VERSION ""

NS_ :

BS_:

BU_: WCM4 WCM3 WCM2 WCM VPM VLM VKM VICM VECM VDM VCU_RTOS_ETH VCU_ENTRY_ETH VCU_AGVM_ETH VCU UVM UPM TIM TEST_TOOL_1 TCP_ETH TCP TCM TCCM SRR_SRR_ETH SRR_SRR SRR_SLR_ETH SRR_SLR SRR_RR SRR_RF_ETH SRR_RF SRR_LR_CR SRR_LF_ETH SRR_LF SIB SDM SCL SBZA_R SBZA_L SBM SAM_RR SAM_RF SAM_LR SAM_LF SAM_BH SADS RadioLow_ETH RadioLow RSI_RTOS_ETH RSI RDCM PTM PLCM PFCM PDR_ETH PDR PCM PA ODS2 ODS NVM MTCM_R MTCM_L MSM_RR MSM_P MSM_LR MSM_D MSB2 MSB1 MRCM_R MRCM_L MFC LRR_RR_ETH LRR_LR_ETH LRR_CF_ETH LRR LRL_CF_ETH LIB_48V LIB1 IPC_INT IPC_GP IPC ICS_Info ICCM HVAC_FP_R HVAC_FP_F HUD_CAN HDLM FPI_RTOS_ETH FPI FOPM FCM_LC FCM EPSb EPS_1 EPSRAb EPSRAa EPS EOCM_HC_Superset EOCM_HCP2 EOCM ELM ECP_X1 ECP_S2 ECP_S ECP_MC ECP_H3 ECP_H2 ECP_H1 ECP_E ECM EBCM DMS DEFC DCM CSM_ETH CSM_AV CSM CGM_OTA_ETH CGM BSM_MH BSM_HEV BSM BCM ARS ARB APA AOS AMP ALC AHS AHL_AFL ADIMb ADIMa ACP2_MCU

BO_ 1515 PDU_5062: 8 RadioLow
 SG_ TAC_AudConctOutcm : 3|4@0+ (1,0) [0|15] "" CGM,TCP
 SG_ TAC_AudChConctStat : 7|4@0+ (1,0) [0|15] "" CGM,TCP
 SG_ TDOSWCCSR_ChgSetReq : 10|3@0+ (1,0) [0|7] "" CGM
 SG_ InfoSysStat : 15|5@0+ (1,0) [0|19] "" AMP,CGM,FPI,HVAC_FP_F,HVAC_FP_R,ICS_Info,PDR,MFC,PLCM,RSI,TCP,IPC,IPC_INT,WCM,WCM2,WCM3,WCM4
 SG_ AutoMemRclCstChgSetReq : 18|3@0+ (1,0) [0|7] "" CGM
 SG_ AdpLghtRspTypCstChgSetReq : 21|3@0+ (1,0) [0|7] "" CGM
 SG_ TDOSWCCSR_IncSwAct : 22|1@0+ (1,0) [0|1] "" CGM
 SG_ TDOSWCCSR_DecSwAct : 23|1@0+ (1,0) [0|1] "" CGM
 SG_ EsyExtCstChgSetReq : 25|3@0+ (1,0) [0|7] "" CGM
 SG_ DrvrAlrtTypCstChgStReq : 28|3@0+ (1,0) [0|7] "" CGM
 SG_ CrgBedVwAutoLgtCstChgSetReq : 31|3@0+ (1,0) [0|2] "" CGM
 SG_ FrwdImpMtgnOpSlctCstChgSetReq : 32|3@0+ (1,0) [0|7] "" CGM
 SG_ FrtRdHgtGPSCstChngSetReq : 35|3@0+ (1,0) [0|7] "" CGM
 SG_ FrntPCMRspTypCstChgSetReq : 38|3@0+ (1,0) [0|7] "" CGM
 SG_ GoNotfrCstChgSetReq : 42|3@0+ (1,0) [0|7] "" CGM
 SG_ GlrFrHgBmRspTypCstChgSetReq : 45|3@0+ (1,0) [0|7] "" CGM
 SG_ PhnLtInVehCstChgSetReq : 49|3@0+ (1,0) [0|7] "" WCM
 SG_ LtRtHnTrCstChgSetReq : 52|3@0+ (1,0) [0|7] "" CGM
 SG_ JckKnfDtnCstChgSetReq : 55|3@0+ (1,0) [0|2] "" CGM
 SG_ APACrssBckInSftBtnStat : 56|1@0+ (1,0) [0|1] "" CGM
 SG_ PrkAsstTrHtchPsntCstChgSetReq : 59|3@0+ (1,0) [0|7] "" CGM
 SG_ PrkAsstOnOffCstChgSetReq : 62|3@0+ (1,0) [0|3] "" CGM

BO_ 1516 PDU_5063: 8 RadioLow
 SG_ RrCrsTrfcAlrtCstChngSetReq : 1|3@0+ (1,0) [0|7] "" CGM
 SG_ RnngBrdManDplyCstChgSetReq : 4|3@0+ (1,0) [0|6] "" CGM
 SG_ RnngBrdAutoDplyCstChgSetReq : 7|3@0+ (1,0) [0|6] "" CGM
 SG_ SBZAlrtCstChngSetReq : 8|3@0+ (1,0) [0|7] "" CGM
 SG_ RrVwPrkAstSymCstChgSetReq : 11|3@0+ (1,0) [0|7] "" CGM
 SG_ RrPCMRspTypCstChgSetReq : 14|3@0+ (1,0) [0|7] "" CGM
 SG_ SrrndVwLghtCstChgSetReq : 18|3@0+ (1,0) [0|7] "" CGM
 SG_ SelUlkCstChgSetReq : 21|3@0+ (1,0) [0|7] "" CGM
 SG_ TnDrvSpdLmtCstChgStReq : 25|3@0+ (1,0) [0|7] "" CGM
 SG_ StBltTghtngCstChgSetReq : 28|3@0+ (1,0) [0|7] "" CGM
 SG_ StBltShfIntlkCstChgSetReq : 31|3@0+ (1,0) [0|7] "" CGM
 SG_ TrlrMirVidEnblCstChgSetReq : 32|3@0+ (1,0) [0|2] "" CGM
 SG_ TrffcLgtAsstCstChgSetReq : 35|3@0+ (1,0) [0|7] "" CGM
 SG_ TnDrvStBltShfIntlkCstChgSetReq : 38|3@0+ (1,0) [0|7] "" CGM
 SG_ VehLctrLtsCstChgSetReq : 42|3@0+ (1,0) [0|7] "" CGM
 SG_ TrlrMirVidGdlnsCstChgSetReq : 45|3@0+ (1,0) [0|2] "" CGM
 SG_ APALftSftBtnStat : 48|1@0+ (1,0) [0|1] "" CGM
 SG_ APAFcStatCSM : 49|1@0+ (1,0) [0|1] "" CGM
 SG_ APAExtPrkSftBtnStat : 50|1@0+ (1,0) [0|1] "" CGM
 SG_ ElvtdIdlCstChgSetReq : 52|2@0+ (1,0) [0|2] "" CGM
 SG_ WlkAwyLckCstChgSetReq : 55|3@0+ (1,0) [0|7] "" CGM
 SG_ TimeDispFormat : 57|1@0+ (1,0) [0|1] "" CGM,ICS_Info,PDR,IPC,IPC_INT
 SG_ RstrCstDfltReq : 58|1@0+ (1,0) [0|1] "" CGM,WCM,WCM2,WCM3,WCM4
 SG_ RFStStsDispActv : 59|1@0+ (1,0) [0|1] "" CGM
 SG_ LFStStsDispActv : 60|1@0+ (1,0) [0|1] "" CGM
 SG_ APASrchSftBtnStat : 61|1@0+ (1,0) [0|1] "" CGM
 SG_ APARghtSftBtnStat : 62|1@0+ (1,0) [0|1] "" CGM
 SG_ APAPrllPrkSftBtnStat : 63|1@0+ (1,0) [0|1] "" CGM

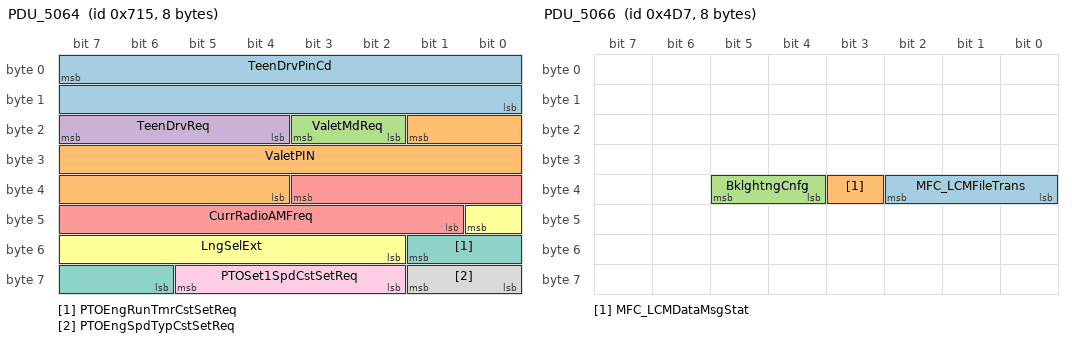
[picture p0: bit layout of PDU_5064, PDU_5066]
BO_ 1813 PDU_5064: 8 RadioLow
 SG_ TeenDrvPinCd : 7|16@0+ (1,0) [0|65535] "" CGM,TCP
 SG_ ValetPIN : 17|14@0+ (1,0) [0|16383] "" CGM
 SG_ ValetMdReq : 19|2@0+ (1,0) [0|2] "" CGM
 SG_ TeenDrvReq : 23|4@0+ (1,0) [0|8] "" CGM,TCP
 SG_ CurrRadioAMFreq : 35|11@0+ (1,0) [0|2047] "KHz" CGM
 SG_ LngSelExt : 40|7@0+ (1,0) [0|43] "" CGM,FPI,PDR,RSI,TCP,IPC,IPC_INT,VCU
 SG_ PTOEngRunTmrCstSetReq : 49|4@0+ (1,0) [0|15] "" CGM
 SG_ PTOEngSpdTypCstSetReq : 57|2@0+ (1,0) [0|2] "" CGM
 SG_ PTOSet1SpdCstSetReq : 61|4@0+ (1,0) [0|15] "" CGM

BO_ 1252 PDU_5065: 6 RadioLow
 SG_ PTOStndbySpdCstSetReq : 0|3@0+ (1,0) [0|7] "" CGM
 SG_ LnChgAlrtCstChngSetReq : 3|3@0+ (1,0) [0|7] "" CGM
 SG_ PTOSet2SpdCstSetReq : 7|4@0+ (1,0) [0|15] "" CGM
 SG_ TCP_LCMFileTrans : 10|3@0+ (1,0) [0|4] "" TCP
 SG_ PTOTpStpSpdCstSetReq : 13|3@0+ (1,0) [0|7] "" CGM
 SG_ TCP_LCMDataMsgStat : 18|1@0+ (1,0) [0|1] "" TCP
 SG_ CamVidICS_DispAct : 19|1@0+ (1,0) [0|1] "" CGM
 SG_ TrlrLtngSeqReq : 21|2@0+ (1,0) [0|2] "" CGM
 SG_ PTOModeCstSetReq : 23|2@0+ (1,0) [0|2] "" CGM
 SG_ VwgVwprtTopDnVwSeltn : 25|3@0+ (1,0) [0|2] "" CGM
 SG_ VwgVwprtZoomBtnSeltd : 26|1@0+ (1,0) [0|1] "" CGM
 SG_ VwgVwprtNtfnFcsReqd : 27|1@0+ (1,0) [0|1] "" CGM
 SG_ VwgVwprtNtfnDsmsReqd : 28|1@0+ (1,0) [0|1] "" CGM
 SG_ TrfcJamAsstVirtCtlReq : 33|2@0+ (1,0) [0|2] "" CGM
 SG_ DrvrSeltdSpdLmtrVirtCtlReqd : 36|1@0+ (1,0) [0|1] "" CGM
 SG_ DrvrSeltdSpdLmtrVirtCtlReq : 38|2@0+ (1,0) [0|3] "" CGM
 SG_ DMBlkhdDrAutoClsTmCstChgSetReq : 45|3@0+ (1,0) [0|3] "" CGM

BO_ 1239 PDU_5066: 8 RadioLow
 SG_ MFC_LCMFileTrans : 34|3@0+ (1,0) [0|4] "" MFC
 SG_ MFC_LCMDataMsgStat : 35|1@0+ (1,0) [0|1] "" MFC
 SG_ BklghtngCnfg : 37|2@0+ (1,0) [0|2] "" MFC

BO_ 706 PDU_5067: 2 RadioLow
 SG_ WCM_LCMDataMsgStat : 4|1@0+ (1,0) [0|1] "" WCM
 SG_ WCM_LCMFileTrans : 7|3@0+ (1,0) [0|4] "" WCM

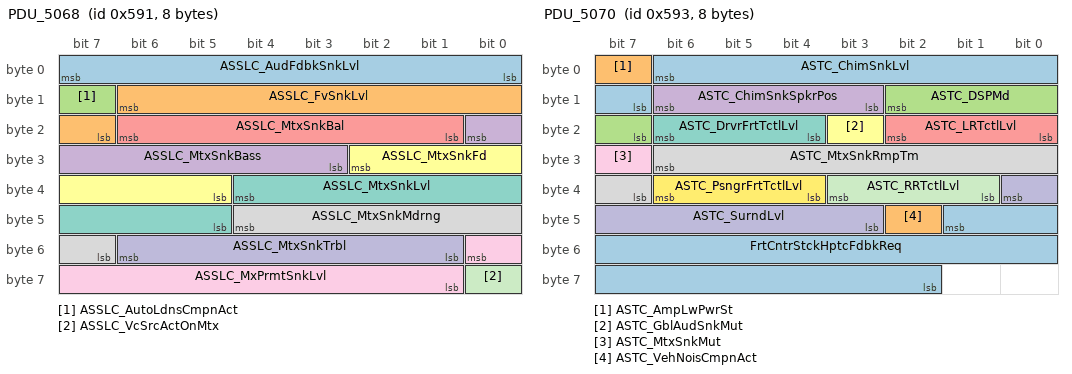
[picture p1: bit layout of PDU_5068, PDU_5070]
BO_ 1425 PDU_5068: 8 CSM
 SG_ ASSLC_AudFdbkSnkLvl : 7|8@0+ (0.5,-127.5) [-127.5|0] "dB" AMP
 SG_ ASSLC_FvSnkLvl : 14|8@0+ (0.5,-127.5) [-127.5|0] "dB" AMP
 SG_ ASSLC_AutoLdnsCmpnAct : 15|1@0+ (1,0) [0|1] "" AMP
 SG_ ASSLC_MtxSnkBass : 16|6@0- (1,0) [-32|31] "" AMP
 SG_ ASSLC_MtxSnkBal : 22|6@0- (1,0) [-32|31] "" AMP
 SG_ ASSLC_MtxSnkFd : 26|6@0- (1,0) [-32|31] "" AMP
 SG_ ASSLC_MtxSnkLvl : 36|8@0+ (0.5,-127.5) [-127.5|0] "dB" AMP
 SG_ ASSLC_MtxSnkMdrng : 44|6@0- (1,0) [-32|31] "" AMP
 SG_ ASSLC_MxPrmtSnkLvl : 48|8@0+ (0.5,-127.5) [-127.5|0] "dB" AMP
 SG_ ASSLC_MtxSnkTrbl : 54|6@0- (1,0) [-32|31] "" AMP
 SG_ ASSLC_VcSrcActOnMtx : 56|1@0+ (1,0) [0|1] "" AMP

BO_ 1426 PDU_5069: 8 CSM
 SG_ ZALC_LRMtxSnkLvl : 7|8@0+ (0.5,-127.5) [-127.5|0] "dB" AMP
 SG_ ZALC_LRMtxSnkRmpTm : 14|8@0+ (5,0) [0|1275] "msec" AMP
 SG_ ZALC_LRMtxSnkMut : 15|1@0+ (1,0) [0|1] "" AMP
 SG_ ZALC_MltZnMixPrmtAudRR : 16|1@0+ (1,0) [0|1] "" AMP
 SG_ ZALC_MltZnMixPrmtAudPsngrFrt : 17|1@0+ (1,0) [0|1] "" AMP
 SG_ ZALC_MltZnMixPrmtAudLR : 18|1@0+ (1,0) [0|1] "" AMP
 SG_ ZALC_MltZnMixPrmtAudDrvrFrt : 19|1@0+ (1,0) [0|1] "" AMP
 SG_ ZALC_MltZnAudFtrStat : 22|3@0+ (1,0) [0|3] "" AMP
 SG_ ZALC_PsngrFrtMtxSnkLvl : 31|8@0+ (0.5,-127.5) [-127.5|0] "dB" AMP
 SG_ ZALC_PsngrFrtMtxSnkRmpTm : 38|8@0+ (5,0) [0|1275] "msec" AMP
 SG_ ZALC_PsngrFrtMtxSnkMut : 39|1@0+ (1,0) [0|1] "" AMP
 SG_ ZALC_RRMtxSnkLvl : 46|8@0+ (0.5,-127.5) [-127.5|0] "dB" AMP
 SG_ ZALC_RRMtxSnkRmpTm : 53|8@0+ (5,0) [0|1275] "msec" AMP
 SG_ ZALC_RRMtxSnkMut : 54|1@0+ (1,0) [0|1] "" AMP
 SG_ FrtCntrStckOptDskDrvDckStat : 58|3@0+ (1,0) [0|7] "" ICS_Info,TCP
 SG_ ZALC_VcSrcActvOnRRMtx : 59|1@0+ (1,0) [0|1] "" AMP
 SG_ ZALC_VcSrcActvOnPsngrFrtMtx : 60|1@0+ (1,0) [0|1] "" AMP
 SG_ ZALC_VcSrcActvOnLRMtx : 61|1@0+ (1,0) [0|1] "" AMP

BO_ 1427 PDU_5070: 8 CSM
 SG_ ASTC_ChimSnkLvl : 6|8@0+ (0.5,-127.5) [-127.5|0] "dB" AMP
 SG_ ASTC_AmpLwPwrSt : 7|1@0+ (1,0) [0|1] "" AMP
 SG_ ASTC_DSPMd : 10|4@0+ (1,0) [0|15] "" AMP
 SG_ ASTC_ChimSnkSpkrPos : 14|4@0+ (1,0) [0|15] "" AMP
 SG_ ASTC_LRTctlLvl : 18|3@0+ (1,0) [0|7] "Counts" AMP
 SG_ ASTC_GblAudSnkMut : 19|1@0+ (1,0) [0|1] "" AMP
 SG_ ASTC_DrvrFrtTctlLvl : 22|3@0+ (1,0) [0|7] "Counts" AMP
 SG_ ASTC_MtxSnkRmpTm : 30|8@0+ (5,0) [0|1275] "ms" AMP
 SG_ ASTC_MtxSnkMut : 31|1@0+ (1,0) [0|1] "" AMP
 SG_ ASTC_SurndLvl : 32|6@0- (1,0) [-32|31] "" AMP
 SG_ ASTC_RRTctlLvl : 35|3@0+ (1,0) [0|7] "Counts" AMP
 SG_ ASTC_PsngrFrtTctlLvl : 38|3@0+ (1,0) [0|7] "Counts" AMP
 SG_ FrtCntrStckHptcFdbkReq : 41|16@0+ (1,0) [0|15] "" ICS_Info
 SG_ ASTC_VehNoisCmpnAct : 42|1@0+ (1,0) [0|1] "" AMP

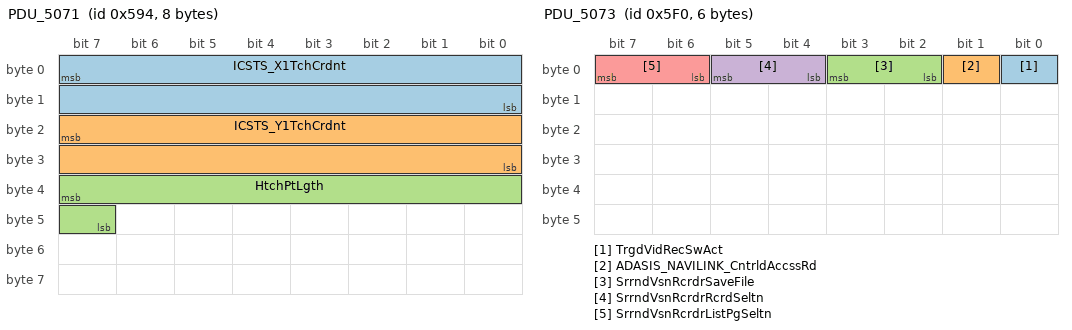
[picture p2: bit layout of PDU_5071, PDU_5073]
BO_ 1428 PDU_5071: 8 CSM
 SG_ ICSTS_X1TchCrdnt : 7|16@0+ (0.001526,0) [0|100.006] "%" CGM,RadioLow
 SG_ ICSTS_Y1TchCrdnt : 23|16@0+ (0.001526,0) [0|100.006] "%" CGM,RadioLow
 SG_ HtchPtLgth : 39|9@0+ (1,0) [0|511] "cm" CGM

BO_ 1519 PDU_5072: 8 CSM
 SG_ VwgBowlVwAngSeltn : 7|9@0+ (1,0) [0|511] "Degree" CGM
 SG_ ADASIS_NAVILINK_DgtlMpEfSpdLm : 8|6@0+ (1,0) [0|31] "" CGM
 SG_ ADASIS_NAVILINK_CntryCd : 14|6@0+ (1,0) [0|51] "" CGM
 SG_ VwgVwprtSeltn : 18|5@0+ (1,0) [0|24] "" CGM
 SG_ SrrndVsnRcrdrListFcs : 25|4@0+ (1,0) [0|11] "" CGM
 SG_ ADASIS_NAVILINK_DgtlMpPsngRst : 29|4@0+ (1,0) [0|7] "" CGM
 SG_ ADASIS_NAVILINK_DgMpCnSpdLmTyp : 33|3@0+ (1,0) [0|7] "" CGM
 SG_ SrrndVsnRcrdrVwprtSeltn : 37|4@0+ (1,0) [0|8] "" CGM
 SG_ SrrndVsnRcrdrFileSeltn : 40|3@0+ (1,0) [0|6] "" CGM
 SG_ SrrndVsnRcrdrFileDeltn : 43|3@0+ (1,0) [0|6] "" CGM
 SG_ PFASndSeltnCstChgSetReq : 46|3@0+ (1,0) [0|7] "" CGM
 SG_ SrrndVsnRcrdrPlybkSeltn : 50|3@0+ (1,0) [0|5] "" CGM
 SG_ SrrndVsnRcrdrPlybkFcs : 53|3@0+ (1,0) [0|6] "" CGM
 SG_ ADASIS_NAVILINK_BldUpFlg : 56|1@0+ (1,0) [0|1] "" CGM
 SG_ PASftBtnSeltdStatRw : 58|2@0+ (1,0) [0|3] "" CGM
 SG_ APASftBtnSeltdStatRw : 60|2@0+ (1,0) [0|3] "" CGM
 SG_ VGS_TrlrActv : 61|1@0+ (1,0) [0|1] "" CGM
 SG_ VGS_DynActv : 62|1@0+ (1,0) [0|1] "" CGM
 SG_ VGS_CurbVwActv : 63|1@0+ (1,0) [0|1] "" CGM

BO_ 1520 PDU_5073: 6 CSM
 SG_ TrgdVidRecSwAct : 0|1@0+ (1,0) [0|1] "" CGM
 SG_ ADASIS_NAVILINK_CntrldAccssRd : 1|1@0+ (1,0) [0|1] "" CGM
 SG_ SrrndVsnRcrdrSaveFile : 3|2@0+ (1,0) [0|2] "" CGM
 SG_ SrrndVsnRcrdrRcrdSeltn : 5|2@0+ (1,0) [0|2] "" CGM
 SG_ SrrndVsnRcrdrListPgSeltn : 7|2@0+ (1,0) [0|3] "" CGM

BO_ 1814 PDU_5074: 8 CSM
 SG_ ONPC_DprtrHrOfDyReq : 4|5@0+ (1,0) [0|31] "h" CGM
 SG_ ONPC_DprtrDyOfWkReq : 7|3@0+ (1,0) [0|7] "" CGM
 SG_ ONPC_Req : 9|2@0+ (1,0) [0|2] "" CGM
 SG_ ONPC_DprtrMinOfHrReq : 15|6@0+ (1,0) [0|63] "min" CGM
 SG_ DAPR_CtlDir : 16|3@0+ (1,0) [0|7] "" AMP
 SG_ ONPC_TgtChrgLvlReq : 23|7@0+ (1,0) [0|127] "%" CGM
 SG_ DAPR_CtlDist : 29|9@0+ (1,0) [0|511] "" AMP
 SG_ DAPR_CurrPrmt : 32|1@0+ (1,0) [0|1] "" AMP
 SG_ DAPR_CtlZn : 36|4@0+ (1,0) [0|15] "" AMP
 SG_ LVMAVC_RmtEnbl : 42|3@0+ (1,0) [0|2] "" PDR
 SG_ LVMAVC_PrmtAudResp : 44|2@0+ (1,0) [0|1] "" PDR
 SG_ LVMAVC_ApplID : 47|3@0+ (1,0) [0|4] "" PDR
 SG_ LVMAVC_StreoAudResp : 48|2@0+ (1,0) [0|1] "" PDR
 SG_ LVMAVC_SpchRcgnAval : 50|2@0+ (1,0) [0|1] "" PDR
 SG_ LVMAVC_RmtSpchRcgnID : 53|3@0+ (1,0) [0|3] "" PDR
 SG_ LVMAVC_RmtSpchRcgnActn : 55|2@0+ (1,0) [0|3] "" PDR
 SG_ OvrrdNextPlndCbnPrcndtngReq : 57|2@0+ (1,0) [0|2] "" CGM
 SG_ RtSdFrtZnAudVolCtlOfst : 62|5@0- (1,0) [-16|15] "" AMP

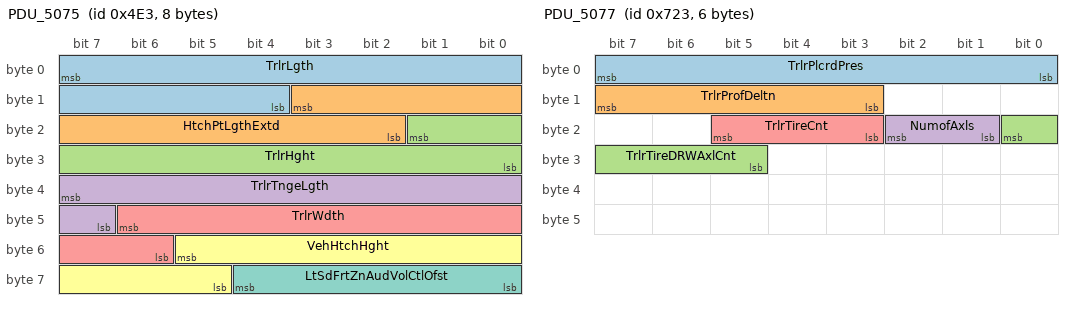
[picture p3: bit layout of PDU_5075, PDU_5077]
BO_ 1251 PDU_5075: 8 CSM
 SG_ TrlrLgth : 7|12@0+ (1,0) [0|4095] "cm" CGM
 SG_ HtchPtLgthExtd : 11|10@0+ (1,1) [1|1024] "cm" CGM
 SG_ TrlrHght : 17|10@0+ (1,0) [0|1023] "cm" CGM
 SG_ TrlrTngeLgth : 39|9@0+ (1,0) [0|511] "cm" CGM
 SG_ TrlrWdth : 46|9@0+ (1,0) [0|511] "cm" CGM
 SG_ VehHtchHght : 53|9@0+ (0.25,0) [0|127.75] "cm" CGM
 SG_ LtSdFrtZnAudVolCtlOfst : 60|5@0- (1,0) [-16|15] "" AMP

BO_ 1815 PDU_5076: 8 CSM
 SG_ VehHtchLgth : 7|9@0+ (0.25,0) [0|127.75] "cm" CGM
 SG_ HMIInCarVcCommCtl : 8|3@0+ (1,0) [0|6] "" AMP
 SG_ AutoTrnspHdActvnCstChgSetReq : 11|3@0+ (1,0) [0|2] "" CGM
 SG_ AutoLnChgCstChgSetReq : 14|3@0+ (1,0) [0|4] "" CGM
 SG_ ChrgPwrLossAlrtCstSetReq : 16|2@0+ (1,0) [0|2] "" CGM
 SG_ ChrgDatReq : 18|2@0+ (1,0) [0|3] "" CGM
 SG_ LocBsdChrgPstnMdfnReq : 21|3@0+ (1,0) [0|4] "" CGM
 SG_ TrlrHtchTyp : 24|2@0+ (1,0) [0|3] "" CGM
 SG_ LocBsdChrgCstSetReq : 26|2@0+ (1,0) [0|2] "" CGM
 SG_ FrtCntrStckVidInSel : 28|2@0+ (1,0) [0|2] "" ICS_Info,PDR,TCP
 SG_ ChrgSysAudblIndCstSetReq : 30|2@0+ (1,0) [0|2] "" CGM
 SG_ Frt360CamSwAct : 32|1@0+ (1,0) [0|1] "" CGM
 SG_ DrvrSeltdTrlrPrsnt : 33|1@0+ (1,0) [0|1] "" CGM
 SG_ DirAudPrmtRndrngEnbld : 34|1@0+ (1,0) [0|1] "" AMP
 SG_ TrlrTyp : 36|2@0+ (1,0) [0|2] "" CGM
 SG_ TrlrStatTowHaulModeOvrrd : 38|2@0+ (1,0) [0|3] "" CGM
 SG_ TrlrAppAux1CamPrvwReqd : 40|1@0+ (1,0) [0|1] "" CGM
 SG_ TrlRvsLghtFldEnbld : 41|1@0+ (1,0) [0|1] "" CGM
 SG_ LifetmEleclEngyEconRstReqd : 42|1@0+ (1,0) [0|1] "" CGM
 SG_ HybTripDatRstReqd : 43|1@0+ (1,0) [0|1] "" CGM
 SG_ HndsFrVcCallActv : 44|1@0+ (1,0) [0|1] "" AMP
 SG_ HiVltgBatStopChrgReq : 45|1@0+ (1,0) [0|1] "" CGM
 SG_ FrtZnAudVolSyncCtlOn : 46|1@0+ (1,0) [0|1] "" AMP
 SG_ FrtCntrStckTchCtlrRstCmd : 47|1@0+ (1,0) [0|1] "" ICS_Info,TCP
 SG_ TrlrProfDrvrReqdSeltn : 48|5@0+ (1,0) [0|21] "" CGM
 SG_ VcRcgnSesnActv : 49|1@0+ (1,0) [0|1] "" AMP
 SG_ TrlrTirePresSnsrIDLrnReqd : 50|1@0+ (1,0) [0|1] "" CGM
 SG_ TrlrTirePresProfXferd : 51|1@0+ (1,0) [0|1] "" CGM
 SG_ TrlrThftAlrtEnbld : 52|1@0+ (1,0) [0|1] "" CGM
 SG_ TrlrLghtAlrtEnbld : 53|1@0+ (1,0) [0|1] "" CGM
 SG_ TrlrAppInvsblTrlrPrvwReqd : 54|1@0+ (1,0) [0|1] "" CGM
 SG_ TrlrAppAux2CamPrvwReqd : 55|1@0+ (1,0) [0|1] "" CGM
 SG_ DMSIntnDrvrCstChgSetReq : 59|3@0+ (1,0) [0|2] "" CGM

BO_ 1827 PDU_5077: 6 CSM
 SG_ TrlrPlcrdPres : 7|8@0+ (4,0) [0|1020] "kPaG" CGM,VKM
 SG_ TrlrProfDeltn : 15|5@0+ (1,0) [0|20] "" CGM
 SG_ TrlrTireDRWAxlCnt : 16|4@0+ (1,0) [0|15] "" CGM
 SG_ NumofAxls : 18|2@0+ (1,0) [0|3] "" CGM
 SG_ TrlrTireCnt : 21|3@0+ (1,0) [0|7] "count" CGM

BO_ 1433 PDU_5078: 6 HVAC_FP_F
 SG_ ReqRrClmtApp : 6|1@0+ (1,0) [0|1] "" RadioLow,CSM,CSM_AV,VCU
 SG_ ReqFrtClmtApp : 7|1@0+ (1,0) [0|1] "" RadioLow,CSM,CSM_AV,VCU

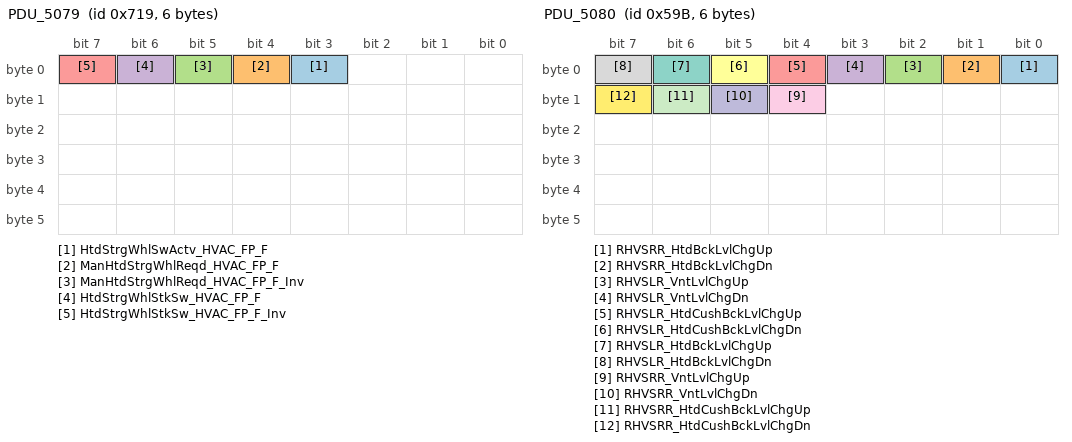
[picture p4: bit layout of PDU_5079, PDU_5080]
BO_ 1817 PDU_5079: 6 HVAC_FP_F
 SG_ HtdStrgWhlSwActv_HVAC_FP_F : 3|1@0+ (1,0) [0|1] "" CGM
 SG_ ManHtdStrgWhlReqd_HVAC_FP_F : 4|1@0+ (1,0) [0|1] "" CGM
 SG_ ManHtdStrgWhlReqd_HVAC_FP_F_Inv : 5|1@0+ (1,0) [0|1] "" CGM
 SG_ HtdStrgWhlStkSw_HVAC_FP_F : 6|1@0+ (1,0) [0|1] "" CGM
 SG_ HtdStrgWhlStkSw_HVAC_FP_F_Inv : 7|1@0+ (1,0) [0|1] "" CGM

BO_ 1435 PDU_5080: 6 HVAC_FP_R
 SG_ RHVSRR_HtdBckLvlChgUp : 0|1@0+ (1,0) [0|1] "" CGM
 SG_ RHVSRR_HtdBckLvlChgDn : 1|1@0+ (1,0) [0|1] "" CGM
 SG_ RHVSLR_VntLvlChgUp : 2|1@0+ (1,0) [0|1] "" CGM
 SG_ RHVSLR_VntLvlChgDn : 3|1@0+ (1,0) [0|1] "" CGM
 SG_ RHVSLR_HtdCushBckLvlChgUp : 4|1@0+ (1,0) [0|1] "" CGM
 SG_ RHVSLR_HtdCushBckLvlChgDn : 5|1@0+ (1,0) [0|1] "" CGM
 SG_ RHVSLR_HtdBckLvlChgUp : 6|1@0+ (1,0) [0|1] "" CGM
 SG_ RHVSLR_HtdBckLvlChgDn : 7|1@0+ (1,0) [0|1] "" CGM
 SG_ RHVSRR_VntLvlChgUp : 12|1@0+ (1,0) [0|1] "" CGM
 SG_ RHVSRR_VntLvlChgDn : 13|1@0+ (1,0) [0|1] "" CGM
 SG_ RHVSRR_HtdCushBckLvlChgUp : 14|1@0+ (1,0) [0|1] "" CGM
 SG_ RHVSRR_HtdCushBckLvlChgDn : 15|1@0+ (1,0) [0|1] "" CGM

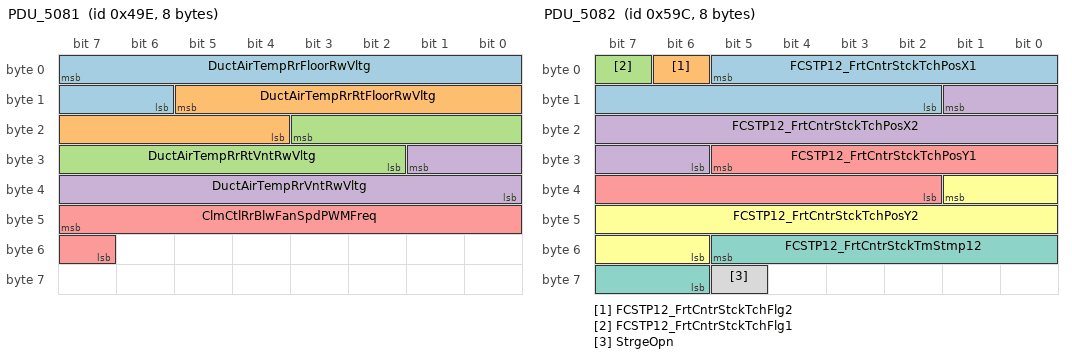
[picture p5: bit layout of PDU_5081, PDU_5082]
BO_ 1182 PDU_5081: 8 HVAC_FP_R
 SG_ DuctAirTempRrFloorRwVltg : 7|10@0+ (0.005,0) [0|5.115] "Volts" CGM
 SG_ DuctAirTempRrRtFloorRwVltg : 13|10@0+ (0.005,0) [0|5.115] "Volts" CGM
 SG_ DuctAirTempRrRtVntRwVltg : 19|10@0+ (0.005,0) [0|5.115] "Volts" CGM
 SG_ DuctAirTempRrVntRwVltg : 25|10@0+ (0.005,0) [0|5.115] "Volts" CGM
 SG_ ClmCtlRrBlwFanSpdPWMFreq : 47|9@0+ (1.56863,0) [0|801.568] "Hz" CGM

BO_ 1436 PDU_5082: 8 ICS_Info
 SG_ FCSTP12_FrtCntrStckTchPosX1 : 5|12@0+ (0.0244141,0) [0|99.9756] "%" PDR,TCP,CSM,CSM_AV,VCU
 SG_ FCSTP12_FrtCntrStckTchFlg2 : 6|1@0+ (1,0) [0|1] "" PDR,TCP,CSM,CSM_AV,VCU
 SG_ FCSTP12_FrtCntrStckTchFlg1 : 7|1@0+ (1,0) [0|1] "" PDR,TCP,CSM,CSM_AV,VCU
 SG_ FCSTP12_FrtCntrStckTchPosX2 : 9|12@0+ (0.0244141,0) [0|99.9756] "%" PDR,TCP,CSM,CSM_AV,VCU
 SG_ FCSTP12_FrtCntrStckTchPosY1 : 29|12@0+ (0.0244141,0) [0|99.9756] "%" PDR,TCP,CSM,CSM_AV,VCU
 SG_ FCSTP12_FrtCntrStckTchPosY2 : 33|12@0+ (0.0244141,0) [0|99.9756] "%" PDR,TCP,CSM,CSM_AV,VCU
 SG_ FCSTP12_FrtCntrStckTmStmp12 : 53|8@0+ (1,0) [0|255] "msec" PDR,TCP,CSM,CSM_AV,VCU
 SG_ StrgeOpn : 61|1@0+ (1,0) [0|1] "" RadioLow,CSM,CSM_AV,VCU

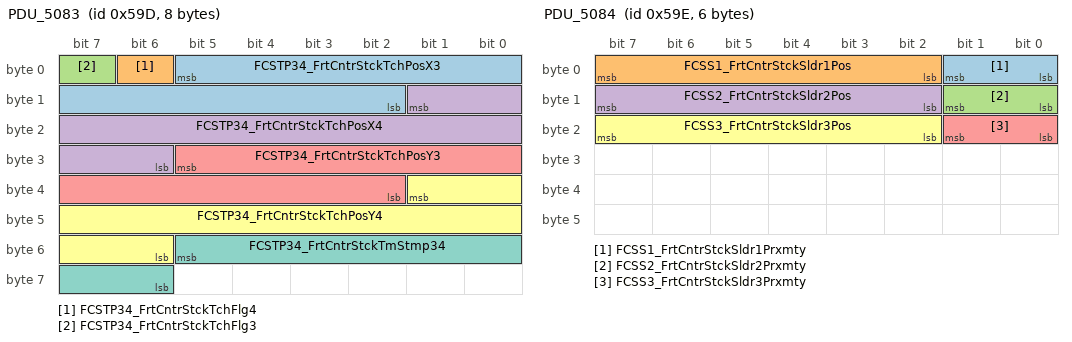
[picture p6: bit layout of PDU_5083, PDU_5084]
BO_ 1437 PDU_5083: 8 ICS_Info
 SG_ FCSTP34_FrtCntrStckTchPosX3 : 5|12@0+ (0.0244141,0) [0|99.9756] "%" PDR,TCP,CSM,CSM_AV,VCU
 SG_ FCSTP34_FrtCntrStckTchFlg4 : 6|1@0+ (1,0) [0|1] "" PDR,TCP,CSM,CSM_AV,VCU
 SG_ FCSTP34_FrtCntrStckTchFlg3 : 7|1@0+ (1,0) [0|1] "" PDR,TCP,CSM,CSM_AV,VCU
 SG_ FCSTP34_FrtCntrStckTchPosX4 : 9|12@0+ (0.0244141,0) [0|99.9756] "%" PDR,TCP,CSM,CSM_AV,VCU
 SG_ FCSTP34_FrtCntrStckTchPosY3 : 29|12@0+ (0.0244141,0) [0|99.9756] "%" PDR,TCP,CSM,CSM_AV,VCU
 SG_ FCSTP34_FrtCntrStckTchPosY4 : 33|12@0+ (0.0244141,0) [0|99.9756] "%" PDR,TCP,CSM,CSM_AV,VCU
 SG_ FCSTP34_FrtCntrStckTmStmp34 : 53|8@0+ (1,0) [0|255] "msec" PDR,TCP,CSM,CSM_AV,VCU

BO_ 1438 PDU_5084: 6 ICS_Info
 SG_ FCSS1_FrtCntrStckSldr1Prxmty : 1|2@0+ (1,0) [0|3] "" TCP,CSM,CSM_AV,VCU
 SG_ FCSS1_FrtCntrStckSldr1Pos : 7|6@0+ (1.5873,0) [0|99.9999] "%" TCP,CSM,CSM_AV,VCU
 SG_ FCSS2_FrtCntrStckSldr2Prxmty : 9|2@0+ (1,0) [0|3] "" TCP,CSM,CSM_AV,VCU
 SG_ FCSS2_FrtCntrStckSldr2Pos : 15|6@0+ (1.5873,0) [0|99.9999] "%" TCP,CSM,CSM_AV,VCU
 SG_ FCSS3_FrtCntrStckSldr3Prxmty : 17|2@0+ (1,0) [0|3] "" TCP,CSM,CSM_AV,VCU
 SG_ FCSS3_FrtCntrStckSldr3Pos : 23|6@0+ (1.5873,0) [0|99.9999] "%" TCP,CSM,CSM_AV,VCU

BO_ 1248 PDU_5085: 6 ICS_Info
 SG_ FrtCntrStckPriVidInLckd : 6|1@0+ (1,0) [0|1] "" PDR,TCP,CSM,CSM_AV
 SG_ FrtCntrStckLVMVidInLckd : 7|1@0+ (1,0) [0|1] "" PDR,TCP,CSM,CSM_AV

BO_ 1818 PDU_5086: 6 IPC
 SG_ AutoTransGrDispdVal : 6|6@0+ (1,0) [0|61] "" CSM,CSM_AV
 SG_ AutoTransGrDispdVal_Inv : 7|1@0+ (1,0) [0|1] "" CSM,CSM_AV

BO_ 930 PDU_5087: 6 IPC
 SG_ ChmMngrStat : 7|12@0+ (1,0) [0|4095] "" CGM,TCP,CSM,CSM_AV

BO_ 723 PDU_5088: 2 IPC
 SG_ JmpStrtReqd : 7|1@0+ (1,0) [0|1] "" CGM

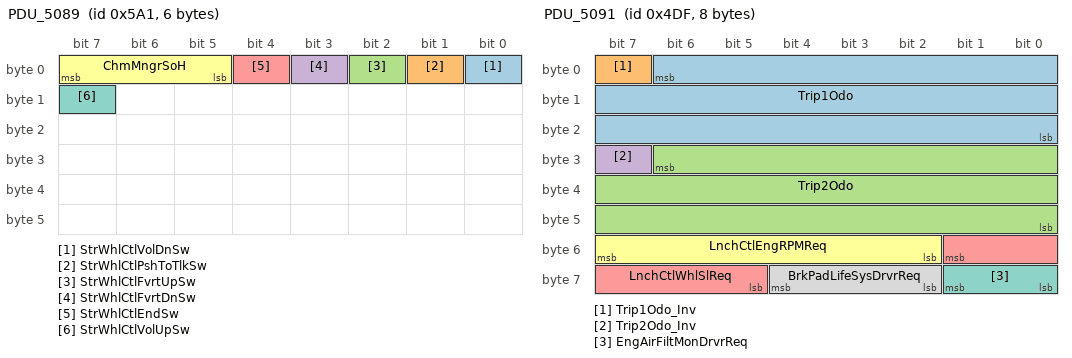
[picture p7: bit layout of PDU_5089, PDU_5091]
BO_ 1441 PDU_5089: 6 IPC
 SG_ StrWhlCtlVolDnSw : 0|1@0+ (1,0) [0|1] "" CGM,RadioLow,CSM,CSM_AV
 SG_ StrWhlCtlPshToTlkSw : 1|1@0+ (1,0) [0|1] "" CGM,RadioLow,CSM,CSM_AV
 SG_ StrWhlCtlFvrtUpSw : 2|1@0+ (1,0) [0|1] "" CGM,RadioLow,CSM,CSM_AV
 SG_ StrWhlCtlFvrtDnSw : 3|1@0+ (1,0) [0|1] "" CGM,RadioLow,CSM,CSM_AV
 SG_ StrWhlCtlEndSw : 4|1@0+ (1,0) [0|1] "" CGM,RadioLow,CSM,CSM_AV
 SG_ ChmMngrSoH : 7|3@0+ (1,0) [0|7] "" RadioLow,CSM,CSM_AV
 SG_ StrWhlCtlVolUpSw : 15|1@0+ (1,0) [0|1] "" CGM,RadioLow,CSM,CSM_AV

BO_ 1522 PDU_5090: 6 IPC
 SG_ HUD_RclCmpt : 0|2@0+ (1,0) [0|2] "" CGM
 SG_ HUD_CustSelActvStat : 1|1@0+ (1,0) [0|1] "" CGM
 SG_ HUD_CustSelActvStat_Inv : 2|1@0+ (1,0) [0|1] "" CGM
 SG_ DispMeasSysExtnd : 4|2@0+ (1,0) [0|3] "" CGM,FPI,PDR,RSI,RadioLow,TCP,VKM,CSM,CSM_AV
 SG_ ClstrAnmStat : 7|3@0+ (1,0) [0|4] "" RadioLow,CSM,CSM_AV
 SG_ PAMutDrvrReq : 8|2@0+ (1,0) [0|2] "" CGM
 SG_ NtVsnVidCntrstUserReq : 10|2@0+ (1,0) [0|3] "" CGM
 SG_ NtVsnVidBrghtnsUserReq : 12|2@0+ (1,0) [0|3] "" CGM
 SG_ IPC_RunCrnkInpActv : 13|1@0+ (1,0) [0|1] "" RadioLow,TCP,CSM,CSM_AV
 SG_ IPC_RunCrnkInpActv_Inv : 14|1@0+ (1,0) [0|1] "" RadioLow,TCP,CSM,CSM_AV
 SG_ StkHUD_CustSelStat : 16|1@0+ (1,0) [0|1] "" CGM
 SG_ FuelFiltLifeRstReqd : 17|1@0+ (1,0) [0|1] "" CGM,TCP
 SG_ DispMeasSys : 18|1@0+ (1,0) [0|1] "" CGM,PDR,RadioLow,TCP,CSM,CSM_AV
 SG_ ClstrHMI_Rdy : 19|1@0+ (1,0) [0|1] "" RadioLow,CSM,CSM_AV
 SG_ APARghtSftBtnStatIPC : 20|1@0+ (1,0) [0|1] "" CGM
 SG_ APALftSftBtnStatIPC : 21|1@0+ (1,0) [0|1] "" CGM
 SG_ APAFcStatIPC : 22|1@0+ (1,0) [0|1] "" CGM
 SG_ AmbtLgtGblPrxmtyEnCstChgSetReq : 26|2@0+ (1,0) [0|2] "" CGM
 SG_ TSMWrngPopUpSts : 27|1@0+ (1,0) [0|1] "" CGM
 SG_ TSMSgnNtfnWrnDispd : 28|1@0+ (1,0) [0|1] "" CGM
 SG_ TSMPageDispActv : 29|1@0+ (1,0) [0|1] "" CGM
 SG_ TSMCustRstReq : 30|1@0+ (1,0) [0|1] "" CGM
 SG_ StrgWhlCtlInCarVcCommCtlSw : 31|1@0+ (1,0) [0|1] "" CGM,RadioLow,CSM,CSM_AV

BO_ 1247 PDU_5091: 8 IPC
 SG_ Trip1Odo : 6|23@0+ (0.015625,0) [0|131072] "Km" FPI,RSI,TCP,VKM
 SG_ Trip1Odo_Inv : 7|1@0+ (1,0) [0|1] "" FPI,RSI,VKM
 SG_ Trip2Odo : 30|23@0+ (0.015625,0) [0|131072] "km" FPI,RSI,TCP,VKM
 SG_ Trip2Odo_Inv : 31|1@0+ (1,0) [0|1] "" FPI,RSI,VKM
 SG_ LnchCtlWhlSlReq : 49|5@0+ (1,0) [0|21] "" CGM
 SG_ LnchCtlEngRPMReq : 55|6@0+ (1,0) [0|38] "" CGM
 SG_ EngAirFiltMonDrvrReq : 57|2@0+ (1,0) [0|3] "" CGM
 SG_ BrkPadLifeSysDrvrReq : 60|3@0+ (1,0) [0|4] "" CGM

BO_ 1819 PDU_5092: 6 IPC
 SG_ TCStmpDsblReqConf : 0|2@0+ (1,0) [0|2] "" CGM
 SG_ TCSCurrStReq : 2|2@0+ (1,0) [0|2] "" CGM
 SG_ LnchCtlModeReq : 4|2@0+ (1,0) [0|3] "" CGM
 SG_ RdHgtAtLocStorConf : 7|3@0+ (1,0) [0|4] "" CGM
 SG_ EngOilLifeRstReq : 8|1@0+ (1,0) [0|1] "" CGM
 SG_ VehStbEnhCurrStReq : 10|2@0+ (1,0) [0|2] "" CGM
 SG_ VehStbCompMdCurrStReq : 12|2@0+ (1,0) [0|2] "" CGM
 SG_ TPMTrLdnRstReq : 14|2@0+ (1,0) [0|3] "" CGM
 SG_ VehFlRngLwIO : 16|1@0+ (1,0) [0|1] "" FPI,RSI,RadioLow,VKM,CSM,CSM_AV
 SG_ TrnsOilLfRstRq : 17|1@0+ (1,0) [0|1] "" CGM
 SG_ TripBEleclEngyEconRstReqd : 18|1@0+ (1,0) [0|1] "" CGM
 SG_ TripAEleclEngyEconRstReqd : 19|1@0+ (1,0) [0|1] "" CGM
 SG_ TPSnsrProgEvReq : 20|1@0+ (1,0) [0|1] "" CGM
 SG_ LnchCtlRelLineLckReqd : 22|1@0+ (1,0) [0|1] "" CGM
 SG_ FobProgEvntRqd : 23|1@0+ (1,0) [0|1] "" CGM
 SG_ ACCAutoSetSpdCstChgSetReq : 27|3@0+ (1,0) [0|2] "" CGM
 SG_ DMSDrwIntnWrnDrvrResp : 28|1@0+ (1,0) [0|1] "" CGM
 SG_ TransOilFiltLifeRstReq : 29|1@0+ (1,0) [0|1] "" CGM
 SG_ CustmStbCtlRdctReqConf : 31|2@0+ (1,0) [0|2] "" CGM

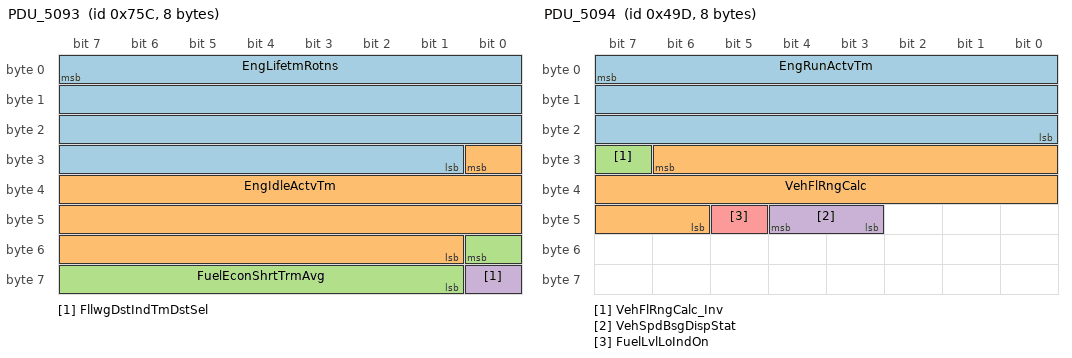
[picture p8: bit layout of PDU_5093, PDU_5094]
BO_ 1884 PDU_5093: 8 IPC
 SG_ EngLifetmRotns : 7|31@0+ (1000,0) [0|2.14748e+012] "rotations" CGM
 SG_ EngIdleActvTm : 24|24@0+ (1,0) [0|1.67772e+007] "min" CGM
 SG_ FuelEconShrtTrmAvg : 48|8@0+ (0.1,0) [0|25.5] "km/L" CGM
 SG_ FllwgDstIndTmDstSel : 56|1@0+ (1,0) [0|1] "" TCP

BO_ 1181 PDU_5094: 8 IPC
 SG_ EngRunActvTm : 7|24@0+ (1,0) [0|1.67772e+007] "min" CGM
 SG_ VehFlRngCalc : 30|17@0+ (0.015625,0) [0|2047.98] "" FPI,RSI,RadioLow,TCP,VKM,CSM,CSM_AV
 SG_ VehFlRngCalc_Inv : 31|1@0+ (1,0) [0|1] "" FPI,RSI,RadioLow,TCP,VKM,CSM,CSM_AV
 SG_ VehSpdBsgDispStat : 44|2@0+ (1,0) [0|2] "" CGM,FPI,RSI
 SG_ FuelLvlLoIndOn : 45|1@0+ (1,0) [0|1] "" CGM,RadioLow,VKM,CSM,CSM_AV

BO_ 1820 PDU_5095: 6 MFC
 SG_ MFCInfoActvnReqd : 7|1@0+ (1,0) [0|1] "" RadioLow,CSM,CSM_AV,VCU

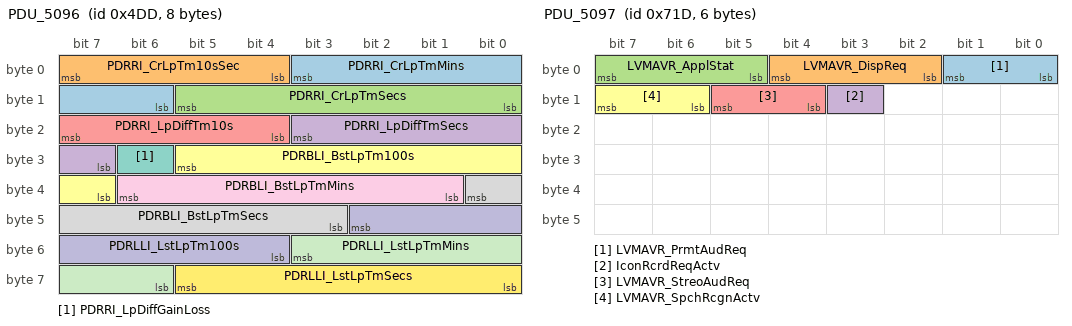
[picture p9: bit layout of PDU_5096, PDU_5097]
BO_ 1245 PDU_5096: 8 PDR
 SG_ PDRRI_CrLpTmMins : 3|6@0+ (1,0) [0|63] "Min" IPC,IPC_INT,VCU
 SG_ PDRRI_CrLpTm10sSec : 7|4@0+ (0.1,0) [0|1.5] "Sec" IPC,IPC_INT,VCU
 SG_ PDRRI_CrLpTmSecs : 13|6@0+ (1,0) [0|63] "Sec" IPC,IPC_INT,VCU
 SG_ PDRRI_LpDiffTmSecs : 19|5@0+ (1,0) [0|31] "Sec" IPC,IPC_INT,VCU
 SG_ PDRRI_LpDiffTm10s : 23|4@0+ (0.1,0) [0|1.5] "Sec" IPC,IPC_INT,VCU
 SG_ PDRBLI_BstLpTm100s : 29|7@0+ (0.01,0) [0|1.27] "Sec" IPC,IPC_INT,VCU
 SG_ PDRRI_LpDiffGainLoss : 30|1@0+ (1,0) [0|1] "" IPC,IPC_INT,VCU
 SG_ PDRBLI_BstLpTmSecs : 32|6@0+ (1,0) [0|63] "Sec" IPC,IPC_INT,VCU
 SG_ PDRBLI_BstLpTmMins : 38|6@0+ (1,0) [0|63] "Min" IPC,IPC_INT,VCU
 SG_ PDRLLI_LstLpTm100s : 42|7@0+ (0.01,0) [0|1.27] "Sec" IPC,IPC_INT,VCU
 SG_ PDRLLI_LstLpTmMins : 51|6@0+ (1,0) [0|63] "Min" IPC,IPC_INT,VCU
 SG_ PDRLLI_LstLpTmSecs : 61|6@0+ (1,0) [0|63] "Sec" IPC,IPC_INT,VCU

BO_ 1821 PDU_5097: 6 PDR
 SG_ LVMAVR_PrmtAudReq : 1|2@0+ (1,0) [0|1] "" CSM,CSM_AV,VCU
 SG_ LVMAVR_DispReq : 4|3@0+ (1,0) [0|3] "" CSM,CSM_AV,VCU
 SG_ LVMAVR_ApplStat : 7|3@0+ (1,0) [0|4] "" CSM,CSM_AV,VCU
 SG_ IconRcrdReqActv : 11|1@0+ (1,0) [0|1] "" CSM,CSM_AV,VCU
 SG_ LVMAVR_StreoAudReq : 13|2@0+ (1,0) [0|1] "" CSM,CSM_AV,VCU
 SG_ LVMAVR_SpchRcgnActv : 15|2@0+ (1,0) [0|2] "" CSM,CSM_AV,VCU

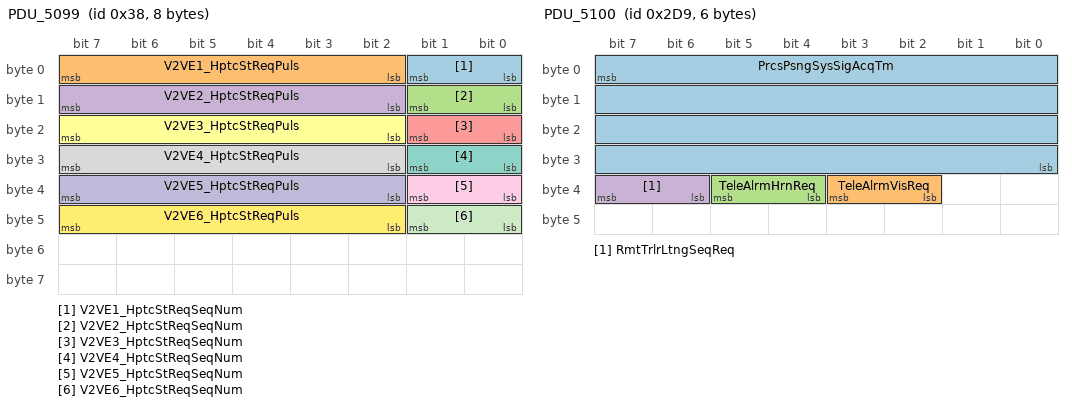
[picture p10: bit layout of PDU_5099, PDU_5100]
BO_ 56 PDU_5099: 8 TCP
 SG_ V2VE1_HptcStReqSeqNum : 1|2@0+ (1,0) [0|3] "Counts" CGM
 SG_ V2VE1_HptcStReqPuls : 7|6@0+ (1,0) [0|63] "Pulses" CGM
 SG_ V2VE2_HptcStReqSeqNum : 9|2@0+ (1,0) [0|3] "Counts" CGM
 SG_ V2VE2_HptcStReqPuls : 15|6@0+ (1,0) [0|63] "Pulses" CGM
 SG_ V2VE3_HptcStReqSeqNum : 17|2@0+ (1,0) [0|3] "Counts" CGM
 SG_ V2VE3_HptcStReqPuls : 23|6@0+ (1,0) [0|63] "Pulses" CGM
 SG_ V2VE4_HptcStReqSeqNum : 25|2@0+ (1,0) [0|3] "Counts" CGM
 SG_ V2VE4_HptcStReqPuls : 31|6@0+ (1,0) [0|63] "Pulses" CGM
 SG_ V2VE5_HptcStReqSeqNum : 33|2@0+ (1,0) [0|3] "Counts" CGM
 SG_ V2VE5_HptcStReqPuls : 39|6@0+ (1,0) [0|63] "Pulses" CGM
 SG_ V2VE6_HptcStReqSeqNum : 41|2@0+ (1,0) [0|3] "Counts" CGM
 SG_ V2VE6_HptcStReqPuls : 47|6@0+ (1,0) [0|63] "Pulses" CGM

BO_ 729 PDU_5100: 6 TCP
 SG_ PrcsPsngSysSigAcqTm : 7|32@0+ (1,0) [0|4.29497e+009] "ms" CSM,CSM_AV,VCU
 SG_ TeleAlrmVisReq : 35|2@0+ (1,0) [0|2] "" CGM
 SG_ TeleAlrmHrnReq : 37|2@0+ (1,0) [0|2] "" CGM
 SG_ RmtTrlrLtngSeqReq : 39|2@0+ (1,0) [0|2] "" CGM

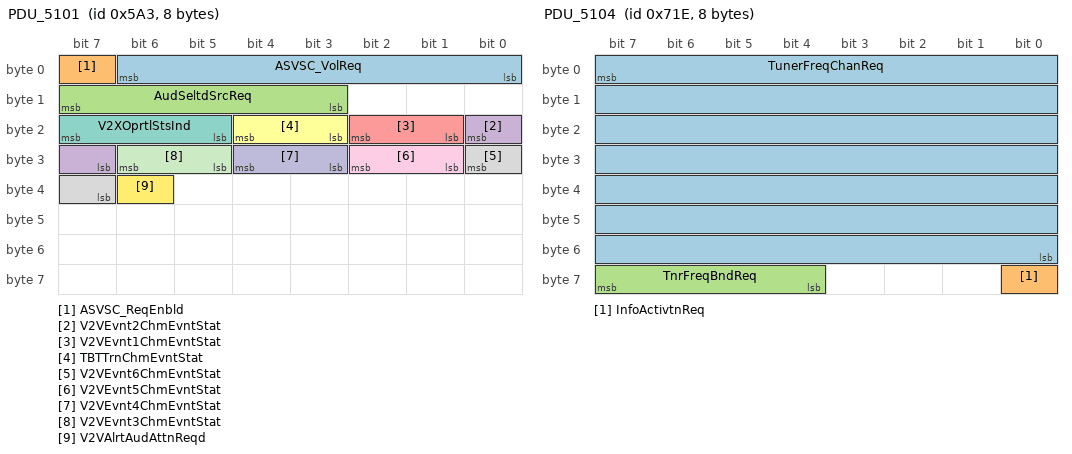
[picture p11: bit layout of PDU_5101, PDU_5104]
BO_ 1443 PDU_5101: 8 TCP
 SG_ ASVSC_VolReq : 6|7@0+ (0.787402,0) [0|100] "" CSM,CSM_AV,VCU
 SG_ ASVSC_ReqEnbld : 7|1@0+ (1,0) [0|1] "" CSM,CSM_AV,VCU
 SG_ AudSeltdSrcReq : 15|5@0+ (1,0) [0|30] "" CSM,CSM_AV,VCU
 SG_ V2VEvnt2ChmEvntStat : 16|2@0+ (1,0) [0|2] "" VCU
 SG_ V2VEvnt1ChmEvntStat : 18|2@0+ (1,0) [0|2] "" VCU
 SG_ TBTTrnChmEvntStat : 20|2@0+ (1,0) [0|2] "" IPC,IPC_INT,VCU
 SG_ V2XOprtlStsInd : 23|3@0+ (1,0) [0|7] "" VCU
 SG_ V2VEvnt6ChmEvntStat : 24|2@0+ (1,0) [0|2] "" VCU
 SG_ V2VEvnt5ChmEvntStat : 26|2@0+ (1,0) [0|2] "" VCU
 SG_ V2VEvnt4ChmEvntStat : 28|2@0+ (1,0) [0|2] "" VCU
 SG_ V2VEvnt3ChmEvntStat : 30|2@0+ (1,0) [0|2] "" VCU
 SG_ V2VAlrtAudAttnReqd : 38|1@0+ (1,0) [0|1] "" VCU

BO_ 1523 PDU_5103: 6 TCP
 SG_ TAR_AudSrcStat : 3|4@0+ (1,0) [0|14] "" CGM,RadioLow,CSM,CSM_AV,VCU
 SG_ TAR_AudConctReq : 7|4@0+ (1,0) [0|15] "" CGM,RadioLow,CSM,CSM_AV,VCU

BO_ 1822 PDU_5104: 8 TCP
 SG_ TunerFreqChanReq : 7|56@0+ (1,0) [0|7.20576e+016] "" CSM,CSM_AV,VCU
 SG_ InfoActivtnReq : 56|1@0+ (1,0) [0|1] "" RadioLow,CSM,CSM_AV,VCU
 SG_ TnrFreqBndReq : 63|4@0+ (1,0) [0|15] "" CSM,CSM_AV,VCU

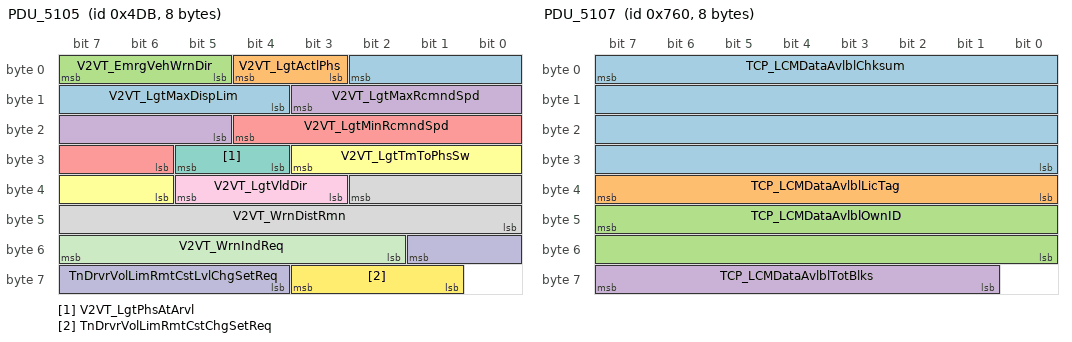
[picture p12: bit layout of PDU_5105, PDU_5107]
BO_ 1243 PDU_5105: 8 TCP
 SG_ V2VT_LgtMaxDispLim : 2|7@0+ (1,0) [0|127] "km/h" VCU
 SG_ V2VT_LgtActlPhs : 4|2@0+ (1,0) [0|3] "" VCU
 SG_ V2VT_EmrgVehWrnDir : 7|3@0+ (1,0) [0|4] "" VCU
 SG_ V2VT_LgtMaxRcmndSpd : 11|7@0+ (1,0) [0|127] "km/h" VCU
 SG_ V2VT_LgtMinRcmndSpd : 20|7@0+ (1,0) [0|127] "km/h" VCU
 SG_ V2VT_LgtTmToPhsSw : 27|6@0+ (1,0) [0|63] "Sec" VCU
 SG_ V2VT_LgtPhsAtArvl : 29|2@0+ (1,0) [0|3] "" VCU
 SG_ V2VT_WrnDistRmn : 34|11@0+ (1,0) [0|2047] "" VCU
 SG_ V2VT_LgtVldDir : 37|3@0+ (1,0) [0|4] "" VCU
 SG_ TnDrvrVolLimRmtCstLvlChgSetReq : 49|6@0+ (1,0) [0|63] "counts" VCU
 SG_ V2VT_WrnIndReq : 55|6@0+ (1,0) [0|9] "" VCU
 SG_ TnDrvrVolLimRmtCstChgSetReq : 59|3@0+ (1,0) [0|2] "" VCU

BO_ 1886 PDU_5106: 6 TCP
 SG_ EmrgRespSysTyp : 7|3@0+ (1,0) [0|6] "" IPC,IPC_INT,VCU

BO_ 1888 PDU_5107: 8 TCP
 SG_ TCP_LCMDataAvlblChksum : 7|32@0+ (1,0) [0|4.29497e+009] "" RadioLow,CSM,CSM_AV,VCU
 SG_ TCP_LCMDataAvlblLicTag : 39|8@0+ (1,0) [0|255] "" RadioLow,CSM,CSM_AV,VCU
 SG_ TCP_LCMDataAvlblOwnID : 47|16@0+ (1,0) [0|65535] "" RadioLow,CSM,CSM_AV,VCU
 SG_ TCP_LCMDataAvlblTotBlks : 63|7@0+ (1,0) [0|127] "" RadioLow,CSM,CSM_AV,VCU

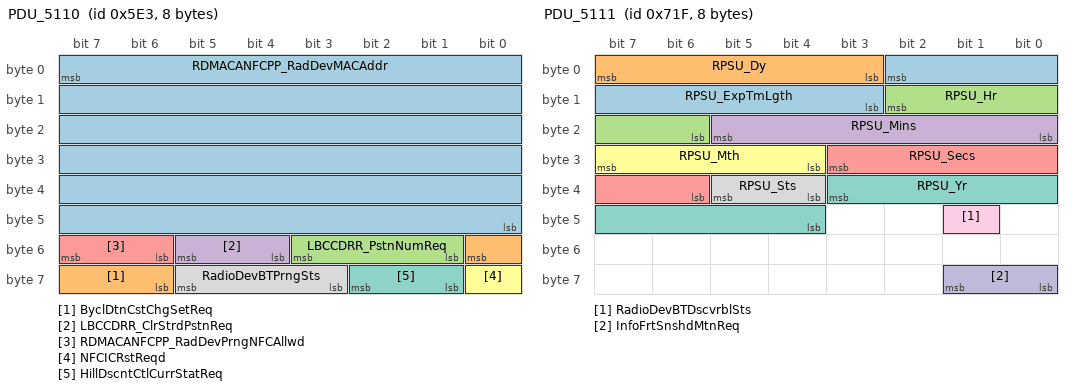
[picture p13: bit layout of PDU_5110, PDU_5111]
BO_ 1507 PDU_5110: 8 CSM
 SG_ RDMACANFCPP_RadDevMACAddr : 7|48@0+ (1,0) [0|281474976710655] "" WCM
 SG_ ByclDtnCstChgSetReq : 48|3@0+ (1,0) [0|2] "" CGM
 SG_ LBCCDRR_PstnNumReq : 51|3@0+ (1,0) [0|4] "" CGM
 SG_ LBCCDRR_ClrStrdPstnReq : 53|2@0+ (1,0) [0|2] "" CGM
 SG_ RDMACANFCPP_RadDevPrngNFCAllwd : 55|2@0+ (1,0) [0|2] "" WCM
 SG_ NFCICRstReqd : 56|1@0+ (1,0) [0|1] "" WCM
 SG_ HillDscntCtlCurrStatReq : 58|2@0+ (1,0) [0|2] "" CGM
 SG_ RadioDevBTPrngSts : 61|3@0+ (1,0) [0|4] "" WCM

BO_ 1823 PDU_5111: 8 VCU
 SG_ RPSU_ExpTmLgth : 2|8@0+ (1,0) [0|255] "min" CGM
 SG_ RPSU_Dy : 7|5@0+ (1,0) [0|31] "day" CGM
 SG_ RPSU_Hr : 10|5@0+ (1,0) [0|31] "hr" CGM
 SG_ RPSU_Mins : 21|6@0+ (1,0) [0|63] "min" CGM
 SG_ RPSU_Secs : 27|6@0+ (1,0) [0|63] "sec" CGM
 SG_ RPSU_Mth : 31|4@0+ (1,0) [0|12] "" CGM
 SG_ RPSU_Yr : 35|8@0+ (1,2000) [2000|2255] "year" CGM
 SG_ RPSU_Sts : 37|2@0+ (1,0) [0|2] "" CGM
 SG_ RadioDevBTDscvrblSts : 41|1@0+ (1,0) [0|1] "" WCM
 SG_ InfoFrtSnshdMtnReq : 57|2@0+ (1,0) [0|2] "" CGM

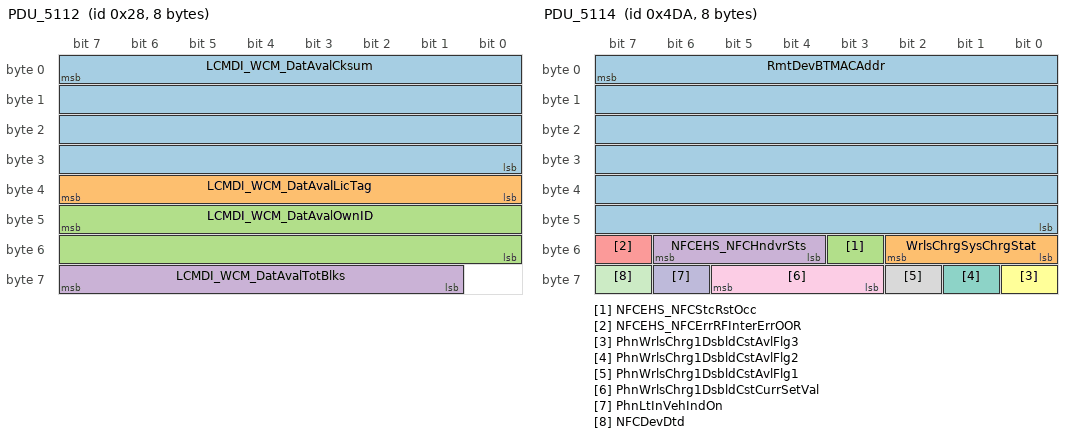
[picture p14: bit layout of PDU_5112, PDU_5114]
BO_ 40 PDU_5112: 8 WCM
 SG_ LCMDI_WCM_DatAvalCksum : 7|32@0+ (1,0) [0|4.29497e+009] "" RadioLow,CSM,CSM_AV,VCU
 SG_ LCMDI_WCM_DatAvalLicTag : 39|8@0+ (1,0) [0|255] "" RadioLow,CSM,CSM_AV,VCU
 SG_ LCMDI_WCM_DatAvalOwnID : 47|16@0+ (1,0) [0|65535] "" RadioLow,CSM,CSM_AV,VCU
 SG_ LCMDI_WCM_DatAvalTotBlks : 63|7@0+ (1,0) [0|127] "" RadioLow,CSM,CSM_AV,VCU

BO_ 1524 PDU_5113: 6 WCM
 SG_ PhnLtInVehCstSetAval : 4|1@0+ (1,0) [0|1] "" RadioLow,CSM,CSM_AV,VCU
 SG_ PhnLtInVehCstCurrSetVal : 7|3@0+ (1,0) [0|7] "" RadioLow,CSM,CSM_AV,VCU

BO_ 1242 PDU_5114: 8 WCM
 SG_ RmtDevBTMACAddr : 7|48@0+ (1,0) [0|281474976710655] "" VCU
 SG_ WrlsChrgSysChrgStat : 50|3@0+ (1,0) [0|7] "" RadioLow,CSM,CSM_AV,VCU
 SG_ NFCEHS_NFCStcRstOcc : 51|1@0+ (1,0) [0|1] "" VCU
 SG_ NFCEHS_NFCHndvrSts : 54|3@0+ (1,0) [0|4] "" VCU
 SG_ NFCEHS_NFCErrRFInterErrOOR : 55|1@0+ (1,0) [0|1] "" VCU
 SG_ PhnWrlsChrg1DsbldCstAvlFlg3 : 56|1@0+ (1,0) [0|1] "" VCU
 SG_ PhnWrlsChrg1DsbldCstAvlFlg2 : 57|1@0+ (1,0) [0|1] "" VCU
 SG_ PhnWrlsChrg1DsbldCstAvlFlg1 : 58|1@0+ (1,0) [0|1] "" VCU
 SG_ PhnWrlsChrg1DsbldCstCurrSetVal : 61|3@0+ (1,0) [0|2] "" VCU
 SG_ PhnLtInVehIndOn : 62|1@0+ (1,0) [0|1] "" IPC,IPC_INT,VCU
 SG_ NFCDevDtd : 63|1@0+ (1,0) [0|1] "" VCU

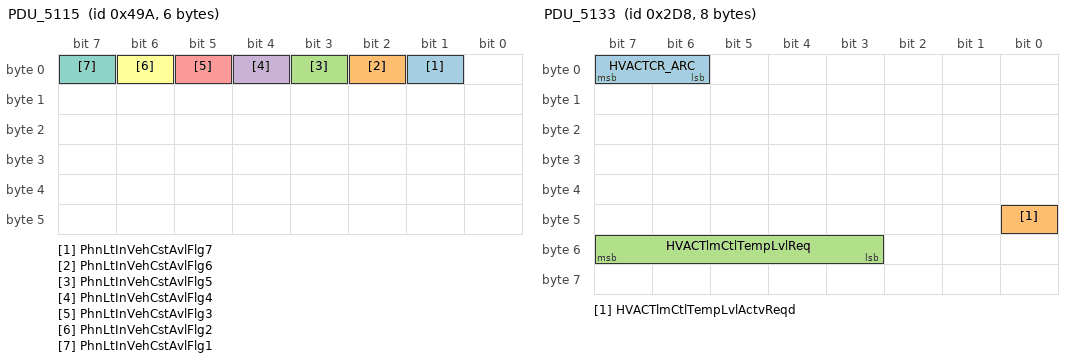
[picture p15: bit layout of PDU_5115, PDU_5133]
BO_ 1178 PDU_5115: 6 WCM
 SG_ PhnLtInVehCstAvlFlg7 : 1|1@0+ (1,0) [0|1] "" RadioLow,CSM,CSM_AV,VCU
 SG_ PhnLtInVehCstAvlFlg6 : 2|1@0+ (1,0) [0|1] "" RadioLow,CSM,CSM_AV,VCU
 SG_ PhnLtInVehCstAvlFlg5 : 3|1@0+ (1,0) [0|1] "" RadioLow,CSM,CSM_AV,VCU
 SG_ PhnLtInVehCstAvlFlg4 : 4|1@0+ (1,0) [0|1] "" RadioLow,CSM,CSM_AV,VCU
 SG_ PhnLtInVehCstAvlFlg3 : 5|1@0+ (1,0) [0|1] "" RadioLow,CSM,CSM_AV,VCU
 SG_ PhnLtInVehCstAvlFlg2 : 6|1@0+ (1,0) [0|1] "" RadioLow,CSM,CSM_AV,VCU
 SG_ PhnLtInVehCstAvlFlg1 : 7|1@0+ (1,0) [0|1] "" RadioLow,CSM,CSM_AV,VCU

BO_ 728 PDU_5133: 8 TCP
 SG_ HVACTCR_ARC : 7|2@0+ (1,0) [0|3] "" Vector__XXX
 SG_ HVACTlmCtlTempLvlActvReqd : 40|1@0+ (1,0) [0|1] "" Vector__XXX
 SG_ HVACTlmCtlTempLvlReq : 55|5@0+ (0.5,16) [16|31.5] "Deg C" Vector__XXX

BO_ 1478 PDU_5135: 6 VCU
 SG_ VCCLR_CrgMirLmp : 1|2@0+ (1,0) [0|2] "" Vector__XXX
 SG_ VCCLR_CrgLmpHtch : 3|2@0+ (1,0) [0|2] "" Vector__XXX
 SG_ VCCLR_CrgLmp : 5|2@0+ (1,0) [0|2] "" Vector__XXX
 SG_ VCCLR_CrgBedLmp : 7|2@0+ (1,0) [0|2] "" Vector__XXX
 SG_ VCDLR_DomeLgt : 8|2@0+ (1,0) [0|2] "" Vector__XXX
 SG_ VCDLR_DomeDft : 10|2@0+ (1,0) [0|2] "" Vector__XXX
 SG_ VirtCtlDrvModeReq : 15|5@0+ (1,0) [0|31] "" Vector__XXX
 SG_ VirtCtlAutoHiBmReq : 17|2@0+ (1,0) [0|2] "" Vector__XXX
 SG_ TireLkDtnUsrReq : 19|2@0+ (1,0) [0|3] "" Vector__XXX
 SG_ VirtCtlTskLmpReq : 22|3@0+ (1,0) [0|4] "" Vector__XXX
 SG_ VirtCtlPwrWndLckoutReq : 25|2@0+ (1,0) [0|2] "" Vector__XXX
 SG_ VirtCtlFgLmpRrReq : 27|2@0+ (1,0) [0|2] "" Vector__XXX
 SG_ VirtCtlFgLmpFrtReq : 29|2@0+ (1,0) [0|2] "" Vector__XXX
 SG_ VirtCtlChldSftyLckReq : 31|2@0+ (1,0) [0|2] "" Vector__XXX
 SG_ StVntdCoolBkLvlLFVirtCtlReq : 33|3@0+ (1,0) [0|4] "" Vector__XXX
 SG_ StHtdCushLvlLFVirtCtlReq : 36|3@0+ (1,0) [0|4] "" Vector__XXX
 SG_ StHtdBkLvlLFVirtCtlReq : 39|3@0+ (1,0) [0|4] "" Vector__XXX
 SG_ StVntdCoolCushLvlLFVirtCtlReq : 46|3@0+ (1,0) [0|4] "" Vector__XXX

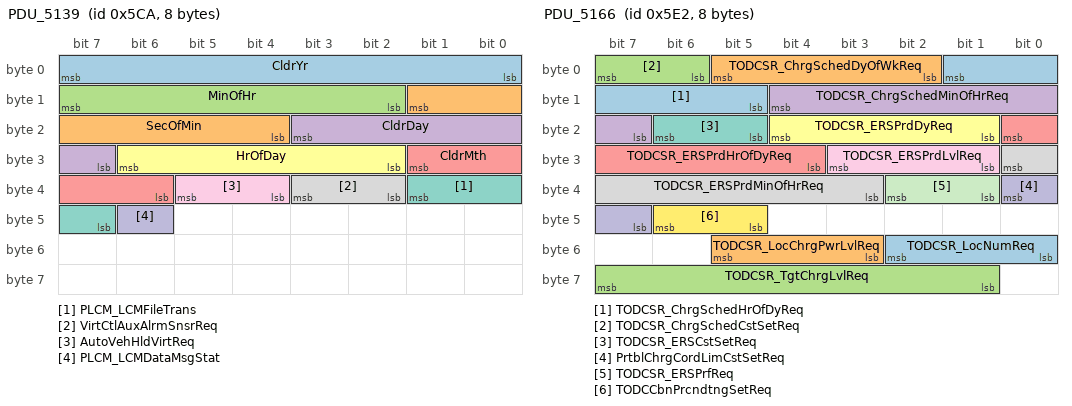
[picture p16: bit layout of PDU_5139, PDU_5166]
BO_ 1482 PDU_5139: 8 RadioLow
 SG_ CldrYr : 7|8@0+ (1,2000) [2000|2255] "year" CGM,FPI,ICS_Info,PDR,RSI,IPC,IPC_INT
 SG_ SecOfMin : 9|6@0+ (1,0) [0|63] "seconds" CGM,FPI,ICS_Info,PDR,RSI,IPC,IPC_INT,VCU
 SG_ MinOfHr : 15|6@0+ (1,0) [0|63] "minutes" CGM,FPI,ICS_Info,PDR,RSI,IPC,IPC_INT,VCU
 SG_ CldrDay : 19|5@0+ (1,0) [0|31] "day" CGM,FPI,ICS_Info,PDR,RSI,IPC,IPC_INT
 SG_ CldrMth : 25|4@0+ (1,0) [0|12] "" CGM,FPI,ICS_Info,PDR,RSI,IPC,IPC_INT
 SG_ HrOfDay : 30|5@0+ (1,0) [0|31] "hour" CGM,FPI,ICS_Info,PDR,RSI,IPC,IPC_INT,VCU
 SG_ PLCM_LCMFileTrans : 33|3@0+ (1,0) [0|4] "" PLCM
 SG_ VirtCtlAuxAlrmSnsrReq : 35|2@0+ (1,0) [0|2] "" CGM
 SG_ AutoVehHldVirtReq : 37|2@0+ (1,0) [0|3] "" CGM
 SG_ PLCM_LCMDataMsgStat : 46|1@0+ (1,0) [0|1] "" PLCM

BO_ 1517 PDU_5163: 8 RadioLow
 SG_ CustMdDrvlCstChngSetReq : 1|3@0+ (1,0) [0|7] "" TCP
 SG_ CustMdBrkPdlCstChngSetReq : 4|3@0+ (1,0) [0|7] "" Vector__XXX
 SG_ CustMdActAeroCstChngSetReq : 7|3@0+ (1,0) [0|7] "" Vector__XXX
 SG_ CustMdSndCstChngSetReq : 8|3@0+ (1,0) [0|7] "" Vector__XXX
 SG_ CustMdRideHghtCstChngSetReq : 11|3@0+ (1,0) [0|7] "" Vector__XXX
 SG_ CustMdPTCstChngSetReq : 14|3@0+ (1,0) [0|7] "" Vector__XXX
 SG_ CustMdStrCstChngSetReq : 18|3@0+ (1,0) [0|7] "" TCP
 SG_ CustMdSpnCstChngSetReq : 21|3@0+ (1,0) [0|7] "" TCP
 SG_ LvlgSysAlgnMdCstChgSetReq : 25|3@0+ (1,0) [0|2] "" Vector__XXX
 SG_ ExtdHillStrtAsstCstChgSetReq : 28|3@0+ (1,0) [0|7] "" Vector__XXX
 SG_ CustMdTrcStbCstChngSetReq : 31|3@0+ (1,0) [0|7] "" Vector__XXX
 SG_ PrsnlMdActAeroCstChngSetReq : 32|3@0+ (1,0) [0|7] "" Vector__XXX
 SG_ LvlgSysServMdCstChgSetReq : 35|3@0+ (1,0) [0|2] "" Vector__XXX
 SG_ LvlgSysEntEgrsMdCstChgSetReq : 38|3@0+ (1,0) [0|2] "" Vector__XXX
 SG_ PrsnlMdDrvlCstChngSetReq : 42|3@0+ (1,0) [0|7] "" TCP
 SG_ PrsnlMdBrkPdlCstChngSetReq : 45|3@0+ (1,0) [0|7] "" Vector__XXX
 SG_ PrsnlMdSpnCstChngSetReq : 49|3@0+ (1,0) [0|7] "" TCP
 SG_ PrsnlMdSndCstChngSetReq : 52|3@0+ (1,0) [0|7] "" Vector__XXX
 SG_ PrsnlMdRideHghtCstChngSetReq : 55|3@0+ (1,0) [0|7] "" Vector__XXX
 SG_ CustmPT_CfgPgAct : 57|1@0+ (1,0) [0|1] "" Vector__XXX
 SG_ DrvrSeltdConf : 59|2@0+ (1,0) [0|3] "" Vector__XXX
 SG_ PrsnlMdStrCstChngSetReq : 62|3@0+ (1,0) [0|7] "" TCP

BO_ 1518 PDU_5164: 8 RadioLow
 SG_ ACCCSR_Aux1Colr : 0|7@0+ (1,0) [0|127] "" Vector__XXX
 SG_ ACCCSR_Aux1Brghtns : 3|3@0+ (1,0) [0|7] "" Vector__XXX
 SG_ ACCCSR_Aux1Anm : 7|4@0+ (1,0) [0|15] "" Vector__XXX
 SG_ ACCCSR_IntrAnm : 9|4@0+ (1,0) [0|15] "" Vector__XXX
 SG_ ACCCSR_IntrColr : 18|7@0+ (1,0) [0|127] "" Vector__XXX
 SG_ ACCCSR_IntrBrghtns : 21|3@0+ (1,0) [0|7] "" Vector__XXX
 SG_ AutDrvLckCstChgSetReq : 24|3@0+ (1,0) [0|7] "" Vector__XXX
 SG_ AirQltySensCstChgSetReq : 27|3@0+ (1,0) [0|7] "" Vector__XXX
 SG_ AutoAirDstCstChgSetReq : 34|3@0+ (1,0) [0|7] "" Vector__XXX
 SG_ AutUnlckCstChgSetReq : 37|3@0+ (1,0) [0|7] "" Vector__XXX
 SG_ AutoFanCstChgSetReq : 41|3@0+ (1,0) [0|7] "" Vector__XXX
 SG_ AutoDfgCstChgSetReq : 44|3@0+ (1,0) [0|7] "" Vector__XXX
 SG_ AutoCoolStCstChgSetReq : 47|3@0+ (1,0) [0|7] "" Vector__XXX
 SG_ AutoRrWpCstChgSetReq : 48|3@0+ (1,0) [0|7] "" Vector__XXX
 SG_ AutoMrFldCstChgSetReq : 51|3@0+ (1,0) [0|7] "" Vector__XXX
 SG_ AutoHtdStCstChgSetReq : 54|3@0+ (1,0) [0|7] "" Vector__XXX
 SG_ ExitLghtngCstChgSetReq : 58|3@0+ (1,0) [0|7] "" Vector__XXX
 SG_ DayTmTlLtsCstChgSetReq : 61|3@0+ (1,0) [0|7] "" Vector__XXX

BO_ 1424 PDU_5165: 8 RadioLow
 SG_ LDCLCstChgSetReq : 1|3@0+ (1,0) [0|7] "" Vector__XXX
 SG_ IonzrCtrlCstChgSetReq : 4|3@0+ (1,0) [0|7] "" Vector__XXX
 SG_ HFRCCstChgSetReq : 7|3@0+ (1,0) [0|7] "" Vector__XXX
 SG_ PsvUnlckCstChgSetReq : 8|3@0+ (1,0) [0|7] "" Vector__XXX
 SG_ PlltnCtrlCstChgSetReq : 11|3@0+ (1,0) [0|7] "" Vector__XXX
 SG_ OpDrAtLOCstChgSetReq : 14|3@0+ (1,0) [0|7] "" Vector__XXX
 SG_ RemInVehRmCstChgSetReq : 18|3@0+ (1,0) [0|7] "" Vector__XXX
 SG_ PwrRrClsrCstChgSetReq : 21|3@0+ (1,0) [0|7] "" Vector__XXX
 SG_ RevTltMrCstChgSetReq : 25|3@0+ (1,0) [0|7] "" Vector__XXX
 SG_ RemWndOpCstChgSetReq : 28|3@0+ (1,0) [0|7] "" Vector__XXX
 SG_ RemLftVehRmCstChgSetReq : 31|3@0+ (1,0) [0|7] "" Vector__XXX
 SG_ RmtStrtCoolStCstChgSetReq : 32|3@0+ (1,0) [0|7] "" Vector__XXX
 SG_ RmtSnrfOpCstChgSetReq : 35|3@0+ (1,0) [0|7] "" Vector__XXX
 SG_ RlkRtUlkDrCstChSetReq : 38|3@0+ (1,0) [0|7] "" Vector__XXX
 SG_ RnSnsCstChgSetReq : 42|3@0+ (1,0) [0|7] "" Vector__XXX
 SG_ RmtStrtHtdStCstChgSetReq : 45|3@0+ (1,0) [0|7] "" Vector__XXX
 SG_ RrZnStUpCstChgSetReq : 49|3@0+ (1,0) [0|7] "" Vector__XXX
 SG_ RrStRmndrEnblDsblCstChgSetReq : 52|3@0+ (1,0) [0|2] "" Vector__XXX
 SG_ RrDfgStUpCstChgSetReq : 55|3@0+ (1,0) [0|7] "" Vector__XXX
 SG_ RtUlkLtFbCstChgSetReq : 59|3@0+ (1,0) [0|7] "" Vector__XXX
 SG_ RtLkFdbkCstChgSetReq : 62|3@0+ (1,0) [0|7] "" Vector__XXX

BO_ 1506 PDU_5166: 8 CSM
 SG_ TODCSR_ChrgSchedHrOfDyReq : 1|5@0+ (1,0) [0|31] "h" Vector__XXX
 SG_ TODCSR_ChrgSchedDyOfWkReq : 5|4@0+ (1,0) [0|10] "" Vector__XXX
 SG_ TODCSR_ChrgSchedCstSetReq : 7|2@0+ (1,0) [0|2] "" Vector__XXX
 SG_ TODCSR_ChrgSchedMinOfHrReq : 12|6@0+ (1,0) [0|63] "min" Vector__XXX
 SG_ TODCSR_ERSPrdHrOfDyReq : 16|5@0+ (1,0) [0|31] "h" Vector__XXX
 SG_ TODCSR_ERSPrdDyReq : 20|4@0+ (1,0) [0|10] "" Vector__XXX
 SG_ TODCSR_ERSCstSetReq : 22|2@0+ (1,0) [0|2] "" Vector__XXX
 SG_ TODCSR_ERSPrdMinOfHrReq : 24|6@0+ (1,0) [0|63] "min" Vector__XXX
 SG_ TODCSR_ERSPrdLvlReq : 27|3@0+ (1,0) [0|5] "" Vector__XXX
 SG_ PrtblChrgCordLimCstSetReq : 32|2@0+ (1,0) [0|2] "" Vector__XXX
 SG_ TODCSR_ERSPrfReq : 34|2@0+ (1,0) [0|3] "" Vector__XXX
 SG_ TODCCbnPrcndtngSetReq : 46|2@0+ (1,0) [0|2] "" Vector__XXX
 SG_ TODCSR_LocNumReq : 50|3@0+ (1,0) [0|5] "" Vector__XXX
 SG_ TODCSR_LocChrgPwrLvlReq : 53|3@0+ (1,0) [0|4] "" Vector__XXX
 SG_ TODCSR_TgtChrgLvlReq : 63|7@0+ (1,0) [0|127] "%" Vector__XXX

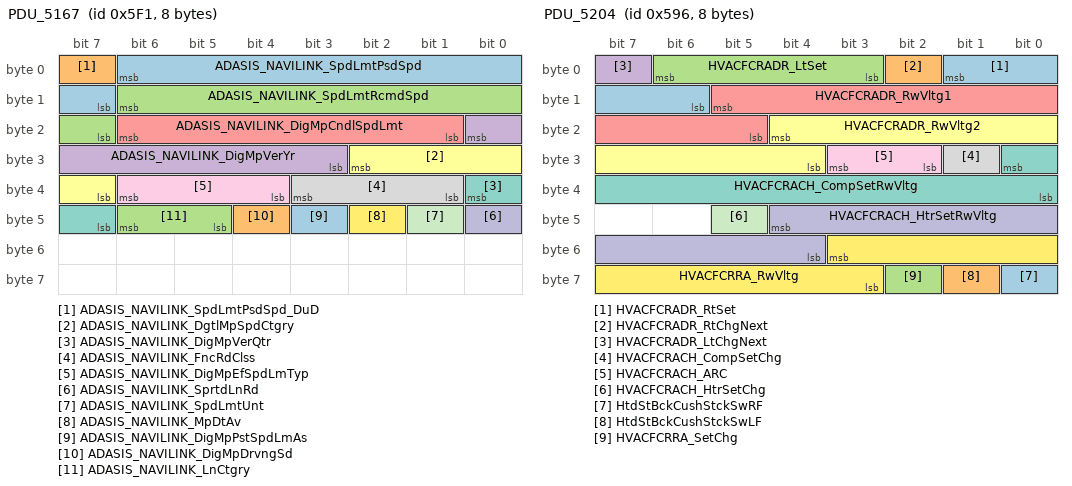
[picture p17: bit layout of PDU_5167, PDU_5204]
BO_ 1521 PDU_5167: 8 CSM
 SG_ ADASIS_NAVILINK_SpdLmtPsdSpd : 6|8@0+ (1,0) [0|255] "" IPC,IPC_INT
 SG_ ADASIS_NAVILINK_SpdLmtPsdSpd_DuD : 7|1@0+ (1,0) [0|1] "" IPC,IPC_INT
 SG_ ADASIS_NAVILINK_SpdLmtRcmdSpd : 14|8@0+ (1,0) [0|255] "" IPC,IPC_INT
 SG_ ADASIS_NAVILINK_DigMpVerYr : 16|6@0+ (1,0) [0|63] "" Vector__XXX
 SG_ ADASIS_NAVILINK_DigMpCndlSpdLmt : 22|6@0+ (1,0) [0|31] "" Vector__XXX
 SG_ ADASIS_NAVILINK_DgtlMpSpdCtgry : 26|4@0+ (1,0) [0|8] "" Vector__XXX
 SG_ ADASIS_NAVILINK_DigMpVerQtr : 32|2@0+ (1,0) [0|3] "" Vector__XXX
 SG_ ADASIS_NAVILINK_FncRdClss : 35|3@0+ (1,0) [0|7] "" Vector__XXX
 SG_ ADASIS_NAVILINK_DigMpEfSpdLmTyp : 38|3@0+ (1,0) [0|7] "" Vector__XXX
 SG_ ADASIS_NAVILINK_SprtdLnRd : 40|1@0+ (1,0) [0|1] "" Vector__XXX
 SG_ ADASIS_NAVILINK_SpdLmtUnt : 41|1@0+ (1,0) [0|1] "" IPC,IPC_INT
 SG_ ADASIS_NAVILINK_MpDtAv : 42|1@0+ (1,0) [0|1] "" Vector__XXX
 SG_ ADASIS_NAVILINK_DigMpPstSpdLmAs : 43|1@0+ (1,0) [0|1] "" Vector__XXX
 SG_ ADASIS_NAVILINK_DigMpDrvngSd : 44|1@0+ (1,0) [0|1] "" Vector__XXX
 SG_ ADASIS_NAVILINK_LnCtgry : 46|2@0+ (1,0) [0|3] "" Vector__XXX

BO_ 1250 PDU_5168: 8 CSM
 SG_ TrlrTirePresLFXferdSnsrID : 7|32@0+ (1,0) [0|4.29497e+009] "" Vector__XXX
 SG_ TrlrTirePresLRXferdSnsrID : 39|32@0+ (1,0) [0|4.29497e+009] "" Vector__XXX

BO_ 1816 PDU_5169: 8 CSM
 SG_ TrlrTirePresRFXferdSnsrID : 7|32@0+ (1,0) [0|4.29497e+009] "" Vector__XXX
 SG_ TrlrTirePresRRXferdSnsrID : 39|32@0+ (1,0) [0|4.29497e+009] "" Vector__XXX

BO_ 1249 PDU_5170: 8 CSM
 SG_ TrlrTirePresLtMdlXferdSnsrID : 7|32@0+ (1,0) [0|4.29497e+009] "" Vector__XXX
 SG_ TrlrTirePresRtMdlXferdSnsrID : 39|32@0+ (1,0) [0|4.29497e+009] "" Vector__XXX

BO_ 1434 PDU_5202: 8 HVAC_FP_R
 SG_ ReqTmpChgRRRr : 0|7@0- (1,0) [-64|63] "" Vector__XXX
 SG_ ReqTmpChgRLRr : 7|7@0- (1,0) [-64|63] "" Vector__XXX
 SG_ ReqTmpLvlRLRr : 9|7@0+ (1,-16) [-16|111] "" Vector__XXX
 SG_ ReqTmpLvlRRRr : 18|7@0+ (1,-16) [-16|111] "" Vector__XXX
 SG_ ReqBlwLvlChgRrRr : 27|5@0- (1,0) [-16|15] "" Vector__XXX
 SG_ ReqAirDstRRRr : 34|4@0+ (1,0) [0|8] "" Vector__XXX
 SG_ ReqAirDstRLRr : 38|4@0+ (1,0) [0|8] "" Vector__XXX
 SG_ HtdStBckCushStckSwLR : 40|1@0+ (1,0) [0|1] "" Vector__XXX
 SG_ RrAirHandlingDrActrPwrFdbk : 42|2@0+ (1,0) [0|2] "" Vector__XXX
 SG_ ReqBlwLvlRrRr : 46|4@0+ (1,0) [0|15] "" Vector__XXX
 SG_ ReqBlwLvlRrAtvRr : 48|1@0+ (1,0) [0|1] "" Vector__XXX
 SG_ ReqAirDstChgNxtRRRr : 49|1@0+ (1,0) [0|1] "" Vector__XXX
 SG_ ReqAirDstChgNxtRLRr : 50|1@0+ (1,0) [0|1] "" Vector__XXX
 SG_ HtdVntStSwActvRR : 51|1@0+ (1,0) [0|1] "" Vector__XXX
 SG_ HtdVntStSwActvLR : 52|1@0+ (1,0) [0|1] "" Vector__XXX
 SG_ HtdStBckStckSwRR : 53|1@0+ (1,0) [0|1] "" Vector__XXX
 SG_ HtdStBckStckSwLR : 54|1@0+ (1,0) [0|1] "" Vector__XXX
 SG_ HtdStBckCushStckSwRR : 55|1@0+ (1,0) [0|1] "" Vector__XXX
 SG_ VntStStckSwRR : 56|1@0+ (1,0) [0|1] "" Vector__XXX
 SG_ VntStStckSwLR : 57|1@0+ (1,0) [0|1] "" Vector__XXX
 SG_ RrHVACCtrlInitFin : 58|1@0+ (1,0) [0|1] "" Vector__XXX
 SG_ ReqTmpLvlRRAtvRr : 59|1@0+ (1,0) [0|1] "" Vector__XXX
 SG_ ReqTmpLvlRLAtvRr : 60|1@0+ (1,0) [0|1] "" Vector__XXX
 SG_ ReqSYNC_RrChgRr : 61|1@0+ (1,0) [0|1] "" Vector__XXX
 SG_ ReqRrHVAC_PwrChgRr : 62|1@0+ (1,0) [0|1] "" Vector__XXX
 SG_ ReqRrAutoRr : 63|1@0+ (1,0) [0|1] "" Vector__XXX

BO_ 1430 PDU_5204: 8 HVAC_FP_F
 SG_ HVACFCRADR_RtSet : 1|4@0+ (1,0) [0|8] "" Vector__XXX
 SG_ HVACFCRADR_RtChgNext : 2|1@0+ (1,0) [0|1] "" Vector__XXX
 SG_ HVACFCRADR_LtSet : 6|4@0+ (1,0) [0|8] "" Vector__XXX
 SG_ HVACFCRADR_LtChgNext : 7|1@0+ (1,0) [0|1] "" Vector__XXX
 SG_ HVACFCRADR_RwVltg1 : 13|9@0+ (0.01,0) [0|5.11] "Volts" Vector__XXX
 SG_ HVACFCRADR_RwVltg2 : 20|9@0+ (0.01,0) [0|5.11] "Volts" Vector__XXX
 SG_ HVACFCRACH_CompSetRwVltg : 24|9@0+ (0.01,0) [0|5.11] "Volts" Vector__XXX
 SG_ HVACFCRACH_CompSetChg : 25|1@0+ (1,0) [0|1] "" Vector__XXX
 SG_ HVACFCRACH_ARC : 27|2@0+ (1,0) [0|3] "Counts" Vector__XXX
 SG_ HVACFCRACH_HtrSetRwVltg : 44|9@0+ (0.01,0) [0|5.11] "Volts" Vector__XXX
 SG_ HVACFCRACH_HtrSetChg : 45|1@0+ (1,0) [0|1] "" Vector__XXX
 SG_ HVACFCRRA_RwVltg : 51|9@0+ (0.01,0) [0|5.11] "Volts" Vector__XXX
 SG_ HtdStBckCushStckSwRF : 56|1@0+ (1,0) [0|1] "" Vector__XXX
 SG_ HtdStBckCushStckSwLF : 57|1@0+ (1,0) [0|1] "" Vector__XXX
 SG_ HVACFCRRA_SetChg : 58|1@0+ (1,0) [0|1] "" Vector__XXX

BO_ 1431 PDU_5205: 8 HVAC_FP_F
 SG_ HVACFCRBLR_LvlChg : 2|5@0- (1,0) [-16|15] "" Vector__XXX
 SG_ HVACFCRBLR_LvlActv : 3|1@0+ (1,0) [0|1] "" Vector__XXX
 SG_ HVACFCRBLR_Lvl : 7|4@0+ (1,0) [0|15] "" Vector__XXX
 SG_ HVACFCRBLR_RwVltg1 : 13|9@0+ (0.01,0) [0|5.11] "Volts" Vector__XXX
 SG_ HVACFCRBLR_RwVltg2 : 20|9@0+ (0.01,0) [0|5.11] "Volts" Vector__XXX
 SG_ HVACFCRRD_RwVltg : 27|9@0+ (0.01,0) [0|5.11] "Volts" Vector__XXX
 SG_ HVACFCRRP_RwVltg : 33|9@0+ (0.01,0) [0|5.11] "Volts" Vector__XXX
 SG_ HVACFCRRD_SetChg : 34|1@0+ (1,0) [0|1] "" Vector__XXX
 SG_ HVACFCRRP_SetChg : 40|1@0+ (1,0) [0|1] "" Vector__XXX
 SG_ HVACFCRSA_RwVltg : 55|9@0+ (0.01,0) [0|5.11] "Volts" Vector__XXX
 SG_ VntStStckSwLF : 56|1@0+ (1,0) [0|1] "" Vector__XXX
 SG_ HtdVntStSwActvRF : 57|1@0+ (1,0) [0|1] "" Vector__XXX
 SG_ HtdVntStSwActvLF : 58|1@0+ (1,0) [0|1] "" Vector__XXX
 SG_ HtdStBckStckSwRF : 59|1@0+ (1,0) [0|1] "" Vector__XXX
 SG_ HtdStBckStckSwLF : 60|1@0+ (1,0) [0|1] "" Vector__XXX
 SG_ HVACFrtCtlReqSyncRrSetChg : 61|1@0+ (1,0) [0|1] "" Vector__XXX
 SG_ HVACFCRSA_SetChg : 62|1@0+ (1,0) [0|1] "" Vector__XXX

BA_DEF_ SG_  "SignalType" STRING ;
BA_DEF_ SG_  "SignalLongName" STRING ;
BA_DEF_ BO_  "GenMsgCycleTime" INT 0 10000;
BA_DEF_ BO_  "GenMsgSendType" ENUM "cyclicX","spontanX","cyclicIfActiveX","spontanWithDelay","cyclicAndSpontanX","cyclicAndSpontanWithDelay","spontanWithRepetition","cyclicIfActiveAndSpontanWD";
BA_DEF_DEF_  "SignalType" "";
BA_DEF_DEF_  "SignalLongName" "";
BA_DEF_DEF_  "GenMsgCycleTime" 0;
BA_DEF_DEF_  "GenMsgSendType" "cyclicX";
BA_ "GenMsgCycleTime" BO_ 1515 1000;
BA_ "GenMsgCycleTime" BO_ 1516 1000;
BA_ "GenMsgCycleTime" BO_ 1813 1000;
BA_ "GenMsgCycleTime" BO_ 1252 1000;
BA_ "GenMsgCycleTime" BO_ 1239 1000;
BA_ "GenMsgCycleTime" BO_ 1425 1000;
BA_ "GenMsgCycleTime" BO_ 1426 1000;
BA_ "GenMsgCycleTime" BO_ 1427 1000;
BA_ "GenMsgCycleTime" BO_ 1428 1000;
BA_ "GenMsgCycleTime" BO_ 1519 1000;
BA_ "GenMsgCycleTime" BO_ 1520 1000;
BA_ "GenMsgCycleTime" BO_ 1814 1000;
BA_ "GenMsgCycleTime" BO_ 1251 1000;
BA_ "GenMsgCycleTime" BO_ 1815 1000;
BA_ "GenMsgCycleTime" BO_ 1827 1000;
BA_ "GenMsgCycleTime" BO_ 1433 1000;
BA_ "GenMsgCycleTime" BO_ 1817 1000;
BA_ "GenMsgCycleTime" BO_ 1435 1000;
BA_ "GenMsgCycleTime" BO_ 1182 1000;
BA_ "GenMsgCycleTime" BO_ 1436 1000;
BA_ "GenMsgCycleTime" BO_ 1437 1000;
BA_ "GenMsgCycleTime" BO_ 1438 1000;
BA_ "GenMsgCycleTime" BO_ 1248 1000;
BA_ "GenMsgCycleTime" BO_ 1818 1000;
BA_ "GenMsgCycleTime" BO_ 930 250;
BA_ "GenMsgCycleTime" BO_ 723 100;
BA_ "GenMsgCycleTime" BO_ 1441 1000;
BA_ "GenMsgCycleTime" BO_ 1522 1000;
BA_ "GenMsgCycleTime" BO_ 1247 1000;
BA_ "GenMsgCycleTime" BO_ 1819 1000;
BA_ "GenMsgCycleTime" BO_ 1884 1000;
BA_ "GenMsgCycleTime" BO_ 1181 1000;
BA_ "GenMsgCycleTime" BO_ 1820 1000;
BA_ "GenMsgCycleTime" BO_ 1245 1000;
BA_ "GenMsgCycleTime" BO_ 1821 1000;
BA_ "GenMsgCycleTime" BO_ 56 10;
BA_ "GenMsgCycleTime" BO_ 729 100;
BA_ "GenMsgCycleTime" BO_ 1443 1000;
BA_ "GenMsgCycleTime" BO_ 1523 1000;
BA_ "GenMsgCycleTime" BO_ 1822 1000;
BA_ "GenMsgCycleTime" BO_ 1243 1000;
BA_ "GenMsgCycleTime" BO_ 1886 1000;
BA_ "GenMsgCycleTime" BO_ 1507 1000;
BA_ "GenMsgCycleTime" BO_ 1823 1000;
BA_ "GenMsgCycleTime" BO_ 1524 1000;
BA_ "GenMsgCycleTime" BO_ 1242 1000;
BA_ "GenMsgCycleTime" BO_ 1178 1000;
BA_ "GenMsgCycleTime" BO_ 728 100;
BA_ "GenMsgCycleTime" BO_ 1478 1000;
BA_ "GenMsgCycleTime" BO_ 1482 1000;
BA_ "GenMsgCycleTime" BO_ 1517 1000;
BA_ "GenMsgCycleTime" BO_ 1518 1000;
BA_ "GenMsgCycleTime" BO_ 1424 1000;
BA_ "GenMsgCycleTime" BO_ 1506 1000;
BA_ "GenMsgCycleTime" BO_ 1521 1000;
BA_ "GenMsgCycleTime" BO_ 1250 1000;
BA_ "GenMsgCycleTime" BO_ 1816 1000;
BA_ "GenMsgCycleTime" BO_ 1249 1000;
BA_ "GenMsgCycleTime" BO_ 1434 1000;
BA_ "GenMsgCycleTime" BO_ 1430 1000;
BA_ "GenMsgCycleTime" BO_ 1431 1000;
BA_ "SignalType" SG_ 1515 TAC_AudConctOutcm "ENM";
BA_ "SignalLongName" SG_ 1515 TAC_AudConctOutcm "Telematics Audio Control : Audio Connection Outcome";
BA_ "SignalType" SG_ 1515 TAC_AudChConctStat "ENM";
BA_ "SignalLongName" SG_ 1515 TAC_AudChConctStat "Telematics Audio Control : Audio Channel Connection State";
BA_ "SignalType" SG_ 1515 TDOSWCCSR_ChgSetReq "ENM";
BA_ "SignalLongName" SG_ 1515 TDOSWCCSR_ChgSetReq "Teen Driver Overspeed Warning Customization Change Setting Request : Change Setting Request";
BA_ "SignalType" SG_ 1515 InfoSysStat "ENM";
BA_ "SignalLongName" SG_ 1515 InfoSysStat "Infotainment System State";
BA_ "SignalType" SG_ 1515 AutoMemRclCstChgSetReq "ENM";
BA_ "SignalLongName" SG_ 1515 AutoMemRclCstChgSetReq "Auto Memory Recall Customization Change Setting Request";
BA_ "SignalType" SG_ 1515 AdpLghtRspTypCstChgSetReq "ENM";
BA_ "SignalLongName" SG_ 1515 AdpLghtRspTypCstChgSetReq "Adaptive Lighting Response Type Customization Change Setting Request";
BA_ "SignalType" SG_ 1515 TDOSWCCSR_IncSwAct "ENM";
BA_ "SignalLongName" SG_ 1515 TDOSWCCSR_IncSwAct "Teen Driver Overspeed Warning Customization Change Setting Request : Increment Switch Active";
BA_ "SignalType" SG_ 1515 TDOSWCCSR_DecSwAct "ENM";
BA_ "SignalLongName" SG_ 1515 TDOSWCCSR_DecSwAct "Teen Driver Overspeed Warning Customization Change Setting Request : Decrement Switch Active";
BA_ "SignalType" SG_ 1515 EsyExtCstChgSetReq "ENM";
BA_ "SignalLongName" SG_ 1515 EsyExtCstChgSetReq "Easy Exit Customization Change Setting Request";
BA_ "SignalType" SG_ 1515 DrvrAlrtTypCstChgStReq "ENM";
BA_ "SignalLongName" SG_ 1515 DrvrAlrtTypCstChgStReq "Driver Alert Type Customization Change Setting Request";
BA_ "SignalType" SG_ 1515 CrgBedVwAutoLgtCstChgSetReq "ENM";
BA_ "SignalLongName" SG_ 1515 CrgBedVwAutoLgtCstChgSetReq "Cargo Bed View Auto Lighting Customization Change Setting Request";
BA_ "SignalType" SG_ 1515 FrwdImpMtgnOpSlctCstChgSetReq "ENM";
BA_ "SignalLongName" SG_ 1515 FrwdImpMtgnOpSlctCstChgSetReq "Forward Impact Mitigation Operation Select Customization Change Setting Request";
BA_ "SignalType" SG_ 1515 FrtRdHgtGPSCstChngSetReq "ENM";
BA_ "SignalLongName" SG_ 1515 FrtRdHgtGPSCstChngSetReq "Front Ride Height GPS Customization Change Setting Request";
BA_ "SignalType" SG_ 1515 FrntPCMRspTypCstChgSetReq "ENM";
BA_ "SignalLongName" SG_ 1515 FrntPCMRspTypCstChgSetReq "Front PCM Response Type Customization Change Setting Request";
BA_ "SignalType" SG_ 1515 GoNotfrCstChgSetReq "ENM";
BA_ "SignalLongName" SG_ 1515 GoNotfrCstChgSetReq "Go Notifier Customization Change Setting Request";
BA_ "SignalType" SG_ 1515 GlrFrHgBmRspTypCstChgSetReq "ENM";
BA_ "SignalLongName" SG_ 1515 GlrFrHgBmRspTypCstChgSetReq "Glare Free High Beam Response Type Customization Change Setting Request";
BA_ "SignalType" SG_ 1515 PhnLtInVehCstChgSetReq "ENM";
BA_ "SignalLongName" SG_ 1515 PhnLtInVehCstChgSetReq "Phone Left In Vehicle Customization Change Setting Request";
BA_ "SignalType" SG_ 1515 LtRtHnTrCstChgSetReq "ENM";
BA_ "SignalLongName" SG_ 1515 LtRtHnTrCstChgSetReq "Left Right Hand Traffic Customization Change Setting Request";
BA_ "SignalType" SG_ 1515 JckKnfDtnCstChgSetReq "ENM";
BA_ "SignalLongName" SG_ 1515 JckKnfDtnCstChgSetReq "Jack Knife Detection Customization Change Setting Request";
BA_ "SignalType" SG_ 1515 APACrssBckInSftBtnStat "ENM";
BA_ "SignalLongName" SG_ 1515 APACrssBckInSftBtnStat "Advanced Park Assist Cross Back-In Soft Button Status";
BA_ "SignalType" SG_ 1515 PrkAsstTrHtchPsntCstChgSetReq "ENM";
BA_ "SignalLongName" SG_ 1515 PrkAsstTrHtchPsntCstChgSetReq "Park Assist Trailer Hitch Present Customization Change Setting Request";
BA_ "SignalType" SG_ 1515 PrkAsstOnOffCstChgSetReq "ENM";
BA_ "SignalLongName" SG_ 1515 PrkAsstOnOffCstChgSetReq "Park Assist On Off Customization Change Setting Request";
BA_ "SignalType" SG_ 1516 RrCrsTrfcAlrtCstChngSetReq "ENM";
BA_ "SignalLongName" SG_ 1516 RrCrsTrfcAlrtCstChngSetReq "Rear Cross Traffic Alert Customization Change Setting Request";
BA_ "SignalType" SG_ 1516 RnngBrdManDplyCstChgSetReq "ENM";
BA_ "SignalLongName" SG_ 1516 RnngBrdManDplyCstChgSetReq "Running Boards Manual Deployment Customization Change Setting Request";
BA_ "SignalType" SG_ 1516 RnngBrdAutoDplyCstChgSetReq "ENM";
BA_ "SignalLongName" SG_ 1516 RnngBrdAutoDplyCstChgSetReq "Running Boards Automatic Deployment Customization Change Setting Request";
BA_ "SignalType" SG_ 1516 SBZAlrtCstChngSetReq "ENM";
BA_ "SignalLongName" SG_ 1516 SBZAlrtCstChngSetReq "Side Blind Zone Alert Customization Change Setting Request";
BA_ "SignalType" SG_ 1516 RrVwPrkAstSymCstChgSetReq "ENM";
BA_ "SignalLongName" SG_ 1516 RrVwPrkAstSymCstChgSetReq "Rear View Park Assist Symbol Customization Change Setting Request";
BA_ "SignalType" SG_ 1516 RrPCMRspTypCstChgSetReq "ENM";
BA_ "SignalLongName" SG_ 1516 RrPCMRspTypCstChgSetReq "Rear PCM Response Type Customization Change Setting Request";
BA_ "SignalType" SG_ 1516 SrrndVwLghtCstChgSetReq "ENM";
BA_ "SignalLongName" SG_ 1516 SrrndVwLghtCstChgSetReq "Surround View Lighting Customization Change Setting Request";
BA_ "SignalType" SG_ 1516 SelUlkCstChgSetReq "ENM";
BA_ "SignalLongName" SG_ 1516 SelUlkCstChgSetReq "Selective Unlocking Customization Change Setting Request";
BA_ "SignalType" SG_ 1516 TnDrvSpdLmtCstChgStReq "ENM";
BA_ "SignalLongName" SG_ 1516 TnDrvSpdLmtCstChgStReq "Teen Driver Speed Limit Customization Change Setting Request";
BA_ "SignalType" SG_ 1516 StBltTghtngCstChgSetReq "ENM";
BA_ "SignalLongName" SG_ 1516 StBltTghtngCstChgSetReq "Seat Belt Tightening Customization Change Setting Request";
BA_ "SignalType" SG_ 1516 StBltShfIntlkCstChgSetReq "ENM";
BA_ "SignalLongName" SG_ 1516 StBltShfIntlkCstChgSetReq "Seat Belt Shift Interlock Customization Change Setting Request";
BA_ "SignalType" SG_ 1516 TrlrMirVidEnblCstChgSetReq "ENM";
BA_ "SignalLongName" SG_ 1516 TrlrMirVidEnblCstChgSetReq "Trailering Mirror Video Enable Customization Change Setting Request";
BA_ "SignalType" SG_ 1516 TrffcLgtAsstCstChgSetReq "ENM";
BA_ "SignalLongName" SG_ 1516 TrffcLgtAsstCstChgSetReq "Traffic Light Assist Customization Change Setting Request";
BA_ "SignalType" SG_ 1516 TnDrvStBltShfIntlkCstChgSetReq "ENM";
BA_ "SignalLongName" SG_ 1516 TnDrvStBltShfIntlkCstChgSetReq "Teen Driver Seat Belt Shift Interlock Customization Change Setting Request";
BA_ "SignalType" SG_ 1516 VehLctrLtsCstChgSetReq "ENM";
BA_ "SignalLongName" SG_ 1516 VehLctrLtsCstChgSetReq "Vehicle Locator Lights Customization Change Setting Request";
BA_ "SignalType" SG_ 1516 TrlrMirVidGdlnsCstChgSetReq "ENM";
BA_ "SignalLongName" SG_ 1516 TrlrMirVidGdlnsCstChgSetReq "Trailering Mirror Video Guidelines Customization Change Setting Request";
BA_ "SignalType" SG_ 1516 APALftSftBtnStat "ENM";
BA_ "SignalLongName" SG_ 1516 APALftSftBtnStat "Advanced Park Assist Left Soft Button Status";
BA_ "SignalType" SG_ 1516 APAFcStatCSM "ENM";
BA_ "SignalLongName" SG_ 1516 APAFcStatCSM "Advanced Park Assist Focus Status CSM";
BA_ "SignalType" SG_ 1516 APAExtPrkSftBtnStat "ENM";
BA_ "SignalLongName" SG_ 1516 APAExtPrkSftBtnStat "Advanced Park Assist Exit Park Soft Button Status";
BA_ "SignalType" SG_ 1516 ElvtdIdlCstChgSetReq "ENM";
BA_ "SignalLongName" SG_ 1516 ElvtdIdlCstChgSetReq "Elevated Idle Customization Change Setting Request";
BA_ "SignalType" SG_ 1516 WlkAwyLckCstChgSetReq "ENM";
BA_ "SignalLongName" SG_ 1516 WlkAwyLckCstChgSetReq "Walk Away Locking Customization Change Setting Request";
BA_ "SignalType" SG_ 1516 TimeDispFormat "ENM";
BA_ "SignalLongName" SG_ 1516 TimeDispFormat "Time Display Format";
BA_ "SignalType" SG_ 1516 RstrCstDfltReq "ENM";
BA_ "SignalLongName" SG_ 1516 RstrCstDfltReq "Restore Customization Defaults Request";
BA_ "SignalType" SG_ 1516 RFStStsDispActv "ENM";
BA_ "SignalLongName" SG_ 1516 RFStStsDispActv "Right Front Seat Status Display Active";
BA_ "SignalType" SG_ 1516 LFStStsDispActv "ENM";
BA_ "SignalLongName" SG_ 1516 LFStStsDispActv "Left Front Seat Status Display Active";
BA_ "SignalType" SG_ 1516 APASrchSftBtnStat "ENM";
BA_ "SignalLongName" SG_ 1516 APASrchSftBtnStat "Advanced Park Assist Searching Soft Button Status";
BA_ "SignalType" SG_ 1516 APARghtSftBtnStat "ENM";
BA_ "SignalLongName" SG_ 1516 APARghtSftBtnStat "Advanced Park Assist Right Soft Button Status";
BA_ "SignalType" SG_ 1516 APAPrllPrkSftBtnStat "ENM";
BA_ "SignalLongName" SG_ 1516 APAPrllPrkSftBtnStat "Advanced Park Assist Parallel Parking Soft Button Status";
BA_ "SignalLongName" SG_ 1813 TeenDrvPinCd "Teen Driver Mode Information : Teen Driver PIN Code";
BA_ "SignalLongName" SG_ 1813 ValetPIN "Valet Mode Information : Valet PIN";
BA_ "SignalType" SG_ 1813 ValetMdReq "ENM";
BA_ "SignalLongName" SG_ 1813 ValetMdReq "Valet Mode Information : Valet Mode Request";
BA_ "SignalType" SG_ 1813 TeenDrvReq "ENM";
BA_ "SignalLongName" SG_ 1813 TeenDrvReq "Teen Driver Mode Information : Teen Driver Request";
BA_ "SignalLongName" SG_ 1813 CurrRadioAMFreq "Current Radio AM Frequency";
BA_ "SignalType" SG_ 1813 LngSelExt "ENM";
BA_ "SignalLongName" SG_ 1813 LngSelExt "Language Selection Extended";
BA_ "SignalType" SG_ 1813 PTOEngRunTmrCstSetReq "ENM";
BA_ "SignalLongName" SG_ 1813 PTOEngRunTmrCstSetReq "Power Take Off Engine Run Timer Customization Setting Request";
BA_ "SignalType" SG_ 1813 PTOEngSpdTypCstSetReq "ENM";
BA_ "SignalLongName" SG_ 1813 PTOEngSpdTypCstSetReq "Power Take Off Engine Speed Type Customization Setting Request";
BA_ "SignalType" SG_ 1813 PTOSet1SpdCstSetReq "ENM";
BA_ "SignalLongName" SG_ 1813 PTOSet1SpdCstSetReq "Power Take Off Set 1 Speed Customization Setting Request";
BA_ "SignalType" SG_ 1252 PTOStndbySpdCstSetReq "ENM";
BA_ "SignalLongName" SG_ 1252 PTOStndbySpdCstSetReq "Power Take Off Standby Speed Customization Setting Request";
BA_ "SignalType" SG_ 1252 LnChgAlrtCstChngSetReq "ENM";
BA_ "SignalLongName" SG_ 1252 LnChgAlrtCstChngSetReq "Lane Change Alert Customization Change Setting Request";
BA_ "SignalType" SG_ 1252 PTOSet2SpdCstSetReq "ENM";
BA_ "SignalLongName" SG_ 1252 PTOSet2SpdCstSetReq "Power Take Off Set 2 Speed Customization Setting Request";
BA_ "SignalType" SG_ 1252 TCP_LCMFileTrans "ENM";
BA_ "SignalLongName" SG_ 1252 TCP_LCMFileTrans "Telematics - License Compliance Material File Transfer";
BA_ "SignalType" SG_ 1252 PTOTpStpSpdCstSetReq "ENM";
BA_ "SignalLongName" SG_ 1252 PTOTpStpSpdCstSetReq "Power Take Off Tap Step Speed Customization Setting Request";
BA_ "SignalType" SG_ 1252 TCP_LCMDataMsgStat "ENM";
BA_ "SignalLongName" SG_ 1252 TCP_LCMDataMsgStat "Telematics - License Compliance Material Data Message Status";
BA_ "SignalType" SG_ 1252 CamVidICS_DispAct "ENM";
BA_ "SignalLongName" SG_ 1252 CamVidICS_DispAct "Camera Video ICS Display Active";
BA_ "SignalType" SG_ 1252 TrlrLtngSeqReq "ENM";
BA_ "SignalLongName" SG_ 1252 TrlrLtngSeqReq "Trailer Lighting Sequence Request";
BA_ "SignalType" SG_ 1252 PTOModeCstSetReq "ENM";
BA_ "SignalLongName" SG_ 1252 PTOModeCstSetReq "Power Take Off Mode Customization Setting Request";
BA_ "SignalType" SG_ 1252 VwgVwprtTopDnVwSeltn "ENM";
BA_ "SignalLongName" SG_ 1252 VwgVwprtTopDnVwSeltn "Viewing Viewport Top Down View Selection";
BA_ "SignalType" SG_ 1252 VwgVwprtZoomBtnSeltd "ENM";
BA_ "SignalLongName" SG_ 1252 VwgVwprtZoomBtnSeltd "Viewing Viewport Zoom Button Selected";
BA_ "SignalType" SG_ 1252 VwgVwprtNtfnFcsReqd "ENM";
BA_ "SignalLongName" SG_ 1252 VwgVwprtNtfnFcsReqd "Viewing Viewport Notification Focus Requested";
BA_ "SignalType" SG_ 1252 VwgVwprtNtfnDsmsReqd "ENM";
BA_ "SignalLongName" SG_ 1252 VwgVwprtNtfnDsmsReqd "Viewing Viewport Notification Dismiss Requested";
BA_ "SignalType" SG_ 1252 TrfcJamAsstVirtCtlReq "ENM";
BA_ "SignalLongName" SG_ 1252 TrfcJamAsstVirtCtlReq "Traffic Jam Assist Virtual Control Request";
BA_ "SignalType" SG_ 1252 DrvrSeltdSpdLmtrVirtCtlReqd "ENM";
BA_ "SignalLongName" SG_ 1252 DrvrSeltdSpdLmtrVirtCtlReqd "Driver Selected Speed Limiter Virtual Control Requested";
BA_ "SignalType" SG_ 1252 DrvrSeltdSpdLmtrVirtCtlReq "ENM";
BA_ "SignalLongName" SG_ 1252 DrvrSeltdSpdLmtrVirtCtlReq "Driver Selected Speed Limiter Virtual Control Request";
BA_ "SignalType" SG_ 1252 DMBlkhdDrAutoClsTmCstChgSetReq "ENM";
BA_ "SignalLongName" SG_ 1252 DMBlkhdDrAutoClsTmCstChgSetReq "Delivery Mode Bulkhead Door Auto Close Time Customization Change Setting Request";
BA_ "SignalType" SG_ 1239 MFC_LCMFileTrans "ENM";
BA_ "SignalLongName" SG_ 1239 MFC_LCMFileTrans "Multi Function Controller - License Compliance File Transfer";
BA_ "SignalType" SG_ 1239 MFC_LCMDataMsgStat "ENM";
BA_ "SignalLongName" SG_ 1239 MFC_LCMDataMsgStat "Multi Function Controller - License Compliance Material Data Message Status";
BA_ "SignalType" SG_ 1239 BklghtngCnfg "ENM";
BA_ "SignalLongName" SG_ 1239 BklghtngCnfg "Backlighting Configuration";
BA_ "SignalType" SG_ 706 WCM_LCMDataMsgStat "ENM";
BA_ "SignalLongName" SG_ 706 WCM_LCMDataMsgStat "Wireless Charger Module - License Compliance Material Data Message Status";
BA_ "SignalType" SG_ 706 WCM_LCMFileTrans "ENM";
BA_ "SignalLongName" SG_ 706 WCM_LCMFileTrans "Wireless Charger Module - License Compliance Material File Transfer";
BA_ "SignalLongName" SG_ 1425 ASSLC_AudFdbkSnkLvl "Amplifier Settings Sink Level Control : Audible Feedback Sink Level";
BA_ "SignalLongName" SG_ 1425 ASSLC_FvSnkLvl "Amplifier Settings Sink Level Control : Five Sink Level";
BA_ "SignalType" SG_ 1425 ASSLC_AutoLdnsCmpnAct "ENM";
BA_ "SignalLongName" SG_ 1425 ASSLC_AutoLdnsCmpnAct "Amplifier Settings Sink Level Control : Automatic Loudness Compensation Active";
BA_ "SignalLongName" SG_ 1425 ASSLC_MtxSnkBass "Amplifier Settings Sink Level Control : Mutex Sink Bass";
BA_ "SignalLongName" SG_ 1425 ASSLC_MtxSnkBal "Amplifier Settings Sink Level Control : Mutex Sink Balance";
BA_ "SignalLongName" SG_ 1425 ASSLC_MtxSnkFd "Amplifier Settings Sink Level Control : Mutex Sink Fade";
BA_ "SignalLongName" SG_ 1425 ASSLC_MtxSnkLvl "Amplifier Settings Sink Level Control : Mutex Sink Level";
BA_ "SignalLongName" SG_ 1425 ASSLC_MtxSnkMdrng "Amplifier Settings Sink Level Control : Mutex Sink Midrange";
BA_ "SignalLongName" SG_ 1425 ASSLC_MxPrmtSnkLvl "Amplifier Settings Sink Level Control : Mix Prompt Sink Level";
BA_ "SignalLongName" SG_ 1425 ASSLC_MtxSnkTrbl "Amplifier Settings Sink Level Control : Mutex Sink Treble";
BA_ "SignalType" SG_ 1425 ASSLC_VcSrcActOnMtx "ENM";
BA_ "SignalLongName" SG_ 1425 ASSLC_VcSrcActOnMtx "Amplifier Settings Sink Level Control : Voice Source Active On Mutex";
BA_ "SignalLongName" SG_ 1426 ZALC_LRMtxSnkLvl "Zone Audio Level Control : Left Rear Mutex Sink Level";
BA_ "SignalLongName" SG_ 1426 ZALC_LRMtxSnkRmpTm "Zone Audio Level Control : Left Rear Mutex Sink Ramp Time";
BA_ "SignalType" SG_ 1426 ZALC_LRMtxSnkMut "ENM";
BA_ "SignalLongName" SG_ 1426 ZALC_LRMtxSnkMut "Zone Audio Level Control : Left Rear Mutex Sink Mute";
BA_ "SignalType" SG_ 1426 ZALC_MltZnMixPrmtAudRR "ENM";
BA_ "SignalLongName" SG_ 1426 ZALC_MltZnMixPrmtAudRR "Zone Audio Level Control : Multi-Zone Mix Prompt Audio Right Rear";
BA_ "SignalType" SG_ 1426 ZALC_MltZnMixPrmtAudPsngrFrt "ENM";
BA_ "SignalLongName" SG_ 1426 ZALC_MltZnMixPrmtAudPsngrFrt "Zone Audio Level Control : Multi-Zone Mix Prompt Audio Passenger Front";
BA_ "SignalType" SG_ 1426 ZALC_MltZnMixPrmtAudLR "ENM";
BA_ "SignalLongName" SG_ 1426 ZALC_MltZnMixPrmtAudLR "Zone Audio Level Control : Multi-Zone Mix Prompt Audio Left Rear";
BA_ "SignalType" SG_ 1426 ZALC_MltZnMixPrmtAudDrvrFrt "ENM";
BA_ "SignalLongName" SG_ 1426 ZALC_MltZnMixPrmtAudDrvrFrt "Zone Audio Level Control : Multi-Zone Mix Prompt Audio Driver Front";
BA_ "SignalType" SG_ 1426 ZALC_MltZnAudFtrStat "ENM";
BA_ "SignalLongName" SG_ 1426 ZALC_MltZnAudFtrStat "Zone Audio Level Control : Multi-Zone Audio Feature State";
BA_ "SignalLongName" SG_ 1426 ZALC_PsngrFrtMtxSnkLvl "Zone Audio Level Control : Passenger Front Mutex Sink Level";
BA_ "SignalLongName" SG_ 1426 ZALC_PsngrFrtMtxSnkRmpTm "Zone Audio Level Control : Passenger Front Mutex Sink Ramp Time";
BA_ "SignalType" SG_ 1426 ZALC_PsngrFrtMtxSnkMut "ENM";
BA_ "SignalLongName" SG_ 1426 ZALC_PsngrFrtMtxSnkMut "Zone Audio Level Control : Passenger Front Mutex Sink Mute";
BA_ "SignalLongName" SG_ 1426 ZALC_RRMtxSnkLvl "Zone Audio Level Control : Right Rear Mutex Sink Level";
BA_ "SignalLongName" SG_ 1426 ZALC_RRMtxSnkRmpTm "Zone Audio Level Control : Right Rear Mutex Sink Ramp Time";
BA_ "SignalType" SG_ 1426 ZALC_RRMtxSnkMut "ENM";
BA_ "SignalLongName" SG_ 1426 ZALC_RRMtxSnkMut "Zone Audio Level Control : Right Rear Mutex Sink Mute";
BA_ "SignalType" SG_ 1426 FrtCntrStckOptDskDrvDckStat "ENM";
BA_ "SignalLongName" SG_ 1426 FrtCntrStckOptDskDrvDckStat "Front Center Stack Optical Disk Drive Deck State";
BA_ "SignalType" SG_ 1426 ZALC_VcSrcActvOnRRMtx "ENM";
BA_ "SignalLongName" SG_ 1426 ZALC_VcSrcActvOnRRMtx "Zone Audio Level Control : Voice Source Active On Right Rear Mutex";
BA_ "SignalType" SG_ 1426 ZALC_VcSrcActvOnPsngrFrtMtx "ENM";
BA_ "SignalLongName" SG_ 1426 ZALC_VcSrcActvOnPsngrFrtMtx "Zone Audio Level Control : Voice Source Active On Passenger Front Mutex";
BA_ "SignalType" SG_ 1426 ZALC_VcSrcActvOnLRMtx "ENM";
BA_ "SignalLongName" SG_ 1426 ZALC_VcSrcActvOnLRMtx "Zone Audio Level Control : Voice Source Active On Left Rear Mutex";
BA_ "SignalLongName" SG_ 1427 ASTC_ChimSnkLvl "Amplifier Settings Tone Control : Chime Sink Level";
BA_ "SignalType" SG_ 1427 ASTC_AmpLwPwrSt "ENM";
BA_ "SignalLongName" SG_ 1427 ASTC_AmpLwPwrSt "Amplifier Settings Tone Control : Amplifier Low Power State";
BA_ "SignalType" SG_ 1427 ASTC_DSPMd "ENM";
BA_ "SignalLongName" SG_ 1427 ASTC_DSPMd "Amplifier Settings Tone Control : DSP Mode";
BA_ "SignalType" SG_ 1427 ASTC_ChimSnkSpkrPos "ENM";
BA_ "SignalLongName" SG_ 1427 ASTC_ChimSnkSpkrPos "Amplifier Settings Tone Control : Chime Sink Speaker Position";
BA_ "SignalLongName" SG_ 1427 ASTC_LRTctlLvl "Amplifier Settings Tone Control : Left RearTactile Level";
BA_ "SignalType" SG_ 1427 ASTC_GblAudSnkMut "ENM";
BA_ "SignalLongName" SG_ 1427 ASTC_GblAudSnkMut "Amplifier Settings Tone Control : Global Audio Sink Mute";
BA_ "SignalLongName" SG_ 1427 ASTC_DrvrFrtTctlLvl "Amplifier Settings Tone Control : Driver Front Tactile Level";
BA_ "SignalLongName" SG_ 1427 ASTC_MtxSnkRmpTm "Amplifier Settings Tone Control : Mutex Sink Ramp Time";
BA_ "SignalType" SG_ 1427 ASTC_MtxSnkMut "ENM";
BA_ "SignalLongName" SG_ 1427 ASTC_MtxSnkMut "Amplifier Settings Tone Control : Mutex Sink Mute";
BA_ "SignalLongName" SG_ 1427 ASTC_SurndLvl "Amplifier Settings Tone Control : Surround Level";
BA_ "SignalLongName" SG_ 1427 ASTC_RRTctlLvl "Amplifier Settings Tone Control : Right RearTactile Level";
BA_ "SignalLongName" SG_ 1427 ASTC_PsngrFrtTctlLvl "Amplifier Settings Tone Control : Passenger Front Tactile Level";
BA_ "SignalType" SG_ 1427 FrtCntrStckHptcFdbkReq "ENM";
BA_ "SignalLongName" SG_ 1427 FrtCntrStckHptcFdbkReq "Front Center Stack Haptic Feedback Request";
BA_ "SignalType" SG_ 1427 ASTC_VehNoisCmpnAct "ENM";
BA_ "SignalLongName" SG_ 1427 ASTC_VehNoisCmpnAct "Amplifier Settings Tone Control : Vehicle Noise Compensation Active";
BA_ "SignalLongName" SG_ 1428 ICSTS_X1TchCrdnt "Integrated Center Stack Touch Status : X1 Touch Coordinate";
BA_ "SignalLongName" SG_ 1428 ICSTS_Y1TchCrdnt "Integrated Center Stack Touch Status : Y1 Touch Coordinate";
BA_ "SignalLongName" SG_ 1428 HtchPtLgth "Hitching Point Length";
BA_ "SignalLongName" SG_ 1519 VwgBowlVwAngSeltn "Viewing Bowl View Angle Selection";
BA_ "SignalType" SG_ 1519 ADASIS_NAVILINK_DgtlMpEfSpdLm "ENM";
BA_ "SignalLongName" SG_ 1519 ADASIS_NAVILINK_DgtlMpEfSpdLm "ADASIS NAVILINK Digital Map Effective Speed Limit";
BA_ "SignalType" SG_ 1519 ADASIS_NAVILINK_CntryCd "ENM";
BA_ "SignalLongName" SG_ 1519 ADASIS_NAVILINK_CntryCd "ADASIS NAVILINK Country Code";
BA_ "SignalType" SG_ 1519 VwgVwprtSeltn "ENM";
BA_ "SignalLongName" SG_ 1519 VwgVwprtSeltn "Viewing Viewport Selection";
BA_ "SignalType" SG_ 1519 SrrndVsnRcrdrListFcs "ENM";
BA_ "SignalLongName" SG_ 1519 SrrndVsnRcrdrListFcs "Surround Vision Recorder List Focus";
BA_ "SignalType" SG_ 1519 ADASIS_NAVILINK_DgtlMpPsngRst "ENM";
BA_ "SignalLongName" SG_ 1519 ADASIS_NAVILINK_DgtlMpPsngRst "ADASIS NAVILINK Digital Map Passing Restriction";
BA_ "SignalType" SG_ 1519 ADASIS_NAVILINK_DgMpCnSpdLmTyp "ENM";
BA_ "SignalLongName" SG_ 1519 ADASIS_NAVILINK_DgMpCnSpdLmTyp "ADASIS NAVILINK Digital Map Conditional Speed Limit Type";
BA_ "SignalType" SG_ 1519 SrrndVsnRcrdrVwprtSeltn "ENM";
BA_ "SignalLongName" SG_ 1519 SrrndVsnRcrdrVwprtSeltn "Surround Vision Recorder Viewport Selection";
BA_ "SignalType" SG_ 1519 SrrndVsnRcrdrFileSeltn "ENM";
BA_ "SignalLongName" SG_ 1519 SrrndVsnRcrdrFileSeltn "Surround Vision Recorder File Selection";
BA_ "SignalType" SG_ 1519 SrrndVsnRcrdrFileDeltn "ENM";
BA_ "SignalLongName" SG_ 1519 SrrndVsnRcrdrFileDeltn "Surround Vision Recorder File Deletion";
BA_ "SignalType" SG_ 1519 PFASndSeltnCstChgSetReq "ENM";
BA_ "SignalLongName" SG_ 1519 PFASndSeltnCstChgSetReq "Pedestrian Friendly Alert Sound Selection Customization Change Setting Request";
BA_ "SignalType" SG_ 1519 SrrndVsnRcrdrPlybkSeltn "ENM";
BA_ "SignalLongName" SG_ 1519 SrrndVsnRcrdrPlybkSeltn "Surround Vision Recorder Playback Selection";
BA_ "SignalType" SG_ 1519 SrrndVsnRcrdrPlybkFcs "ENM";
BA_ "SignalLongName" SG_ 1519 SrrndVsnRcrdrPlybkFcs "Surround Vision Recorder Playback Focus";
BA_ "SignalType" SG_ 1519 ADASIS_NAVILINK_BldUpFlg "ENM";
BA_ "SignalLongName" SG_ 1519 ADASIS_NAVILINK_BldUpFlg "ADASIS NAVILINK Build Up Flag";
BA_ "SignalType" SG_ 1519 PASftBtnSeltdStatRw "ENM";
BA_ "SignalLongName" SG_ 1519 PASftBtnSeltdStatRw "Park Assist Soft Button Selected State Raw";
BA_ "SignalType" SG_ 1519 APASftBtnSeltdStatRw "ENM";
BA_ "SignalLongName" SG_ 1519 APASftBtnSeltdStatRw "Advanced Park Assist Soft Button Selected State Raw";
BA_ "SignalType" SG_ 1519 VGS_TrlrActv "ENM";
BA_ "SignalLongName" SG_ 1519 VGS_TrlrActv "Viewing Guideline Selection : Viewing Guideline Selection: Trailer Active";
BA_ "SignalType" SG_ 1519 VGS_DynActv "ENM";
BA_ "SignalLongName" SG_ 1519 VGS_DynActv "Viewing Guideline Selection : Viewing Guideline Selection: Dynamic Active";
BA_ "SignalType" SG_ 1519 VGS_CurbVwActv "ENM";
BA_ "SignalLongName" SG_ 1519 VGS_CurbVwActv "Viewing Guideline Selection : Viewing Guideline Selection: Curb View Active";
BA_ "SignalType" SG_ 1520 TrgdVidRecSwAct "ENM";
BA_ "SignalLongName" SG_ 1520 TrgdVidRecSwAct "Triggered Video Recorder Switch Active";
BA_ "SignalType" SG_ 1520 ADASIS_NAVILINK_CntrldAccssRd "ENM";
BA_ "SignalLongName" SG_ 1520 ADASIS_NAVILINK_CntrldAccssRd "ADASIS NAVILINK Controlled Access Road";
BA_ "SignalType" SG_ 1520 SrrndVsnRcrdrSaveFile "ENM";
BA_ "SignalLongName" SG_ 1520 SrrndVsnRcrdrSaveFile "Surround Vision Recorder Save File";
BA_ "SignalType" SG_ 1520 SrrndVsnRcrdrRcrdSeltn "ENM";
BA_ "SignalLongName" SG_ 1520 SrrndVsnRcrdrRcrdSeltn "Surround Vision Recorder Record Selection";
BA_ "SignalType" SG_ 1520 SrrndVsnRcrdrListPgSeltn "ENM";
BA_ "SignalLongName" SG_ 1520 SrrndVsnRcrdrListPgSeltn "Surround Vision Recorder List Page Selection";
BA_ "SignalLongName" SG_ 1814 ONPC_DprtrHrOfDyReq "Override Next Planned Charge : Departure Hour of Day Request";
BA_ "SignalType" SG_ 1814 ONPC_DprtrDyOfWkReq "ENM";
BA_ "SignalLongName" SG_ 1814 ONPC_DprtrDyOfWkReq "Override Next Planned Charge : Departure Day of Week Request";
BA_ "SignalType" SG_ 1814 ONPC_Req "ENM";
BA_ "SignalLongName" SG_ 1814 ONPC_Req "Override Next Planned Charge : Request";
BA_ "SignalLongName" SG_ 1814 ONPC_DprtrMinOfHrReq "Override Next Planned Charge : Departure Minute of Hour Request";
BA_ "SignalType" SG_ 1814 DAPR_CtlDir "ENM";
BA_ "SignalLongName" SG_ 1814 DAPR_CtlDir "Directional Audio Prompt Rendering : Control Direction";
BA_ "SignalLongName" SG_ 1814 ONPC_TgtChrgLvlReq "Override Next Planned Charge : Target Charge Level Request";
BA_ "SignalLongName" SG_ 1814 DAPR_CtlDist "Directional Audio Prompt Rendering : Control Distance";
BA_ "SignalType" SG_ 1814 DAPR_CurrPrmt "ENM";
BA_ "SignalLongName" SG_ 1814 DAPR_CurrPrmt "Directional Audio Prompt Rendering : Current Prompt";
BA_ "SignalType" SG_ 1814 DAPR_CtlZn "ENM";
BA_ "SignalLongName" SG_ 1814 DAPR_CtlZn "Directional Audio Prompt Rendering : Control Zone";
BA_ "SignalType" SG_ 1814 LVMAVC_RmtEnbl "ENM";
BA_ "SignalLongName" SG_ 1814 LVMAVC_RmtEnbl "Low Volume Module Audio Video Command : Remote Enable";
BA_ "SignalType" SG_ 1814 LVMAVC_PrmtAudResp "ENM";
BA_ "SignalLongName" SG_ 1814 LVMAVC_PrmtAudResp "Low Volume Module Audio Video Command : Prompt Audio Response";
BA_ "SignalType" SG_ 1814 LVMAVC_ApplID "ENM";
BA_ "SignalLongName" SG_ 1814 LVMAVC_ApplID "Low Volume Module Audio Video Command : LVM Application ID";
BA_ "SignalType" SG_ 1814 LVMAVC_StreoAudResp "ENM";
BA_ "SignalLongName" SG_ 1814 LVMAVC_StreoAudResp "Low Volume Module Audio Video Command : Stereo Audio Response";
BA_ "SignalType" SG_ 1814 LVMAVC_SpchRcgnAval "ENM";
BA_ "SignalLongName" SG_ 1814 LVMAVC_SpchRcgnAval "Low Volume Module Audio Video Command : Speech Recognition Available";
BA_ "SignalType" SG_ 1814 LVMAVC_RmtSpchRcgnID "ENM";
BA_ "SignalLongName" SG_ 1814 LVMAVC_RmtSpchRcgnID "Low Volume Module Audio Video Command : Remote Speech Recognition ID";
BA_ "SignalType" SG_ 1814 LVMAVC_RmtSpchRcgnActn "ENM";
BA_ "SignalLongName" SG_ 1814 LVMAVC_RmtSpchRcgnActn "Low Volume Module Audio Video Command : Remote Speech Recognition Action";
BA_ "SignalType" SG_ 1814 OvrrdNextPlndCbnPrcndtngReq "ENM";
BA_ "SignalLongName" SG_ 1814 OvrrdNextPlndCbnPrcndtngReq "Override Next Planned Charge : Override Next Planned Cabin Preconditioning Request";
BA_ "SignalLongName" SG_ 1814 RtSdFrtZnAudVolCtlOfst "Right Side Front Zone Audio Volume Control Offset";
BA_ "SignalLongName" SG_ 1251 TrlrLgth "Trailer Length";
BA_ "SignalLongName" SG_ 1251 HtchPtLgthExtd "Hitching Point Length Extended";
BA_ "SignalLongName" SG_ 1251 TrlrHght "Trailer Height";
BA_ "SignalLongName" SG_ 1251 TrlrTngeLgth "Trailer Tongue Length";
BA_ "SignalLongName" SG_ 1251 TrlrWdth "Trailer Width";
BA_ "SignalLongName" SG_ 1251 VehHtchHght "Vehicle Hitch Height";
BA_ "SignalLongName" SG_ 1251 LtSdFrtZnAudVolCtlOfst "Left Side Front Zone Audio Volume Control Offset";
BA_ "SignalLongName" SG_ 1815 VehHtchLgth "Vehicle Hitch Length";
BA_ "SignalType" SG_ 1815 HMIInCarVcCommCtl "ENM";
BA_ "SignalLongName" SG_ 1815 HMIInCarVcCommCtl "HMI In Car Voice Communication Control";
BA_ "SignalType" SG_ 1815 AutoTrnspHdActvnCstChgSetReq "ENM";
BA_ "SignalLongName" SG_ 1815 AutoTrnspHdActvnCstChgSetReq "Automatic Transparent Hood Activation Customization Change Setting Request";
BA_ "SignalType" SG_ 1815 AutoLnChgCstChgSetReq "ENM";
BA_ "SignalLongName" SG_ 1815 AutoLnChgCstChgSetReq "Automatic Lane Change Customization Change Setting Request";
BA_ "SignalType" SG_ 1815 ChrgPwrLossAlrtCstSetReq "ENM";
BA_ "SignalLongName" SG_ 1815 ChrgPwrLossAlrtCstSetReq "Charge Power Loss Alert Customization Setting Request";
BA_ "SignalType" SG_ 1815 ChrgDatReq "ENM";
BA_ "SignalLongName" SG_ 1815 ChrgDatReq "Charging Data Request";
BA_ "SignalType" SG_ 1815 LocBsdChrgPstnMdfnReq "ENM";
BA_ "SignalLongName" SG_ 1815 LocBsdChrgPstnMdfnReq "Location Based Charging Position Modification Request";
BA_ "SignalType" SG_ 1815 TrlrHtchTyp "ENM";
BA_ "SignalLongName" SG_ 1815 TrlrHtchTyp "Trailer Hitch Type";
BA_ "SignalType" SG_ 1815 LocBsdChrgCstSetReq "ENM";
BA_ "SignalLongName" SG_ 1815 LocBsdChrgCstSetReq "Location Based Charging Customization Setting Request";
BA_ "SignalType" SG_ 1815 FrtCntrStckVidInSel "ENM";
BA_ "SignalLongName" SG_ 1815 FrtCntrStckVidInSel "Front Center Stack Video Input Select";
BA_ "SignalType" SG_ 1815 ChrgSysAudblIndCstSetReq "ENM";
BA_ "SignalLongName" SG_ 1815 ChrgSysAudblIndCstSetReq "Charge System Audible Indication Customization Setting Request";
BA_ "SignalType" SG_ 1815 Frt360CamSwAct "ENM";
BA_ "SignalLongName" SG_ 1815 Frt360CamSwAct "Front 360 Camera Switch Active";
BA_ "SignalType" SG_ 1815 DrvrSeltdTrlrPrsnt "ENM";
BA_ "SignalLongName" SG_ 1815 DrvrSeltdTrlrPrsnt "Driver Selected Trailer Present";
BA_ "SignalType" SG_ 1815 DirAudPrmtRndrngEnbld "ENM";
BA_ "SignalLongName" SG_ 1815 DirAudPrmtRndrngEnbld "Directional Audio Prompt Rendering Enabled";
BA_ "SignalType" SG_ 1815 TrlrTyp "ENM";
BA_ "SignalLongName" SG_ 1815 TrlrTyp "Trailer Type";
BA_ "SignalType" SG_ 1815 TrlrStatTowHaulModeOvrrd "ENM";
BA_ "SignalLongName" SG_ 1815 TrlrStatTowHaulModeOvrrd "Trailer State Tow Haul Mode Override";
BA_ "SignalType" SG_ 1815 TrlrAppAux1CamPrvwReqd "ENM";
BA_ "SignalLongName" SG_ 1815 TrlrAppAux1CamPrvwReqd "Trailering App Aux 1 Camera Preview Requested";
BA_ "SignalType" SG_ 1815 TrlRvsLghtFldEnbld "ENM";
BA_ "SignalLongName" SG_ 1815 TrlRvsLghtFldEnbld "DEPRECATED VIP 23 - Trailer Reverse Light Failed Enabled";
BA_ "SignalType" SG_ 1815 LifetmEleclEngyEconRstReqd "ENM";
BA_ "SignalLongName" SG_ 1815 LifetmEleclEngyEconRstReqd "Lifetime Electrical Energy Economy Reset Requested";
BA_ "SignalType" SG_ 1815 HybTripDatRstReqd "ENM";
BA_ "SignalLongName" SG_ 1815 HybTripDatRstReqd "Hybrid Trip Data Reset Requested";
BA_ "SignalType" SG_ 1815 HndsFrVcCallActv "ENM";
BA_ "SignalLongName" SG_ 1815 HndsFrVcCallActv "Hands Free Voice Call Active";
BA_ "SignalType" SG_ 1815 HiVltgBatStopChrgReq "ENM";
BA_ "SignalLongName" SG_ 1815 HiVltgBatStopChrgReq "High Voltage Battery Stop Charging Request";
BA_ "SignalType" SG_ 1815 FrtZnAudVolSyncCtlOn "ENM";
BA_ "SignalLongName" SG_ 1815 FrtZnAudVolSyncCtlOn "Front Zone Audio Volume Sync Control On";
BA_ "SignalType" SG_ 1815 FrtCntrStckTchCtlrRstCmd "ENM";
BA_ "SignalLongName" SG_ 1815 FrtCntrStckTchCtlrRstCmd "Front Center Stack Touch Controller Reset Command";
BA_ "SignalType" SG_ 1815 TrlrProfDrvrReqdSeltn "ENM";
BA_ "SignalLongName" SG_ 1815 TrlrProfDrvrReqdSeltn "Trailer Profile Driver Requested Selection";
BA_ "SignalType" SG_ 1815 VcRcgnSesnActv "ENM";
BA_ "SignalLongName" SG_ 1815 VcRcgnSesnActv "Voice Recognition Session Active";
BA_ "SignalType" SG_ 1815 TrlrTirePresSnsrIDLrnReqd "ENM";
BA_ "SignalLongName" SG_ 1815 TrlrTirePresSnsrIDLrnReqd "Trailer Tire Pressure Sensor ID Learn Requested";
BA_ "SignalType" SG_ 1815 TrlrTirePresProfXferd "ENM";
BA_ "SignalLongName" SG_ 1815 TrlrTirePresProfXferd "Trailer Tire Pressure Profile Transferred";
BA_ "SignalType" SG_ 1815 TrlrThftAlrtEnbld "ENM";
BA_ "SignalLongName" SG_ 1815 TrlrThftAlrtEnbld "Trailer Theft Alert Enabled";
BA_ "SignalType" SG_ 1815 TrlrLghtAlrtEnbld "ENM";
BA_ "SignalLongName" SG_ 1815 TrlrLghtAlrtEnbld "Trailer Light Alerts Enabled";
BA_ "SignalType" SG_ 1815 TrlrAppInvsblTrlrPrvwReqd "ENM";
BA_ "SignalLongName" SG_ 1815 TrlrAppInvsblTrlrPrvwReqd "Trailering App Invisible Trailer Preview Requested";
BA_ "SignalType" SG_ 1815 TrlrAppAux2CamPrvwReqd "ENM";
BA_ "SignalLongName" SG_ 1815 TrlrAppAux2CamPrvwReqd "Trailering App Aux 2 Camera Preview Requested";
BA_ "SignalType" SG_ 1815 DMSIntnDrvrCstChgSetReq "ENM";
BA_ "SignalLongName" SG_ 1815 DMSIntnDrvrCstChgSetReq "Driver Monitoring System Inattentive Driver Customization Change Setting Request";
BA_ "SignalLongName" SG_ 1827 TrlrPlcrdPres "Trailer Placard Pressure";
BA_ "SignalType" SG_ 1827 TrlrProfDeltn "ENM";
BA_ "SignalLongName" SG_ 1827 TrlrProfDeltn "Trailer Profile Deletion";
BA_ "SignalLongName" SG_ 1827 TrlrTireDRWAxlCnt "Trailer Tire Dual Rear Wheel Axle Count";
BA_ "SignalType" SG_ 1827 NumofAxls "ENM";
BA_ "SignalLongName" SG_ 1827 NumofAxls "Trailer Axle Count";
BA_ "SignalLongName" SG_ 1827 TrlrTireCnt "Trailer Tire Count";
BA_ "SignalType" SG_ 1433 ReqRrClmtApp "ENM";
BA_ "SignalLongName" SG_ 1433 ReqRrClmtApp "Request Rear Climate App";
BA_ "SignalType" SG_ 1433 ReqFrtClmtApp "ENM";
BA_ "SignalLongName" SG_ 1433 ReqFrtClmtApp "Request Front Climate App";
BA_ "SignalType" SG_ 1817 HtdStrgWhlSwActv_HVAC_FP_F "ENM";
BA_ "SignalLongName" SG_ 1817 HtdStrgWhlSwActv_HVAC_FP_F "Heated Steering Wheel Switch Active HVAC Front Faceplate";
BA_ "SignalType" SG_ 1817 ManHtdStrgWhlReqd_HVAC_FP_F "ENM";
BA_ "SignalLongName" SG_ 1817 ManHtdStrgWhlReqd_HVAC_FP_F "Manual Heated Steering Wheel Requested HVAC Front Faceplate";
BA_ "SignalType" SG_ 1817 ManHtdStrgWhlReqd_HVAC_FP_F_Inv "ENM";
BA_ "SignalLongName" SG_ 1817 ManHtdStrgWhlReqd_HVAC_FP_F_Inv "Manual Heated Steering Wheel Requested HVAC Front Faceplate Invalid";
BA_ "SignalType" SG_ 1817 HtdStrgWhlStkSw_HVAC_FP_F "ENM";
BA_ "SignalLongName" SG_ 1817 HtdStrgWhlStkSw_HVAC_FP_F "Heated Steering Wheel Stuck Switch HVAC Front Faceplate";
BA_ "SignalType" SG_ 1817 HtdStrgWhlStkSw_HVAC_FP_F_Inv "ENM";
BA_ "SignalLongName" SG_ 1817 HtdStrgWhlStkSw_HVAC_FP_F_Inv "Heated Steering Wheel Stuck Switch HVAC Front Faceplate Invalid";
BA_ "SignalType" SG_ 1435 RHVSRR_HtdBckLvlChgUp "ENM";
BA_ "SignalLongName" SG_ 1435 RHVSRR_HtdBckLvlChgUp "Request Heated Vented Seat Right Rear : Heated Back Level Change Up";
BA_ "SignalType" SG_ 1435 RHVSRR_HtdBckLvlChgDn "ENM";
BA_ "SignalLongName" SG_ 1435 RHVSRR_HtdBckLvlChgDn "Request Heated Vented Seat Right Rear : Heated Back Level Change Down";
BA_ "SignalType" SG_ 1435 RHVSLR_VntLvlChgUp "ENM";
BA_ "SignalLongName" SG_ 1435 RHVSLR_VntLvlChgUp "Request Heated Vented Seat Left Rear : Vented Level Change Up";
BA_ "SignalType" SG_ 1435 RHVSLR_VntLvlChgDn "ENM";
BA_ "SignalLongName" SG_ 1435 RHVSLR_VntLvlChgDn "Request Heated Vented Seat Left Rear : Vented Level Change Down";
BA_ "SignalType" SG_ 1435 RHVSLR_HtdCushBckLvlChgUp "ENM";
BA_ "SignalLongName" SG_ 1435 RHVSLR_HtdCushBckLvlChgUp "Request Heated Vented Seat Left Rear : Heated Cushion and Back Level Change Up";
BA_ "SignalType" SG_ 1435 RHVSLR_HtdCushBckLvlChgDn "ENM";
BA_ "SignalLongName" SG_ 1435 RHVSLR_HtdCushBckLvlChgDn "Request Heated Vented Seat Left Rear : Heated Cushion and Back Level Change Down";
BA_ "SignalType" SG_ 1435 RHVSLR_HtdBckLvlChgUp "ENM";
BA_ "SignalLongName" SG_ 1435 RHVSLR_HtdBckLvlChgUp "Request Heated Vented Seat Left Rear : Heated Back Level Change Up";
BA_ "SignalType" SG_ 1435 RHVSLR_HtdBckLvlChgDn "ENM";
BA_ "SignalLongName" SG_ 1435 RHVSLR_HtdBckLvlChgDn "Request Heated Vented Seat Left Rear : Heated Back Level Change Down";
BA_ "SignalType" SG_ 1435 RHVSRR_VntLvlChgUp "ENM";
BA_ "SignalLongName" SG_ 1435 RHVSRR_VntLvlChgUp "Request Heated Vented Seat Right Rear : Vented Level Change Up";
BA_ "SignalType" SG_ 1435 RHVSRR_VntLvlChgDn "ENM";
BA_ "SignalLongName" SG_ 1435 RHVSRR_VntLvlChgDn "Request Heated Vented Seat Right Rear : Vented Level Change Down";
BA_ "SignalType" SG_ 1435 RHVSRR_HtdCushBckLvlChgUp "ENM";
BA_ "SignalLongName" SG_ 1435 RHVSRR_HtdCushBckLvlChgUp "Request Heated Vented Seat Right Rear : Heated Cushion and Back Level Change Up";
BA_ "SignalType" SG_ 1435 RHVSRR_HtdCushBckLvlChgDn "ENM";
BA_ "SignalLongName" SG_ 1435 RHVSRR_HtdCushBckLvlChgDn "Request Heated Vented Seat Right Rear : Heated Cushion and Back Level Change Down";
BA_ "SignalLongName" SG_ 1182 DuctAirTempRrFloorRwVltg "Duct Air Temperature Rear Floor Raw Voltage";
BA_ "SignalLongName" SG_ 1182 DuctAirTempRrRtFloorRwVltg "Duct Air Temperature Rear Right Floor Raw Voltage";
BA_ "SignalLongName" SG_ 1182 DuctAirTempRrRtVntRwVltg "Duct Air Temperature Rear Right Vent Raw Voltage";
BA_ "SignalLongName" SG_ 1182 DuctAirTempRrVntRwVltg "Duct Air Temperature Rear Vent Raw Voltage";
BA_ "SignalLongName" SG_ 1182 ClmCtlRrBlwFanSpdPWMFreq "Climate Control Rear Blower Fan Speed PWM Frequency";
BA_ "SignalLongName" SG_ 1436 FCSTP12_FrtCntrStckTchPosX1 "Front Center Stack Touch Position 12 : Front Center Stack Touch Position X1";
BA_ "SignalType" SG_ 1436 FCSTP12_FrtCntrStckTchFlg2 "ENM";
BA_ "SignalLongName" SG_ 1436 FCSTP12_FrtCntrStckTchFlg2 "Front Center Stack Touch Position 12 : Front Center Stack Touch Flag 2";
BA_ "SignalType" SG_ 1436 FCSTP12_FrtCntrStckTchFlg1 "ENM";
BA_ "SignalLongName" SG_ 1436 FCSTP12_FrtCntrStckTchFlg1 "Front Center Stack Touch Position 12 : Front Center Stack Touch Flag 1";
BA_ "SignalLongName" SG_ 1436 FCSTP12_FrtCntrStckTchPosX2 "Front Center Stack Touch Position 12 : Front Center Stack Touch Position X2";
BA_ "SignalLongName" SG_ 1436 FCSTP12_FrtCntrStckTchPosY1 "Front Center Stack Touch Position 12 : Front Center Stack Touch Position Y1";
BA_ "SignalLongName" SG_ 1436 FCSTP12_FrtCntrStckTchPosY2 "Front Center Stack Touch Position 12 : Front Center Stack Touch Position Y2";
BA_ "SignalLongName" SG_ 1436 FCSTP12_FrtCntrStckTmStmp12 "Front Center Stack Touch Position 12 : Front Center Stack Time Stamp 12";
BA_ "SignalType" SG_ 1436 StrgeOpn "ENM";
BA_ "SignalLongName" SG_ 1436 StrgeOpn "Storage Open";
BA_ "SignalLongName" SG_ 1437 FCSTP34_FrtCntrStckTchPosX3 "Front Center Stack Touch Position 34 : Front Center Stack Touch Position X3";
BA_ "SignalType" SG_ 1437 FCSTP34_FrtCntrStckTchFlg4 "ENM";
BA_ "SignalLongName" SG_ 1437 FCSTP34_FrtCntrStckTchFlg4 "Front Center Stack Touch Position 34 : Front Center Stack Touch Flag 4";
BA_ "SignalType" SG_ 1437 FCSTP34_FrtCntrStckTchFlg3 "ENM";
BA_ "SignalLongName" SG_ 1437 FCSTP34_FrtCntrStckTchFlg3 "Front Center Stack Touch Position 34 : Front Center Stack Touch Flag 3";
BA_ "SignalLongName" SG_ 1437 FCSTP34_FrtCntrStckTchPosX4 "Front Center Stack Touch Position 34 : Front Center Stack Touch Position X4";
BA_ "SignalLongName" SG_ 1437 FCSTP34_FrtCntrStckTchPosY3 "Front Center Stack Touch Position 34 : Front Center Stack Touch Position Y3";
BA_ "SignalLongName" SG_ 1437 FCSTP34_FrtCntrStckTchPosY4 "Front Center Stack Touch Position 34 : Front Center Stack Touch Position Y4";
BA_ "SignalLongName" SG_ 1437 FCSTP34_FrtCntrStckTmStmp34 "Front Center Stack Touch Position 34 : Front Center Stack Time Stamp 34";
BA_ "SignalType" SG_ 1438 FCSS1_FrtCntrStckSldr1Prxmty "ENM";
BA_ "SignalLongName" SG_ 1438 FCSS1_FrtCntrStckSldr1Prxmty "Front Center Stack Slider 1 : Front Center Stack Slider 1 Proximity";
BA_ "SignalLongName" SG_ 1438 FCSS1_FrtCntrStckSldr1Pos "Front Center Stack Slider 1 : Front Center Stack Slider 1 Position";
BA_ "SignalType" SG_ 1438 FCSS2_FrtCntrStckSldr2Prxmty "ENM";
BA_ "SignalLongName" SG_ 1438 FCSS2_FrtCntrStckSldr2Prxmty "Front Center Stack Slider 2 : Front Center Stack Slider 2 Proximity";
BA_ "SignalLongName" SG_ 1438 FCSS2_FrtCntrStckSldr2Pos "Front Center Stack Slider 2 : Front Center Stack Slider 2 Position";
BA_ "SignalType" SG_ 1438 FCSS3_FrtCntrStckSldr3Prxmty "ENM";
BA_ "SignalLongName" SG_ 1438 FCSS3_FrtCntrStckSldr3Prxmty "Front Center Stack Slider 3 : Front Center Stack Slider 3 Proximity";
BA_ "SignalLongName" SG_ 1438 FCSS3_FrtCntrStckSldr3Pos "Front Center Stack Slider 3 : Front Center Stack Slider 3 Position";
BA_ "SignalType" SG_ 1248 FrtCntrStckPriVidInLckd "ENM";
BA_ "SignalLongName" SG_ 1248 FrtCntrStckPriVidInLckd "Front Center Stack Primary Video Input Locked";
BA_ "SignalType" SG_ 1248 FrtCntrStckLVMVidInLckd "ENM";
BA_ "SignalLongName" SG_ 1248 FrtCntrStckLVMVidInLckd "Front Center Stack Low Volume Module Video Input Locked";
BA_ "SignalType" SG_ 1818 AutoTransGrDispdVal "ENM";
BA_ "SignalLongName" SG_ 1818 AutoTransGrDispdVal "Automatic Transmission Gear Displayed Value";
BA_ "SignalType" SG_ 1818 AutoTransGrDispdVal_Inv "ENM";
BA_ "SignalLongName" SG_ 1818 AutoTransGrDispdVal_Inv "Automatic Transmission Gear Displayed Value Invalid";
BA_ "SignalLongName" SG_ 930 ChmMngrStat "Chime Manager Status";
BA_ "SignalType" SG_ 723 JmpStrtReqd "ENM";
BA_ "SignalLongName" SG_ 723 JmpStrtReqd "Jump Start Requested";
BA_ "SignalType" SG_ 1441 StrWhlCtlVolDnSw "ENM";
BA_ "SignalLongName" SG_ 1441 StrWhlCtlVolDnSw "Steering Wheel Control Volume Down Switch";
BA_ "SignalType" SG_ 1441 StrWhlCtlPshToTlkSw "ENM";
BA_ "SignalLongName" SG_ 1441 StrWhlCtlPshToTlkSw "Steering Wheel Control Push To Talk Switch";
BA_ "SignalType" SG_ 1441 StrWhlCtlFvrtUpSw "ENM";
BA_ "SignalLongName" SG_ 1441 StrWhlCtlFvrtUpSw "Steering Wheel Control Favorites Up Switch";
BA_ "SignalType" SG_ 1441 StrWhlCtlFvrtDnSw "ENM";
BA_ "SignalLongName" SG_ 1441 StrWhlCtlFvrtDnSw "Steering Wheel Control Favorites Down Switch";
BA_ "SignalType" SG_ 1441 StrWhlCtlEndSw "ENM";
BA_ "SignalLongName" SG_ 1441 StrWhlCtlEndSw "Steering Wheel Control End Switch";
BA_ "SignalType" SG_ 1441 ChmMngrSoH "ENM";
BA_ "SignalLongName" SG_ 1441 ChmMngrSoH "Chime Manager State of Health";
BA_ "SignalType" SG_ 1441 StrWhlCtlVolUpSw "ENM";
BA_ "SignalLongName" SG_ 1441 StrWhlCtlVolUpSw "Steering Wheel Control Volume Up Switch";
BA_ "SignalType" SG_ 1522 HUD_RclCmpt "ENM";
BA_ "SignalLongName" SG_ 1522 HUD_RclCmpt "Head Up Display Recall Complete";
BA_ "SignalType" SG_ 1522 HUD_CustSelActvStat "ENM";
BA_ "SignalLongName" SG_ 1522 HUD_CustSelActvStat "Head Up Display Customer Selection Active Status";
BA_ "SignalType" SG_ 1522 HUD_CustSelActvStat_Inv "ENM";
BA_ "SignalLongName" SG_ 1522 HUD_CustSelActvStat_Inv "Head Up Display Customer Selection Active Status Invalid";
BA_ "SignalType" SG_ 1522 DispMeasSysExtnd "ENM";
BA_ "SignalLongName" SG_ 1522 DispMeasSysExtnd "Display Measurement System Extended";
BA_ "SignalType" SG_ 1522 ClstrAnmStat "ENM";
BA_ "SignalLongName" SG_ 1522 ClstrAnmStat "Cluster Animation State";
BA_ "SignalType" SG_ 1522 PAMutDrvrReq "ENM";
BA_ "SignalLongName" SG_ 1522 PAMutDrvrReq "Park Assist Mute Driver Request";
BA_ "SignalType" SG_ 1522 NtVsnVidCntrstUserReq "ENM";
BA_ "SignalLongName" SG_ 1522 NtVsnVidCntrstUserReq "Night Vision Video Contrast User Request";
BA_ "SignalType" SG_ 1522 NtVsnVidBrghtnsUserReq "ENM";
BA_ "SignalLongName" SG_ 1522 NtVsnVidBrghtnsUserReq "Night Vision Video Brightness User Request";
BA_ "SignalType" SG_ 1522 IPC_RunCrnkInpActv "ENM";
BA_ "SignalLongName" SG_ 1522 IPC_RunCrnkInpActv "IPC Run Crank Input Active";
BA_ "SignalType" SG_ 1522 IPC_RunCrnkInpActv_Inv "ENM";
BA_ "SignalLongName" SG_ 1522 IPC_RunCrnkInpActv_Inv "IPC Run Crank Input Active Invalidity";
BA_ "SignalType" SG_ 1522 StkHUD_CustSelStat "ENM";
BA_ "SignalLongName" SG_ 1522 StkHUD_CustSelStat "Stuck Head Up Display Customer Selection Status";
BA_ "SignalType" SG_ 1522 FuelFiltLifeRstReqd "ENM";
BA_ "SignalLongName" SG_ 1522 FuelFiltLifeRstReqd "Fuel Filter Life Reset Requested";
BA_ "SignalType" SG_ 1522 DispMeasSys "ENM";
BA_ "SignalLongName" SG_ 1522 DispMeasSys "Display Measurement System";
BA_ "SignalType" SG_ 1522 ClstrHMI_Rdy "ENM";
BA_ "SignalLongName" SG_ 1522 ClstrHMI_Rdy "Cluster HMI Ready";
BA_ "SignalType" SG_ 1522 APARghtSftBtnStatIPC "ENM";
BA_ "SignalLongName" SG_ 1522 APARghtSftBtnStatIPC "Advanced Park Assist Right Soft Button Status IPC";
BA_ "SignalType" SG_ 1522 APALftSftBtnStatIPC "ENM";
BA_ "SignalLongName" SG_ 1522 APALftSftBtnStatIPC "Advanced Park Assist Left Soft Button Status IPC";
BA_ "SignalType" SG_ 1522 APAFcStatIPC "ENM";
BA_ "SignalLongName" SG_ 1522 APAFcStatIPC "Advanced Park Assist Focus Status IPC";
BA_ "SignalType" SG_ 1522 AmbtLgtGblPrxmtyEnCstChgSetReq "ENM";
BA_ "SignalLongName" SG_ 1522 AmbtLgtGblPrxmtyEnCstChgSetReq "Ambient Light Global Proximity Enable Customization Change Setting Request";
BA_ "SignalType" SG_ 1522 TSMWrngPopUpSts "ENM";
BA_ "SignalLongName" SG_ 1522 TSMWrngPopUpSts "Traffic Sign Memory Warning Pop Up Status";
BA_ "SignalType" SG_ 1522 TSMSgnNtfnWrnDispd "ENM";
BA_ "SignalLongName" SG_ 1522 TSMSgnNtfnWrnDispd "Traffic Sign Memory Sign Notification Warning Displayed";
BA_ "SignalType" SG_ 1522 TSMPageDispActv "ENM";
BA_ "SignalLongName" SG_ 1522 TSMPageDispActv "Traffic Sign Memory Page Display Active";
BA_ "SignalType" SG_ 1522 TSMCustRstReq "ENM";
BA_ "SignalLongName" SG_ 1522 TSMCustRstReq "Traffic Sign Memory Customer Reset Request";
BA_ "SignalType" SG_ 1522 StrgWhlCtlInCarVcCommCtlSw "ENM";
BA_ "SignalLongName" SG_ 1522 StrgWhlCtlInCarVcCommCtlSw "Steering Wheel Control In Car Voice Communication Control Switch";
BA_ "SignalLongName" SG_ 1247 Trip1Odo "Trip 1 Odometer";
BA_ "SignalType" SG_ 1247 Trip1Odo_Inv "ENM";
BA_ "SignalLongName" SG_ 1247 Trip1Odo_Inv "Trip 1 Odometer Invalid";
BA_ "SignalLongName" SG_ 1247 Trip2Odo "Trip 2 Odometer";
BA_ "SignalType" SG_ 1247 Trip2Odo_Inv "ENM";
BA_ "SignalLongName" SG_ 1247 Trip2Odo_Inv "Trip 2 Odometer Invalid";
BA_ "SignalType" SG_ 1247 LnchCtlWhlSlReq "ENM";
BA_ "SignalLongName" SG_ 1247 LnchCtlWhlSlReq "Launch Control Wheel Slip Request";
BA_ "SignalType" SG_ 1247 LnchCtlEngRPMReq "ENM";
BA_ "SignalLongName" SG_ 1247 LnchCtlEngRPMReq "Launch Control Engine RPM Request";
BA_ "SignalType" SG_ 1247 EngAirFiltMonDrvrReq "ENM";
BA_ "SignalLongName" SG_ 1247 EngAirFiltMonDrvrReq "Engine Air Filter Monitor Driver Request";
BA_ "SignalType" SG_ 1247 BrkPadLifeSysDrvrReq "ENM";
BA_ "SignalLongName" SG_ 1247 BrkPadLifeSysDrvrReq "Brake Pad Life System Driver Request";
BA_ "SignalType" SG_ 1819 TCStmpDsblReqConf "ENM";
BA_ "SignalLongName" SG_ 1819 TCStmpDsblReqConf "TractionControlSystemTemporaryDisableRequestConfirmation";
BA_ "SignalType" SG_ 1819 TCSCurrStReq "ENM";
BA_ "SignalLongName" SG_ 1819 TCSCurrStReq "Traction Control System Current State Request";
BA_ "SignalType" SG_ 1819 LnchCtlModeReq "ENM";
BA_ "SignalLongName" SG_ 1819 LnchCtlModeReq "Launch Control Mode Request";
BA_ "SignalType" SG_ 1819 RdHgtAtLocStorConf "ENM";
BA_ "SignalLongName" SG_ 1819 RdHgtAtLocStorConf "Ride Height Auto Location Store Confirmation";
BA_ "SignalType" SG_ 1819 EngOilLifeRstReq "ENM";
BA_ "SignalLongName" SG_ 1819 EngOilLifeRstReq "Engine Oil Life Reset Request";
BA_ "SignalType" SG_ 1819 VehStbEnhCurrStReq "ENM";
BA_ "SignalLongName" SG_ 1819 VehStbEnhCurrStReq "VehicleStabilityEnhancementCurrentStateRequest";
BA_ "SignalType" SG_ 1819 VehStbCompMdCurrStReq "ENM";
BA_ "SignalLongName" SG_ 1819 VehStbCompMdCurrStReq "VehicleStabilityCompetitiveModeCurrentStateRequest";
BA_ "SignalType" SG_ 1819 TPMTrLdnRstReq "ENM";
BA_ "SignalLongName" SG_ 1819 TPMTrLdnRstReq "Tire Pressure Monitoring Tire Loading Reset Requested";
BA_ "SignalType" SG_ 1819 VehFlRngLwIO "ENM";
BA_ "SignalLongName" SG_ 1819 VehFlRngLwIO "Vehicle Fuel Range Low Indication On";
BA_ "SignalType" SG_ 1819 TrnsOilLfRstRq "ENM";
BA_ "SignalLongName" SG_ 1819 TrnsOilLfRstRq "Transmission Oil Life Reset Request";
BA_ "SignalType" SG_ 1819 TripBEleclEngyEconRstReqd "ENM";
BA_ "SignalLongName" SG_ 1819 TripBEleclEngyEconRstReqd "Trip B Electrical Energy Economy Reset Requested";
BA_ "SignalType" SG_ 1819 TripAEleclEngyEconRstReqd "ENM";
BA_ "SignalLongName" SG_ 1819 TripAEleclEngyEconRstReqd "Trip A Electrical Energy Economy Reset Requested";
BA_ "SignalType" SG_ 1819 TPSnsrProgEvReq "ENM";
BA_ "SignalLongName" SG_ 1819 TPSnsrProgEvReq "Tire Pressure Sensor Programming Event Requested";
BA_ "SignalType" SG_ 1819 LnchCtlRelLineLckReqd "ENM";
BA_ "SignalLongName" SG_ 1819 LnchCtlRelLineLckReqd "Launch Control Release Line Lock Requested";
BA_ "SignalType" SG_ 1819 FobProgEvntRqd "ENM";
BA_ "SignalLongName" SG_ 1819 FobProgEvntRqd "Fob Programming Event Requested";
BA_ "SignalType" SG_ 1819 ACCAutoSetSpdCstChgSetReq "ENM";
BA_ "SignalLongName" SG_ 1819 ACCAutoSetSpdCstChgSetReq "Adaptive Cruise Control Auto Set Speed Customization Change Setting Request";
BA_ "SignalType" SG_ 1819 DMSDrwIntnWrnDrvrResp "ENM";
BA_ "SignalLongName" SG_ 1819 DMSDrwIntnWrnDrvrResp "Driver Monitoring System Drowsy And Inattentive Warning Driver Response";
BA_ "SignalType" SG_ 1819 TransOilFiltLifeRstReq "ENM";
BA_ "SignalLongName" SG_ 1819 TransOilFiltLifeRstReq "Transmission Oil Filter Life Reset Request";
BA_ "SignalType" SG_ 1819 CustmStbCtlRdctReqConf "ENM";
BA_ "SignalLongName" SG_ 1819 CustmStbCtlRdctReqConf "Custom Stability Control Reduction Request Confirmation";
BA_ "SignalLongName" SG_ 1884 EngLifetmRotns "Engine Life time Rotations";
BA_ "SignalLongName" SG_ 1884 EngIdleActvTm "Engine Idle Active Time";
BA_ "SignalLongName" SG_ 1884 FuelEconShrtTrmAvg "Fuel Economy Short Term Average";
BA_ "SignalType" SG_ 1884 FllwgDstIndTmDstSel "ENM";
BA_ "SignalLongName" SG_ 1884 FllwgDstIndTmDstSel "Following Distance Indicator Time Distance Selected";
BA_ "SignalLongName" SG_ 1181 EngRunActvTm "Engine Run Active Time";
BA_ "SignalLongName" SG_ 1181 VehFlRngCalc "VehicleFuelRangeCalculated";
BA_ "SignalType" SG_ 1181 VehFlRngCalc_Inv "ENM";
BA_ "SignalLongName" SG_ 1181 VehFlRngCalc_Inv "Vehicle Fuel Range Calculated Invalid";
BA_ "SignalType" SG_ 1181 VehSpdBsgDispStat "ENM";
BA_ "SignalLongName" SG_ 1181 VehSpdBsgDispStat "Vehicle Speed Biasing Display State";
BA_ "SignalType" SG_ 1181 FuelLvlLoIndOn "ENM";
BA_ "SignalLongName" SG_ 1181 FuelLvlLoIndOn "Fuel Level Low Indication On";
BA_ "SignalType" SG_ 1820 MFCInfoActvnReqd "ENM";
BA_ "SignalLongName" SG_ 1820 MFCInfoActvnReqd "Multi Function Controller Infotainment Activation Requested";
BA_ "SignalLongName" SG_ 1245 PDRRI_CrLpTmMins "Performance Data Recorder Realtime Information : Performance Data Recorder Realtime Information Current Lap Time Minutes";
BA_ "SignalLongName" SG_ 1245 PDRRI_CrLpTm10sSec "Performance Data Recorder Realtime Information : Performance Data Recorder Realtime Information Current Lap Time Tenths of a Second";
BA_ "SignalLongName" SG_ 1245 PDRRI_CrLpTmSecs "Performance Data Recorder Realtime Information : Performance Data Recorder Realtime Information Current Lap Time Seconds";
BA_ "SignalLongName" SG_ 1245 PDRRI_LpDiffTmSecs "Performance Data Recorder Realtime Information : Performance Data Recorder Realtime Information Lap Differential Time Seconds";
BA_ "SignalLongName" SG_ 1245 PDRRI_LpDiffTm10s "Performance Data Recorder Realtime Information : Performance Data Recorder Realtime Information Lap Differential Time Tenths of a Second";
BA_ "SignalLongName" SG_ 1245 PDRBLI_BstLpTm100s "Performance Data Recorder Best Lap Information : Performance Data Recorder Best Lap Information Best Lap Time Hundredths of a Second";
BA_ "SignalType" SG_ 1245 PDRRI_LpDiffGainLoss "ENM";
BA_ "SignalLongName" SG_ 1245 PDRRI_LpDiffGainLoss "Performance Data Recorder Realtime Information : Performance Data Recorder Realtime Information Lap Differential Gain Loss";
BA_ "SignalLongName" SG_ 1245 PDRBLI_BstLpTmSecs "Performance Data Recorder Best Lap Information : Performance Data Recorder Best Lap Information Best Lap Time Seconds";
BA_ "SignalLongName" SG_ 1245 PDRBLI_BstLpTmMins "Performance Data Recorder Best Lap Information : Performance Data Recorder Best Lap Information Best Lap Time Minutes";
BA_ "SignalLongName" SG_ 1245 PDRLLI_LstLpTm100s "Performance Data Recorder Last Lap Information : Performance Data Recorder Last Lap Information Last Lap Time Hundredths of a Second";
BA_ "SignalLongName" SG_ 1245 PDRLLI_LstLpTmMins "Performance Data Recorder Last Lap Information : Performance Data Recorder Last Lap Information Last Lap Time Minutes";
BA_ "SignalLongName" SG_ 1245 PDRLLI_LstLpTmSecs "Performance Data Recorder Last Lap Information : Performance Data Recorder Last Lap Information Last Lap Time Seconds";
BA_ "SignalType" SG_ 1821 LVMAVR_PrmtAudReq "ENM";
BA_ "SignalLongName" SG_ 1821 LVMAVR_PrmtAudReq "Low Volume Module Audio Video Request : Prompt Audio Request";
BA_ "SignalType" SG_ 1821 LVMAVR_DispReq "ENM";
BA_ "SignalLongName" SG_ 1821 LVMAVR_DispReq "Low Volume Module Audio Video Request : Display Request";
BA_ "SignalType" SG_ 1821 LVMAVR_ApplStat "ENM";
BA_ "SignalLongName" SG_ 1821 LVMAVR_ApplStat "Low Volume Module Audio Video Request : Application State";
BA_ "SignalType" SG_ 1821 IconRcrdReqActv "ENM";
BA_ "SignalLongName" SG_ 1821 IconRcrdReqActv "Icon Record Request Active";
BA_ "SignalType" SG_ 1821 LVMAVR_StreoAudReq "ENM";
BA_ "SignalLongName" SG_ 1821 LVMAVR_StreoAudReq "Low Volume Module Audio Video Request : Stereo Audio Request";
BA_ "SignalType" SG_ 1821 LVMAVR_SpchRcgnActv "ENM";
BA_ "SignalLongName" SG_ 1821 LVMAVR_SpchRcgnActv "Low Volume Module Audio Video Request : Speech Recognition Active";
BA_ "SignalLongName" SG_ 56 V2VE1_HptcStReqSeqNum "Vehicle to Vehicle Event 1 : Haptic Seat Request Sequence Number";
BA_ "SignalLongName" SG_ 56 V2VE1_HptcStReqPuls "Vehicle to Vehicle Event 1 : Haptic Seat Request Pulses";
BA_ "SignalLongName" SG_ 56 V2VE2_HptcStReqSeqNum "Vehicle to Vehicle Event 2 : Haptic Seat Request Sequence Number";
BA_ "SignalLongName" SG_ 56 V2VE2_HptcStReqPuls "Vehicle to Vehicle Event 2 : Haptic Seat Request Pulses";
BA_ "SignalLongName" SG_ 56 V2VE3_HptcStReqSeqNum "Vehicle to Vehicle Event 3 : Haptic Seat Request Sequence Number";
BA_ "SignalLongName" SG_ 56 V2VE3_HptcStReqPuls "Vehicle to Vehicle Event 3 : Haptic Seat Request Pulses";
BA_ "SignalLongName" SG_ 56 V2VE4_HptcStReqSeqNum "Vehicle to Vehicle Event 4 : Haptic Seat Request Sequence Number";
BA_ "SignalLongName" SG_ 56 V2VE4_HptcStReqPuls "Vehicle to Vehicle Event 4 : Haptic Seat Request Pulses";
BA_ "SignalLongName" SG_ 56 V2VE5_HptcStReqSeqNum "Vehicle to Vehicle Event 5 : Haptic Seat Request Sequence Number";
BA_ "SignalLongName" SG_ 56 V2VE5_HptcStReqPuls "Vehicle to Vehicle Event 5 : Haptic Seat Request Pulses";
BA_ "SignalLongName" SG_ 56 V2VE6_HptcStReqSeqNum "Vehicle to Vehicle Event 6 : Haptic Seat Request Sequence Number";
BA_ "SignalLongName" SG_ 56 V2VE6_HptcStReqPuls "Vehicle to Vehicle Event 6 : Haptic Seat Request Pulses";
BA_ "SignalLongName" SG_ 729 PrcsPsngSysSigAcqTm "Precise Positioning System Signal Acquisition Time";
BA_ "SignalType" SG_ 729 TeleAlrmVisReq "ENM";
BA_ "SignalLongName" SG_ 729 TeleAlrmVisReq "TelematicsAlarmVisualRequest";
BA_ "SignalType" SG_ 729 TeleAlrmHrnReq "ENM";
BA_ "SignalLongName" SG_ 729 TeleAlrmHrnReq "TelematicsAlarmHornRequest";
BA_ "SignalType" SG_ 729 RmtTrlrLtngSeqReq "ENM";
BA_ "SignalLongName" SG_ 729 RmtTrlrLtngSeqReq "Remote Trailer Lighting Sequence Request";
BA_ "SignalLongName" SG_ 1443 ASVSC_VolReq "Audio System Volume Setting Control : Volume Request";
BA_ "SignalType" SG_ 1443 ASVSC_ReqEnbld "ENM";
BA_ "SignalLongName" SG_ 1443 ASVSC_ReqEnbld "Audio System Volume Setting Control : Request Enabled";
BA_ "SignalType" SG_ 1443 AudSeltdSrcReq "ENM";
BA_ "SignalLongName" SG_ 1443 AudSeltdSrcReq "Audio Selected Source Request";
BA_ "SignalType" SG_ 1443 V2VEvnt2ChmEvntStat "ENM";
BA_ "SignalLongName" SG_ 1443 V2VEvnt2ChmEvntStat "Vehicle to Vehicle Event 2 Chime Event State";
BA_ "SignalType" SG_ 1443 V2VEvnt1ChmEvntStat "ENM";
BA_ "SignalLongName" SG_ 1443 V2VEvnt1ChmEvntStat "Vehicle to Vehicle Event 1 Chime Event State";
BA_ "SignalType" SG_ 1443 TBTTrnChmEvntStat "ENM";
BA_ "SignalLongName" SG_ 1443 TBTTrnChmEvntStat "TBT at Turn ChimeEventState";
BA_ "SignalType" SG_ 1443 V2XOprtlStsInd "ENM";
BA_ "SignalLongName" SG_ 1443 V2XOprtlStsInd "V2X Operational Status Indication";
BA_ "SignalType" SG_ 1443 V2VEvnt6ChmEvntStat "ENM";
BA_ "SignalLongName" SG_ 1443 V2VEvnt6ChmEvntStat "Vehicle to Vehicle Event 6 Chime Event State";
BA_ "SignalType" SG_ 1443 V2VEvnt5ChmEvntStat "ENM";
BA_ "SignalLongName" SG_ 1443 V2VEvnt5ChmEvntStat "Vehicle to Vehicle Event 5 Chime Event State";
BA_ "SignalType" SG_ 1443 V2VEvnt4ChmEvntStat "ENM";
BA_ "SignalLongName" SG_ 1443 V2VEvnt4ChmEvntStat "Vehicle to Vehicle Event 4 Chime Event State";
BA_ "SignalType" SG_ 1443 V2VEvnt3ChmEvntStat "ENM";
BA_ "SignalLongName" SG_ 1443 V2VEvnt3ChmEvntStat "Vehicle to Vehicle Event 3 Chime Event State";
BA_ "SignalType" SG_ 1443 V2VAlrtAudAttnReqd "ENM";
BA_ "SignalLongName" SG_ 1443 V2VAlrtAudAttnReqd "Vehicle to Vehicle Alert Audio Attenuation Requested";
BA_ "SignalType" SG_ 1523 TAR_AudSrcStat "ENM";
BA_ "SignalLongName" SG_ 1523 TAR_AudSrcStat "Telematics Audio Request : Audio Source Status";
BA_ "SignalType" SG_ 1523 TAR_AudConctReq "ENM";
BA_ "SignalLongName" SG_ 1523 TAR_AudConctReq "Telematics Audio Request : Audio Connection Request";
BA_ "SignalLongName" SG_ 1822 TunerFreqChanReq "Tuner Frequency Channel Request";
BA_ "SignalType" SG_ 1822 InfoActivtnReq "ENM";
BA_ "SignalLongName" SG_ 1822 InfoActivtnReq "Infotainment Activation Request";
BA_ "SignalType" SG_ 1822 TnrFreqBndReq "ENM";
BA_ "SignalLongName" SG_ 1822 TnrFreqBndReq "Tuner Frequency Band Request";
BA_ "SignalLongName" SG_ 1243 V2VT_LgtMaxDispLim "Vehicle to Vehicle Traffic : Light Maximum Display Limit";
BA_ "SignalType" SG_ 1243 V2VT_LgtActlPhs "ENM";
BA_ "SignalLongName" SG_ 1243 V2VT_LgtActlPhs "Vehicle to Vehicle Traffic : Light Actual Phase";
BA_ "SignalType" SG_ 1243 V2VT_EmrgVehWrnDir "ENM";
BA_ "SignalLongName" SG_ 1243 V2VT_EmrgVehWrnDir "Vehicle to Vehicle Traffic : Emergency Vehicle Warning Direction";
BA_ "SignalLongName" SG_ 1243 V2VT_LgtMaxRcmndSpd "Vehicle to Vehicle Traffic : Light Maximum Recommended Speed";
BA_ "SignalLongName" SG_ 1243 V2VT_LgtMinRcmndSpd "Vehicle to Vehicle Traffic : Light Minimum Recommended Speed";
BA_ "SignalLongName" SG_ 1243 V2VT_LgtTmToPhsSw "Vehicle to Vehicle Traffic : Light Time to Phase Switch";
BA_ "SignalType" SG_ 1243 V2VT_LgtPhsAtArvl "ENM";
BA_ "SignalLongName" SG_ 1243 V2VT_LgtPhsAtArvl "Vehicle to Vehicle Traffic : Light Phase at Arrival";
BA_ "SignalLongName" SG_ 1243 V2VT_WrnDistRmn "Vehicle to Vehicle Traffic : Warning Distance Remaining";
BA_ "SignalType" SG_ 1243 V2VT_LgtVldDir "ENM";
BA_ "SignalLongName" SG_ 1243 V2VT_LgtVldDir "Vehicle to Vehicle Traffic : Light Valid Direction";
BA_ "SignalLongName" SG_ 1243 TnDrvrVolLimRmtCstLvlChgSetReq "Teen DriverVolume Limit Remote Customization Request : Teen Driver Volume Limit Remote Customization Level Change Setting Request";
BA_ "SignalType" SG_ 1243 V2VT_WrnIndReq "ENM";
BA_ "SignalLongName" SG_ 1243 V2VT_WrnIndReq "Vehicle to Vehicle Traffic : Warning Indication Request";
BA_ "SignalType" SG_ 1243 TnDrvrVolLimRmtCstChgSetReq "ENM";
BA_ "SignalLongName" SG_ 1243 TnDrvrVolLimRmtCstChgSetReq "Teen DriverVolume Limit Remote Customization Request : Teen Driver Volume Limit Remote Customization Change Setting Request";
BA_ "SignalType" SG_ 1886 EmrgRespSysTyp "ENM";
BA_ "SignalLongName" SG_ 1886 EmrgRespSysTyp "Emergency Response System Type";
BA_ "SignalLongName" SG_ 1888 TCP_LCMDataAvlblChksum "LicenseComplianceMaterialDisplayInterface : TCP_LCMDataAvailableChecksum";
BA_ "SignalLongName" SG_ 1888 TCP_LCMDataAvlblLicTag "LicenseComplianceMaterialDisplayInterface : TCP_LCMDataAvailableLicenseTag";
BA_ "SignalLongName" SG_ 1888 TCP_LCMDataAvlblOwnID "LicenseComplianceMaterialDisplayInterface : TCP_LCMDataAvailableOwnerID";
BA_ "SignalLongName" SG_ 1888 TCP_LCMDataAvlblTotBlks "LicenseComplianceMaterialDisplayInterface : TCP_LCMDataAvailableTotalBlocks";
BA_ "SignalLongName" SG_ 1507 RDMACANFCPP_RadDevMACAddr "Radio Device MAC Address and Near Field Communication Pairing Permission : Radio Device MAC Address";
BA_ "SignalType" SG_ 1507 ByclDtnCstChgSetReq "ENM";
BA_ "SignalLongName" SG_ 1507 ByclDtnCstChgSetReq "Bicycle Detection Customization Change Setting Request";
BA_ "SignalType" SG_ 1507 LBCCDRR_PstnNumReq "ENM";
BA_ "SignalLongName" SG_ 1507 LBCCDRR_PstnNumReq "Location Based Charging Customer Data Reset Request : Position Number Request";
BA_ "SignalType" SG_ 1507 LBCCDRR_ClrStrdPstnReq "ENM";
BA_ "SignalLongName" SG_ 1507 LBCCDRR_ClrStrdPstnReq "Location Based Charging Customer Data Reset Request : Clear Stored Position Request";
BA_ "SignalType" SG_ 1507 RDMACANFCPP_RadDevPrngNFCAllwd "ENM";
BA_ "SignalLongName" SG_ 1507 RDMACANFCPP_RadDevPrngNFCAllwd "Radio Device MAC Address and Near Field Communication Pairing Permission : Radio Device Pairing via Near Field Communication is Allowed";
BA_ "SignalType" SG_ 1507 NFCICRstReqd "ENM";
BA_ "SignalLongName" SG_ 1507 NFCICRstReqd "Near Field Communication Integrated Circuit Reset Requested";
BA_ "SignalType" SG_ 1507 HillDscntCtlCurrStatReq "ENM";
BA_ "SignalLongName" SG_ 1507 HillDscntCtlCurrStatReq "Hill Descent Control Current State Request";
BA_ "SignalType" SG_ 1507 RadioDevBTPrngSts "ENM";
BA_ "SignalLongName" SG_ 1507 RadioDevBTPrngSts "Radio Device Bluetooth Pairing Status";
BA_ "SignalLongName" SG_ 1823 RPSU_ExpTmLgth "Remote Programming Scheduled Update : Expected Time Length";
BA_ "SignalLongName" SG_ 1823 RPSU_Dy "Remote Programming Scheduled Update : Day";
BA_ "SignalLongName" SG_ 1823 RPSU_Hr "Remote Programming Scheduled Update : Hour";
BA_ "SignalLongName" SG_ 1823 RPSU_Mins "Remote Programming Scheduled Update : Minutes";
BA_ "SignalLongName" SG_ 1823 RPSU_Secs "Remote Programming Scheduled Update : Seconds";
BA_ "SignalType" SG_ 1823 RPSU_Mth "ENM";
BA_ "SignalLongName" SG_ 1823 RPSU_Mth "Remote Programming Scheduled Update : Month";
BA_ "SignalLongName" SG_ 1823 RPSU_Yr "Remote Programming Scheduled Update : Year";
BA_ "SignalType" SG_ 1823 RPSU_Sts "ENM";
BA_ "SignalLongName" SG_ 1823 RPSU_Sts "Remote Programming Scheduled Update : Status";
BA_ "SignalType" SG_ 1823 RadioDevBTDscvrblSts "ENM";
BA_ "SignalLongName" SG_ 1823 RadioDevBTDscvrblSts "Radio Device Bluetooth Discoverable Status";
BA_ "SignalType" SG_ 1823 InfoFrtSnshdMtnReq "ENM";
BA_ "SignalLongName" SG_ 1823 InfoFrtSnshdMtnReq "DEPRECATED VIP 24 - Infotainment Front Sunshade Motion Request";
BA_ "SignalLongName" SG_ 40 LCMDI_WCM_DatAvalCksum "License Compliance Material Display Interface - Wireless Charger Module : Data Available Checksum";
BA_ "SignalLongName" SG_ 40 LCMDI_WCM_DatAvalLicTag "License Compliance Material Display Interface - Wireless Charger Module : Data Available License Tag";
BA_ "SignalLongName" SG_ 40 LCMDI_WCM_DatAvalOwnID "License Compliance Material Display Interface - Wireless Charger Module : Data Available Owner Identification";
BA_ "SignalLongName" SG_ 40 LCMDI_WCM_DatAvalTotBlks "License Compliance Material Display Interface - Wireless Charger Module : Data Available Total Blocks";
BA_ "SignalType" SG_ 1524 PhnLtInVehCstSetAval "ENM";
BA_ "SignalLongName" SG_ 1524 PhnLtInVehCstSetAval "Phone Left In Vehicle Customization Setting Available";
BA_ "SignalType" SG_ 1524 PhnLtInVehCstCurrSetVal "ENM";
BA_ "SignalLongName" SG_ 1524 PhnLtInVehCstCurrSetVal "Phone Left In Vehicle Customization Current Setting Value";
BA_ "SignalLongName" SG_ 1242 RmtDevBTMACAddr "Remote Device Bluetooth MAC Address";
BA_ "SignalType" SG_ 1242 WrlsChrgSysChrgStat "ENM";
BA_ "SignalLongName" SG_ 1242 WrlsChrgSysChrgStat "Wireless Charging System 1 Charging Status";
BA_ "SignalType" SG_ 1242 NFCEHS_NFCStcRstOcc "ENM";
BA_ "SignalLongName" SG_ 1242 NFCEHS_NFCStcRstOcc "Near Field Communication Error and Handover Status : Near Field Communication Static Reset Occurred";
BA_ "SignalType" SG_ 1242 NFCEHS_NFCHndvrSts "ENM";
BA_ "SignalLongName" SG_ 1242 NFCEHS_NFCHndvrSts "Near Field Communication Error and Handover Status : Near Field Communication Handover Status";
BA_ "SignalType" SG_ 1242 NFCEHS_NFCErrRFInterErrOOR "ENM";
BA_ "SignalLongName" SG_ 1242 NFCEHS_NFCErrRFInterErrOOR "Near Field Communication Error and Handover Status : Near Field Communication Error RF Interface Error or Out of Range";
BA_ "SignalType" SG_ 1242 PhnWrlsChrg1DsbldCstAvlFlg3 "ENM";
BA_ "SignalLongName" SG_ 1242 PhnWrlsChrg1DsbldCstAvlFlg3 "Phone Wireless Charging 1 Disabled Customization Availability Flag 3";
BA_ "SignalType" SG_ 1242 PhnWrlsChrg1DsbldCstAvlFlg2 "ENM";
BA_ "SignalLongName" SG_ 1242 PhnWrlsChrg1DsbldCstAvlFlg2 "Phone Wireless Charging 1 Disabled Customization Availability Flag 2";
BA_ "SignalType" SG_ 1242 PhnWrlsChrg1DsbldCstAvlFlg1 "ENM";
BA_ "SignalLongName" SG_ 1242 PhnWrlsChrg1DsbldCstAvlFlg1 "Phone Wireless Charging 1 Disabled Customization Availability Flag 1";
BA_ "SignalType" SG_ 1242 PhnWrlsChrg1DsbldCstCurrSetVal "ENM";
BA_ "SignalLongName" SG_ 1242 PhnWrlsChrg1DsbldCstCurrSetVal "Phone Wireless Charging 1 Disabled Customization Current Setting Value";
BA_ "SignalType" SG_ 1242 PhnLtInVehIndOn "ENM";
BA_ "SignalLongName" SG_ 1242 PhnLtInVehIndOn "DEPRECATED VIP 24 - Phone Left In Vehicle Indication On";
BA_ "SignalType" SG_ 1242 NFCDevDtd "ENM";
BA_ "SignalLongName" SG_ 1242 NFCDevDtd "Near Field Communication Device Detected";
BA_ "SignalType" SG_ 1178 PhnLtInVehCstAvlFlg7 "ENM";
BA_ "SignalLongName" SG_ 1178 PhnLtInVehCstAvlFlg7 "Phone Left In Vehicle Customization Availability Flag 7";
BA_ "SignalType" SG_ 1178 PhnLtInVehCstAvlFlg6 "ENM";
BA_ "SignalLongName" SG_ 1178 PhnLtInVehCstAvlFlg6 "Phone Left In Vehicle Customization Availability Flag 6";
BA_ "SignalType" SG_ 1178 PhnLtInVehCstAvlFlg5 "ENM";
BA_ "SignalLongName" SG_ 1178 PhnLtInVehCstAvlFlg5 "Phone Left In Vehicle Customization Availability Flag 5";
BA_ "SignalType" SG_ 1178 PhnLtInVehCstAvlFlg4 "ENM";
BA_ "SignalLongName" SG_ 1178 PhnLtInVehCstAvlFlg4 "Phone Left In Vehicle Customization Availability Flag 4";
BA_ "SignalType" SG_ 1178 PhnLtInVehCstAvlFlg3 "ENM";
BA_ "SignalLongName" SG_ 1178 PhnLtInVehCstAvlFlg3 "Phone Left In Vehicle Customization Availability Flag 3";
BA_ "SignalType" SG_ 1178 PhnLtInVehCstAvlFlg2 "ENM";
BA_ "SignalLongName" SG_ 1178 PhnLtInVehCstAvlFlg2 "Phone Left In Vehicle Customization Availability Flag 2";
BA_ "SignalType" SG_ 1178 PhnLtInVehCstAvlFlg1 "ENM";
BA_ "SignalLongName" SG_ 1178 PhnLtInVehCstAvlFlg1 "Phone Left In Vehicle Customization Availability Flag 1";
BA_ "SignalLongName" SG_ 728 HVACTCR_ARC "HVAC Telematics Controls Request : Alive Rolling Count";
BA_ "SignalType" SG_ 728 HVACTlmCtlTempLvlActvReqd "ENM";
BA_ "SignalLongName" SG_ 728 HVACTlmCtlTempLvlActvReqd "HVAC Telematics Controls Request : HVAC Telematics Controls Temperature Level Active Requested";
BA_ "SignalLongName" SG_ 728 HVACTlmCtlTempLvlReq "HVAC Telematics Controls Request : HVAC Telematics Controls Temperature Level Request";
BA_ "SignalType" SG_ 1478 VCCLR_CrgMirLmp "ENM";
BA_ "SignalLongName" SG_ 1478 VCCLR_CrgMirLmp "Virtual Control Cargo Lamp Request : Cargo Mirrors Lamp";
BA_ "SignalType" SG_ 1478 VCCLR_CrgLmpHtch "ENM";
BA_ "SignalLongName" SG_ 1478 VCCLR_CrgLmpHtch "Virtual Control Cargo Lamp Request : Cargo Lamp Hitch";
BA_ "SignalType" SG_ 1478 VCCLR_CrgLmp "ENM";
BA_ "SignalLongName" SG_ 1478 VCCLR_CrgLmp "Virtual Control Cargo Lamp Request : Cargo Lamp";
BA_ "SignalType" SG_ 1478 VCCLR_CrgBedLmp "ENM";
BA_ "SignalLongName" SG_ 1478 VCCLR_CrgBedLmp "Virtual Control Cargo Lamp Request : Cargo Bed Lamp";
BA_ "SignalType" SG_ 1478 VCDLR_DomeLgt "ENM";
BA_ "SignalLongName" SG_ 1478 VCDLR_DomeLgt "Virtual Control Dome Light Request : Dome Light";
BA_ "SignalType" SG_ 1478 VCDLR_DomeDft "ENM";
BA_ "SignalLongName" SG_ 1478 VCDLR_DomeDft "Virtual Control Dome Light Request : Dome Defeat";
BA_ "SignalType" SG_ 1478 VirtCtlDrvModeReq "ENM";
BA_ "SignalLongName" SG_ 1478 VirtCtlDrvModeReq "Virtual Control Drive Mode Request";
BA_ "SignalType" SG_ 1478 VirtCtlAutoHiBmReq "ENM";
BA_ "SignalLongName" SG_ 1478 VirtCtlAutoHiBmReq "Virtual Control Auto High Beam Request";
BA_ "SignalType" SG_ 1478 TireLkDtnUsrReq "ENM";
BA_ "SignalLongName" SG_ 1478 TireLkDtnUsrReq "Tire Leak Detection User Request";
BA_ "SignalType" SG_ 1478 VirtCtlTskLmpReq "ENM";
BA_ "SignalLongName" SG_ 1478 VirtCtlTskLmpReq "Virtual Control Task Lamp Request";
BA_ "SignalType" SG_ 1478 VirtCtlPwrWndLckoutReq "ENM";
BA_ "SignalLongName" SG_ 1478 VirtCtlPwrWndLckoutReq "Virtual Control Power Window Lockout Request";
BA_ "SignalType" SG_ 1478 VirtCtlFgLmpRrReq "ENM";
BA_ "SignalLongName" SG_ 1478 VirtCtlFgLmpRrReq "Virtual Control Fog Lamps Rear Request";
BA_ "SignalType" SG_ 1478 VirtCtlFgLmpFrtReq "ENM";
BA_ "SignalLongName" SG_ 1478 VirtCtlFgLmpFrtReq "Virtual Control Fog Lamps Front Request";
BA_ "SignalType" SG_ 1478 VirtCtlChldSftyLckReq "ENM";
BA_ "SignalLongName" SG_ 1478 VirtCtlChldSftyLckReq "Virtual Control Child Safety Locks Request";
BA_ "SignalType" SG_ 1478 StVntdCoolBkLvlLFVirtCtlReq "ENM";
BA_ "SignalLongName" SG_ 1478 StVntdCoolBkLvlLFVirtCtlReq "Seat Heated Vented or Cooled Left Front Virtual Control Requests : Seat Vented or Cooled Back Level Left Front Virtual Control Request";
BA_ "SignalType" SG_ 1478 StHtdCushLvlLFVirtCtlReq "ENM";
BA_ "SignalLongName" SG_ 1478 StHtdCushLvlLFVirtCtlReq "Seat Heated Vented or Cooled Left Front Virtual Control Requests : Seat Heated Cushion Level Left Front Virtual Control Request";
BA_ "SignalType" SG_ 1478 StHtdBkLvlLFVirtCtlReq "ENM";
BA_ "SignalLongName" SG_ 1478 StHtdBkLvlLFVirtCtlReq "Seat Heated Vented or Cooled Left Front Virtual Control Requests : Seat Heated Back Level Left Front Virtual Control Request";
BA_ "SignalType" SG_ 1478 StVntdCoolCushLvlLFVirtCtlReq "ENM";
BA_ "SignalLongName" SG_ 1478 StVntdCoolCushLvlLFVirtCtlReq "Seat Heated Vented or Cooled Left Front Virtual Control Requests : Seat Vented or Cooled Cushion Level Left Front Virtual Control Request";
BA_ "SignalLongName" SG_ 1482 CldrYr "Calendar Date And Time : Year";
BA_ "SignalLongName" SG_ 1482 SecOfMin "Calendar Date And Time : Seconds";
BA_ "SignalLongName" SG_ 1482 MinOfHr "Calendar Date And Time : Minutes";
BA_ "SignalLongName" SG_ 1482 CldrDay "Calendar Date And Time : Day";
BA_ "SignalType" SG_ 1482 CldrMth "ENM";
BA_ "SignalLongName" SG_ 1482 CldrMth "Calendar Date And Time : Month";
BA_ "SignalLongName" SG_ 1482 HrOfDay "Calendar Date And Time : Hours";
BA_ "SignalType" SG_ 1482 PLCM_LCMFileTrans "ENM";
BA_ "SignalLongName" SG_ 1482 PLCM_LCMFileTrans "Power Line Communication Module - License Compliance Material File Transfer";
BA_ "SignalType" SG_ 1482 VirtCtlAuxAlrmSnsrReq "ENM";
BA_ "SignalLongName" SG_ 1482 VirtCtlAuxAlrmSnsrReq "DEPRECATED VIP 24 - Virtual Control Auxiliary Alarm Sensor Request";
BA_ "SignalType" SG_ 1482 AutoVehHldVirtReq "ENM";
BA_ "SignalLongName" SG_ 1482 AutoVehHldVirtReq "Auto Vehicle Hold Virtual Control Request";
BA_ "SignalType" SG_ 1482 PLCM_LCMDataMsgStat "ENM";
BA_ "SignalLongName" SG_ 1482 PLCM_LCMDataMsgStat "Power Line Communication Module - License Compliance Material Data Message Status";
BA_ "SignalType" SG_ 1517 CustMdDrvlCstChngSetReq "ENM";
BA_ "SignalLongName" SG_ 1517 CustMdDrvlCstChngSetReq "Custom Mode Driveline Customization Change Setting Request";
BA_ "SignalType" SG_ 1517 CustMdBrkPdlCstChngSetReq "ENM";
BA_ "SignalLongName" SG_ 1517 CustMdBrkPdlCstChngSetReq "Custom Mode Brake Pedal Customization Change Setting Request";
BA_ "SignalType" SG_ 1517 CustMdActAeroCstChngSetReq "ENM";
BA_ "SignalLongName" SG_ 1517 CustMdActAeroCstChngSetReq "Custom Mode Active Aero Customization Change Setting Request";
BA_ "SignalType" SG_ 1517 CustMdSndCstChngSetReq "ENM";
BA_ "SignalLongName" SG_ 1517 CustMdSndCstChngSetReq "Custom Mode Sound Customization Change Setting Request";
BA_ "SignalType" SG_ 1517 CustMdRideHghtCstChngSetReq "ENM";
BA_ "SignalLongName" SG_ 1517 CustMdRideHghtCstChngSetReq "Custom Mode Ride Height Customization Change Setting Request";
BA_ "SignalType" SG_ 1517 CustMdPTCstChngSetReq "ENM";
BA_ "SignalLongName" SG_ 1517 CustMdPTCstChngSetReq "Custom Mode Powertrain Customization Change Setting Request";
BA_ "SignalType" SG_ 1517 CustMdStrCstChngSetReq "ENM";
BA_ "SignalLongName" SG_ 1517 CustMdStrCstChngSetReq "Custom Mode Steering Customization Change Setting Request";
BA_ "SignalType" SG_ 1517 CustMdSpnCstChngSetReq "ENM";
BA_ "SignalLongName" SG_ 1517 CustMdSpnCstChngSetReq "Custom Mode Suspension Customization Change Setting Request";
BA_ "SignalType" SG_ 1517 LvlgSysAlgnMdCstChgSetReq "ENM";
BA_ "SignalLongName" SG_ 1517 LvlgSysAlgnMdCstChgSetReq "Leveling System Alignment Mode Customization Change Setting Request";
BA_ "SignalType" SG_ 1517 ExtdHillStrtAsstCstChgSetReq "ENM";
BA_ "SignalLongName" SG_ 1517 ExtdHillStrtAsstCstChgSetReq "Extended Hill Start Assist Customization Change Setting Request";
BA_ "SignalType" SG_ 1517 CustMdTrcStbCstChngSetReq "ENM";
BA_ "SignalLongName" SG_ 1517 CustMdTrcStbCstChngSetReq "Custom Mode Traction Stability Customization Change Setting Request";
BA_ "SignalType" SG_ 1517 PrsnlMdActAeroCstChngSetReq "ENM";
BA_ "SignalLongName" SG_ 1517 PrsnlMdActAeroCstChngSetReq "Personal Mode Active Aero Customization Change Setting Request";
BA_ "SignalType" SG_ 1517 LvlgSysServMdCstChgSetReq "ENM";
BA_ "SignalLongName" SG_ 1517 LvlgSysServMdCstChgSetReq "Leveling System Service Mode Customization Change Setting Request";
BA_ "SignalType" SG_ 1517 LvlgSysEntEgrsMdCstChgSetReq "ENM";
BA_ "SignalLongName" SG_ 1517 LvlgSysEntEgrsMdCstChgSetReq "Leveling System Entry Egress Mode Customization Change Setting Request";
BA_ "SignalType" SG_ 1517 PrsnlMdDrvlCstChngSetReq "ENM";
BA_ "SignalLongName" SG_ 1517 PrsnlMdDrvlCstChngSetReq "Personal Mode Driveline Customization Change Setting Request";
BA_ "SignalType" SG_ 1517 PrsnlMdBrkPdlCstChngSetReq "ENM";
BA_ "SignalLongName" SG_ 1517 PrsnlMdBrkPdlCstChngSetReq "Personal Mode Brake Pedal Customization Change Setting Request";
BA_ "SignalType" SG_ 1517 PrsnlMdSpnCstChngSetReq "ENM";
BA_ "SignalLongName" SG_ 1517 PrsnlMdSpnCstChngSetReq "Personal Mode Suspension Customization Change Setting Request";
BA_ "SignalType" SG_ 1517 PrsnlMdSndCstChngSetReq "ENM";
BA_ "SignalLongName" SG_ 1517 PrsnlMdSndCstChngSetReq "Personal Mode Sound Customization Change Setting Request";
BA_ "SignalType" SG_ 1517 PrsnlMdRideHghtCstChngSetReq "ENM";
BA_ "SignalLongName" SG_ 1517 PrsnlMdRideHghtCstChngSetReq "Personal Mode Ride Height Customization Change Setting Request";
BA_ "SignalType" SG_ 1517 CustmPT_CfgPgAct "ENM";
BA_ "SignalLongName" SG_ 1517 CustmPT_CfgPgAct "Custom Powertrain Configuration Page Active";
BA_ "SignalType" SG_ 1517 DrvrSeltdConf "ENM";
BA_ "SignalLongName" SG_ 1517 DrvrSeltdConf "Driver Selected Confirmation";
BA_ "SignalType" SG_ 1517 PrsnlMdStrCstChngSetReq "ENM";
BA_ "SignalLongName" SG_ 1517 PrsnlMdStrCstChngSetReq "Personal Mode Steering Customization Change Setting Request";
BA_ "SignalType" SG_ 1518 ACCCSR_Aux1Colr "ENM";
BA_ "SignalLongName" SG_ 1518 ACCCSR_Aux1Colr "Ambient Control Customization Change Setting Request : Auxiliary 1 Color";
BA_ "SignalType" SG_ 1518 ACCCSR_Aux1Brghtns "ENM";
BA_ "SignalLongName" SG_ 1518 ACCCSR_Aux1Brghtns "Ambient Control Customization Change Setting Request : Auxiliary 1 Brightness";
BA_ "SignalType" SG_ 1518 ACCCSR_Aux1Anm "ENM";
BA_ "SignalLongName" SG_ 1518 ACCCSR_Aux1Anm "Ambient Control Customization Change Setting Request : Auxiliary 1 Animation";
BA_ "SignalType" SG_ 1518 ACCCSR_IntrAnm "ENM";
BA_ "SignalLongName" SG_ 1518 ACCCSR_IntrAnm "Ambient Control Customization Change Setting Request : Interior Animation";
BA_ "SignalType" SG_ 1518 ACCCSR_IntrColr "ENM";
BA_ "SignalLongName" SG_ 1518 ACCCSR_IntrColr "Ambient Control Customization Change Setting Request : Interior Color";
BA_ "SignalType" SG_ 1518 ACCCSR_IntrBrghtns "ENM";
BA_ "SignalLongName" SG_ 1518 ACCCSR_IntrBrghtns "Ambient Control Customization Change Setting Request : Interior Brightness";
BA_ "SignalType" SG_ 1518 AutDrvLckCstChgSetReq "ENM";
BA_ "SignalLongName" SG_ 1518 AutDrvLckCstChgSetReq "Automatic Drive Locking Customization Change Setting Request";
BA_ "SignalType" SG_ 1518 AirQltySensCstChgSetReq "ENM";
BA_ "SignalLongName" SG_ 1518 AirQltySensCstChgSetReq "Air Quality Sensor Customization Change Setting Request";
BA_ "SignalType" SG_ 1518 AutoAirDstCstChgSetReq "ENM";
BA_ "SignalLongName" SG_ 1518 AutoAirDstCstChgSetReq "Auto Air Distribution Customization Change Setting Request";
BA_ "SignalType" SG_ 1518 AutUnlckCstChgSetReq "ENM";
BA_ "SignalLongName" SG_ 1518 AutUnlckCstChgSetReq "Automatic Unlocking Customization Change Setting Request";
BA_ "SignalType" SG_ 1518 AutoFanCstChgSetReq "ENM";
BA_ "SignalLongName" SG_ 1518 AutoFanCstChgSetReq "Automatic Fan Customization Change Setting Request";
BA_ "SignalType" SG_ 1518 AutoDfgCstChgSetReq "ENM";
BA_ "SignalLongName" SG_ 1518 AutoDfgCstChgSetReq "Automatic Defog Customization Change Setting Request";
BA_ "SignalType" SG_ 1518 AutoCoolStCstChgSetReq "ENM";
BA_ "SignalLongName" SG_ 1518 AutoCoolStCstChgSetReq "Automatic Cooled Seat Customization Change Setting Request";
BA_ "SignalType" SG_ 1518 AutoRrWpCstChgSetReq "ENM";
BA_ "SignalLongName" SG_ 1518 AutoRrWpCstChgSetReq "Auto Rear Wipe Customization Change Setting Request";
BA_ "SignalType" SG_ 1518 AutoMrFldCstChgSetReq "ENM";
BA_ "SignalLongName" SG_ 1518 AutoMrFldCstChgSetReq "Auto Mirror Fold Customization Change Setting Request";
BA_ "SignalType" SG_ 1518 AutoHtdStCstChgSetReq "ENM";
BA_ "SignalLongName" SG_ 1518 AutoHtdStCstChgSetReq "Automatic Heated Seat Customization Change Setting Request";
BA_ "SignalType" SG_ 1518 ExitLghtngCstChgSetReq "ENM";
BA_ "SignalLongName" SG_ 1518 ExitLghtngCstChgSetReq "Exit Lighting Customization Change Setting Request";
BA_ "SignalType" SG_ 1518 DayTmTlLtsCstChgSetReq "ENM";
BA_ "SignalLongName" SG_ 1518 DayTmTlLtsCstChgSetReq "Day Time Taillight Customization Change Setting Request";
BA_ "SignalType" SG_ 1424 LDCLCstChgSetReq "ENM";
BA_ "SignalLongName" SG_ 1424 LDCLCstChgSetReq "Last Door Closed Locking Customization Change Setting Request";
BA_ "SignalType" SG_ 1424 IonzrCtrlCstChgSetReq "ENM";
BA_ "SignalLongName" SG_ 1424 IonzrCtrlCstChgSetReq "Ionizer Control Customization Change Setting Request";
BA_ "SignalType" SG_ 1424 HFRCCstChgSetReq "ENM";
BA_ "SignalLongName" SG_ 1424 HFRCCstChgSetReq "Hands Free Rear Closure Customization Change Setting Request";
BA_ "SignalType" SG_ 1424 PsvUnlckCstChgSetReq "ENM";
BA_ "SignalLongName" SG_ 1424 PsvUnlckCstChgSetReq "Passive Unlocking Customization Change Setting Request";
BA_ "SignalType" SG_ 1424 PlltnCtrlCstChgSetReq "ENM";
BA_ "SignalLongName" SG_ 1424 PlltnCtrlCstChgSetReq "Pollution Control Customization Change Setting Request";
BA_ "SignalType" SG_ 1424 OpDrAtLOCstChgSetReq "ENM";
BA_ "SignalLongName" SG_ 1424 OpDrAtLOCstChgSetReq "Open Door Anti Lock Out Customization Change Setting Request";
BA_ "SignalType" SG_ 1424 RemInVehRmCstChgSetReq "ENM";
BA_ "SignalLongName" SG_ 1424 RemInVehRmCstChgSetReq "Remote In Vehicle Reminder Customization Change Setting Request";
BA_ "SignalType" SG_ 1424 PwrRrClsrCstChgSetReq "ENM";
BA_ "SignalLongName" SG_ 1424 PwrRrClsrCstChgSetReq "Power Rear Closure Customization Change Setting Request";
BA_ "SignalType" SG_ 1424 RevTltMrCstChgSetReq "ENM";
BA_ "SignalLongName" SG_ 1424 RevTltMrCstChgSetReq "Reverse Tilt Mirror Customization Change Setting Request";
BA_ "SignalType" SG_ 1424 RemWndOpCstChgSetReq "ENM";
BA_ "SignalLongName" SG_ 1424 RemWndOpCstChgSetReq "Remote Window Operation Customization Change Setting Request";
BA_ "SignalType" SG_ 1424 RemLftVehRmCstChgSetReq "ENM";
BA_ "SignalLongName" SG_ 1424 RemLftVehRmCstChgSetReq "Remote Left Vehcile Reminder Customization Change Setting Request";
BA_ "SignalType" SG_ 1424 RmtStrtCoolStCstChgSetReq "ENM";
BA_ "SignalLongName" SG_ 1424 RmtStrtCoolStCstChgSetReq "Remote Start Cooled Seat Customization Change Setting Request";
BA_ "SignalType" SG_ 1424 RmtSnrfOpCstChgSetReq "ENM";
BA_ "SignalLongName" SG_ 1424 RmtSnrfOpCstChgSetReq "Remote Sunroof Operation Customization Change Setting Request";
BA_ "SignalType" SG_ 1424 RlkRtUlkDrCstChSetReq "ENM";
BA_ "SignalLongName" SG_ 1424 RlkRtUlkDrCstChSetReq "Relock Remote Unlocked Door Customization Change Setting Request";
BA_ "SignalType" SG_ 1424 RnSnsCstChgSetReq "ENM";
BA_ "SignalLongName" SG_ 1424 RnSnsCstChgSetReq "Rain Sense Customization Change Setting Request";
BA_ "SignalType" SG_ 1424 RmtStrtHtdStCstChgSetReq "ENM";
BA_ "SignalLongName" SG_ 1424 RmtStrtHtdStCstChgSetReq "Remote Start Heated Seat Customization Change Setting Request";
BA_ "SignalType" SG_ 1424 RrZnStUpCstChgSetReq "ENM";
BA_ "SignalLongName" SG_ 1424 RrZnStUpCstChgSetReq "Rear Zone Startup Customization Change Setting Request";
BA_ "SignalType" SG_ 1424 RrStRmndrEnblDsblCstChgSetReq "ENM";
BA_ "SignalLongName" SG_ 1424 RrStRmndrEnblDsblCstChgSetReq "Rear Seat Reminder Enable Disable Customization Change Setting Request";
BA_ "SignalType" SG_ 1424 RrDfgStUpCstChgSetReq "ENM";
BA_ "SignalLongName" SG_ 1424 RrDfgStUpCstChgSetReq "Rear Defog Startup Customization Change Setting Request";
BA_ "SignalType" SG_ 1424 RtUlkLtFbCstChgSetReq "ENM";
BA_ "SignalLongName" SG_ 1424 RtUlkLtFbCstChgSetReq "Remote Unlock Lighting Feedback Customization Change Setting Request";
BA_ "SignalType" SG_ 1424 RtLkFdbkCstChgSetReq "ENM";
BA_ "SignalLongName" SG_ 1424 RtLkFdbkCstChgSetReq "Remote Locking Feedback Customization Change Setting Request";
BA_ "SignalLongName" SG_ 1506 TODCSR_ChrgSchedHrOfDyReq "Time of Day Charging Setting Request : Charge Schedule Hour of Day Request";
BA_ "SignalType" SG_ 1506 TODCSR_ChrgSchedDyOfWkReq "ENM";
BA_ "SignalLongName" SG_ 1506 TODCSR_ChrgSchedDyOfWkReq "Time of Day Charging Setting Request : Charge Schedule Day of Week Request";
BA_ "SignalType" SG_ 1506 TODCSR_ChrgSchedCstSetReq "ENM";
BA_ "SignalLongName" SG_ 1506 TODCSR_ChrgSchedCstSetReq "Time of Day Charging Setting Request : Charge Schedule Customization Setting Request";
BA_ "SignalLongName" SG_ 1506 TODCSR_ChrgSchedMinOfHrReq "Time of Day Charging Setting Request : Charge Schedule Minute of Hour Request";
BA_ "SignalLongName" SG_ 1506 TODCSR_ERSPrdHrOfDyReq "Time of Day Charging Setting Request : Electric Rate Schedule Period Hour of Day Request";
BA_ "SignalType" SG_ 1506 TODCSR_ERSPrdDyReq "ENM";
BA_ "SignalLongName" SG_ 1506 TODCSR_ERSPrdDyReq "Time of Day Charging Setting Request : Electric Rate Schedule Period Day Request";
BA_ "SignalType" SG_ 1506 TODCSR_ERSCstSetReq "ENM";
BA_ "SignalLongName" SG_ 1506 TODCSR_ERSCstSetReq "Time of Day Charging Setting Request : Electric Rate Schedule Customization Setting Request";
BA_ "SignalLongName" SG_ 1506 TODCSR_ERSPrdMinOfHrReq "Time of Day Charging Setting Request : Electric Rate Schedule Period Minute of Hour Request";
BA_ "SignalType" SG_ 1506 TODCSR_ERSPrdLvlReq "ENM";
BA_ "SignalLongName" SG_ 1506 TODCSR_ERSPrdLvlReq "Time of Day Charging Setting Request : Electric Rate Schedule Period Level Request";
BA_ "SignalType" SG_ 1506 PrtblChrgCordLimCstSetReq "ENM";
BA_ "SignalLongName" SG_ 1506 PrtblChrgCordLimCstSetReq "Time of Day Charging Setting Request : Portable Charge Cord Limit Customization Setting Request";
BA_ "SignalType" SG_ 1506 TODCSR_ERSPrfReq "ENM";
BA_ "SignalLongName" SG_ 1506 TODCSR_ERSPrfReq "Time of Day Charging Setting Request : Electric Rate Schedule Preference Request";
BA_ "SignalType" SG_ 1506 TODCCbnPrcndtngSetReq "ENM";
BA_ "SignalLongName" SG_ 1506 TODCCbnPrcndtngSetReq "Time of Day Charging Setting Request : Time of Day Charging Cabin Preconditioning Setting Request";
BA_ "SignalType" SG_ 1506 TODCSR_LocNumReq "ENM";
BA_ "SignalLongName" SG_ 1506 TODCSR_LocNumReq "Time of Day Charging Setting Request : Location Number Request";
BA_ "SignalType" SG_ 1506 TODCSR_LocChrgPwrLvlReq "ENM";
BA_ "SignalLongName" SG_ 1506 TODCSR_LocChrgPwrLvlReq "Time of Day Charging Setting Request : Location Charging Power Level Request";
BA_ "SignalLongName" SG_ 1506 TODCSR_TgtChrgLvlReq "Time of Day Charging Setting Request : Target Charge Level Request";
BA_ "SignalLongName" SG_ 1521 ADASIS_NAVILINK_SpdLmtPsdSpd "ADASIS NAVILINK Speed Limit Posted Speed";
BA_ "SignalType" SG_ 1521 ADASIS_NAVILINK_SpdLmtPsdSpd_DuD "ENM";
BA_ "SignalLongName" SG_ 1521 ADASIS_NAVILINK_SpdLmtPsdSpd_DuD "ADASIS NAVILINK Speed Limit Posted Speed Don't Use Data";
BA_ "SignalLongName" SG_ 1521 ADASIS_NAVILINK_SpdLmtRcmdSpd "ADASIS NAVILINK Speed Limit Recommended Speed";
BA_ "SignalType" SG_ 1521 ADASIS_NAVILINK_DigMpVerYr "ENM";
BA_ "SignalLongName" SG_ 1521 ADASIS_NAVILINK_DigMpVerYr "ADASIS NAVILINK Digital Map Version Year";
BA_ "SignalType" SG_ 1521 ADASIS_NAVILINK_DigMpCndlSpdLmt "ENM";
BA_ "SignalLongName" SG_ 1521 ADASIS_NAVILINK_DigMpCndlSpdLmt "ADASIS NAVILINK Digital Map Conditional Speed Limit";
BA_ "SignalType" SG_ 1521 ADASIS_NAVILINK_DgtlMpSpdCtgry "ENM";
BA_ "SignalLongName" SG_ 1521 ADASIS_NAVILINK_DgtlMpSpdCtgry "ADASIS NAVILINK Digital Map Speed Category";
BA_ "SignalType" SG_ 1521 ADASIS_NAVILINK_DigMpVerQtr "ENM";
BA_ "SignalLongName" SG_ 1521 ADASIS_NAVILINK_DigMpVerQtr "ADASIS NAVILINK Digital Map Version Quarter";
BA_ "SignalType" SG_ 1521 ADASIS_NAVILINK_FncRdClss "ENM";
BA_ "SignalLongName" SG_ 1521 ADASIS_NAVILINK_FncRdClss "ADASIS NAVILINK Functional Road Class";
BA_ "SignalType" SG_ 1521 ADASIS_NAVILINK_DigMpEfSpdLmTyp "ENM";
BA_ "SignalLongName" SG_ 1521 ADASIS_NAVILINK_DigMpEfSpdLmTyp "ADASIS NAVILINK Digital Map Effective Speed Limit Type";
BA_ "SignalType" SG_ 1521 ADASIS_NAVILINK_SprtdLnRd "ENM";
BA_ "SignalLongName" SG_ 1521 ADASIS_NAVILINK_SprtdLnRd "ADASIS NAVILINK Separated Lane Road";
BA_ "SignalType" SG_ 1521 ADASIS_NAVILINK_SpdLmtUnt "ENM";
BA_ "SignalLongName" SG_ 1521 ADASIS_NAVILINK_SpdLmtUnt "ADASIS NAVILINK Speed Limit Unit";
BA_ "SignalType" SG_ 1521 ADASIS_NAVILINK_MpDtAv "ENM";
BA_ "SignalLongName" SG_ 1521 ADASIS_NAVILINK_MpDtAv "ADASIS NAVILINK Map data availability";
BA_ "SignalType" SG_ 1521 ADASIS_NAVILINK_DigMpPstSpdLmAs "ENM";
BA_ "SignalLongName" SG_ 1521 ADASIS_NAVILINK_DigMpPstSpdLmAs "ADASIS NAVILINK Digital Map Posted Speed Limit Assured";
BA_ "SignalType" SG_ 1521 ADASIS_NAVILINK_DigMpDrvngSd "ENM";
BA_ "SignalLongName" SG_ 1521 ADASIS_NAVILINK_DigMpDrvngSd "ADASIS NAVILINK Digital Map Driving Side";
BA_ "SignalType" SG_ 1521 ADASIS_NAVILINK_LnCtgry "ENM";
BA_ "SignalLongName" SG_ 1521 ADASIS_NAVILINK_LnCtgry "ADASIS NAVILINK Lane Category";
BA_ "SignalLongName" SG_ 1250 TrlrTirePresLFXferdSnsrID "Trailer Tire Pressure Left Front Transferred Sensor ID";
BA_ "SignalLongName" SG_ 1250 TrlrTirePresLRXferdSnsrID "Trailer Tire Pressure Left Rear Transferred Sensor ID";
BA_ "SignalLongName" SG_ 1816 TrlrTirePresRFXferdSnsrID "Trailer Tire Pressure Right Front Transferred Sensor ID";
BA_ "SignalLongName" SG_ 1816 TrlrTirePresRRXferdSnsrID "Trailer Tire Pressure Right Rear Transferred Sensor ID";
BA_ "SignalLongName" SG_ 1249 TrlrTirePresLtMdlXferdSnsrID "Trailer Tire Pressure Left Middle Transferred Sensor ID";
BA_ "SignalLongName" SG_ 1249 TrlrTirePresRtMdlXferdSnsrID "Trailer Tire Pressure Right Middle Transferred Sensor ID";
BA_ "SignalLongName" SG_ 1434 ReqTmpChgRRRr "Request Temperature Change Rear Right Rear";
BA_ "SignalLongName" SG_ 1434 ReqTmpChgRLRr "Request Temperature Change Rear Left Rear";
BA_ "SignalLongName" SG_ 1434 ReqTmpLvlRLRr "Request Temperature Level Rear Left Rear";
BA_ "SignalLongName" SG_ 1434 ReqTmpLvlRRRr "Request Temperature Level Rear Right Rear";
BA_ "SignalLongName" SG_ 1434 ReqBlwLvlChgRrRr "Request Blower Level Change Rear Rear";
BA_ "SignalType" SG_ 1434 ReqAirDstRRRr "ENM";
BA_ "SignalLongName" SG_ 1434 ReqAirDstRRRr "Request Air Distribution Rear Right Rear";
BA_ "SignalType" SG_ 1434 ReqAirDstRLRr "ENM";
BA_ "SignalLongName" SG_ 1434 ReqAirDstRLRr "Request Air Distribution Rear Left Rear";
BA_ "SignalType" SG_ 1434 HtdStBckCushStckSwLR "ENM";
BA_ "SignalLongName" SG_ 1434 HtdStBckCushStckSwLR "Heated Seat Back and Cushion Stuck Switch Left Rear";
BA_ "SignalType" SG_ 1434 RrAirHandlingDrActrPwrFdbk "ENM";
BA_ "SignalLongName" SG_ 1434 RrAirHandlingDrActrPwrFdbk "Rear Air Handling Door Actuator Power Feedback";
BA_ "SignalLongName" SG_ 1434 ReqBlwLvlRrRr "Request Blower Level Rear Rear";
BA_ "SignalType" SG_ 1434 ReqBlwLvlRrAtvRr "ENM";
BA_ "SignalLongName" SG_ 1434 ReqBlwLvlRrAtvRr "Request Blower Level Rear Active Rear";
BA_ "SignalType" SG_ 1434 ReqAirDstChgNxtRRRr "ENM";
BA_ "SignalLongName" SG_ 1434 ReqAirDstChgNxtRRRr "Request Air Distribution Change Next Rear Right Rear";
BA_ "SignalType" SG_ 1434 ReqAirDstChgNxtRLRr "ENM";
BA_ "SignalLongName" SG_ 1434 ReqAirDstChgNxtRLRr "Request Air Distribution Change Next Rear Left Rear";
BA_ "SignalType" SG_ 1434 HtdVntStSwActvRR "ENM";
BA_ "SignalLongName" SG_ 1434 HtdVntStSwActvRR "Heated Vented Seat Switch Active Right Rear";
BA_ "SignalType" SG_ 1434 HtdVntStSwActvLR "ENM";
BA_ "SignalLongName" SG_ 1434 HtdVntStSwActvLR "Heated Vented Seat Switch Active Left Rear";
BA_ "SignalType" SG_ 1434 HtdStBckStckSwRR "ENM";
BA_ "SignalLongName" SG_ 1434 HtdStBckStckSwRR "Heated Seat Back Stuck Switch Right Rear";
BA_ "SignalType" SG_ 1434 HtdStBckStckSwLR "ENM";
BA_ "SignalLongName" SG_ 1434 HtdStBckStckSwLR "Heated Seat Back Stuck Switch Left Rear";
BA_ "SignalType" SG_ 1434 HtdStBckCushStckSwRR "ENM";
BA_ "SignalLongName" SG_ 1434 HtdStBckCushStckSwRR "Heated Seat Back and Cushion Stuck Switch Right Rear";
BA_ "SignalType" SG_ 1434 VntStStckSwRR "ENM";
BA_ "SignalLongName" SG_ 1434 VntStStckSwRR "Vented Seat Stuck Switch Right Rear";
BA_ "SignalType" SG_ 1434 VntStStckSwLR "ENM";
BA_ "SignalLongName" SG_ 1434 VntStStckSwLR "Vented Seat Stuck Switch Left Rear";
BA_ "SignalType" SG_ 1434 RrHVACCtrlInitFin "ENM";
BA_ "SignalLongName" SG_ 1434 RrHVACCtrlInitFin "Rear HVAC Control Initialization Finished";
BA_ "SignalType" SG_ 1434 ReqTmpLvlRRAtvRr "ENM";
BA_ "SignalLongName" SG_ 1434 ReqTmpLvlRRAtvRr "Request Temperature Level Rear Right Active Rear";
BA_ "SignalType" SG_ 1434 ReqTmpLvlRLAtvRr "ENM";
BA_ "SignalLongName" SG_ 1434 ReqTmpLvlRLAtvRr "Request Temperature Level Rear Left Active Rear";
BA_ "SignalType" SG_ 1434 ReqSYNC_RrChgRr "ENM";
BA_ "SignalLongName" SG_ 1434 ReqSYNC_RrChgRr "Request SYNC Rear Change Rear";
BA_ "SignalType" SG_ 1434 ReqRrHVAC_PwrChgRr "ENM";
BA_ "SignalLongName" SG_ 1434 ReqRrHVAC_PwrChgRr "Request Rear HVAC Power Change Rear";
BA_ "SignalType" SG_ 1434 ReqRrAutoRr "ENM";
BA_ "SignalLongName" SG_ 1434 ReqRrAutoRr "Request Rear Auto Rear";
BA_ "SignalType" SG_ 1430 HVACFCRADR_RtSet "ENM";
BA_ "SignalLongName" SG_ 1430 HVACFCRADR_RtSet "DEPRECATED VIP 25 - HVAC Front Controls Request Air Distribution Rear : Right Setting";
BA_ "SignalType" SG_ 1430 HVACFCRADR_RtChgNext "ENM";
BA_ "SignalLongName" SG_ 1430 HVACFCRADR_RtChgNext "DEPRECATED VIP 25 - HVAC Front Controls Request Air Distribution Rear : Right Change Next";
BA_ "SignalType" SG_ 1430 HVACFCRADR_LtSet "ENM";
BA_ "SignalLongName" SG_ 1430 HVACFCRADR_LtSet "DEPRECATED VIP 25 - HVAC Front Controls Request Air Distribution Rear : Left Setting";
BA_ "SignalType" SG_ 1430 HVACFCRADR_LtChgNext "ENM";
BA_ "SignalLongName" SG_ 1430 HVACFCRADR_LtChgNext "DEPRECATED VIP 25 - HVAC Front Controls Request Air Distribution Rear : Left Change Next";
BA_ "SignalLongName" SG_ 1430 HVACFCRADR_RwVltg1 "DEPRECATED VIP 25 - HVAC Front Controls Request Air Distribution Rear : Raw Voltage 1";
BA_ "SignalLongName" SG_ 1430 HVACFCRADR_RwVltg2 "DEPRECATED VIP 25 - HVAC Front Controls Request Air Distribution Rear : Raw Voltage 2";
BA_ "SignalLongName" SG_ 1430 HVACFCRACH_CompSetRwVltg "HVAC Front Controls Request AC and Heat : Compressor Setting Raw Voltage";
BA_ "SignalType" SG_ 1430 HVACFCRACH_CompSetChg "ENM";
BA_ "SignalLongName" SG_ 1430 HVACFCRACH_CompSetChg "HVAC Front Controls Request AC and Heat : Compressor Setting Change";
BA_ "SignalLongName" SG_ 1430 HVACFCRACH_ARC "HVAC Front Controls Request AC and Heat : Alive Rolling Count";
BA_ "SignalLongName" SG_ 1430 HVACFCRACH_HtrSetRwVltg "HVAC Front Controls Request AC and Heat : Heater Setting Raw Voltage";
BA_ "SignalType" SG_ 1430 HVACFCRACH_HtrSetChg "ENM";
BA_ "SignalLongName" SG_ 1430 HVACFCRACH_HtrSetChg "HVAC Front Controls Request AC and Heat : Heater Setting Change";
BA_ "SignalLongName" SG_ 1430 HVACFCRRA_RwVltg "DEPRECATED VIP 25 - HVAC Front Controls Request Rear Auto : Raw Voltage";
BA_ "SignalType" SG_ 1430 HtdStBckCushStckSwRF "ENM";
BA_ "SignalLongName" SG_ 1430 HtdStBckCushStckSwRF "Heated Seat Back and Cushion Stuck Switch Right Front";
BA_ "SignalType" SG_ 1430 HtdStBckCushStckSwLF "ENM";
BA_ "SignalLongName" SG_ 1430 HtdStBckCushStckSwLF "Heated Seat Back and Cushion Stuck Switch Left Front";
BA_ "SignalType" SG_ 1430 HVACFCRRA_SetChg "ENM";
BA_ "SignalLongName" SG_ 1430 HVACFCRRA_SetChg "DEPRECATED VIP 25 - HVAC Front Controls Request Rear Auto : Setting Change";
BA_ "SignalLongName" SG_ 1431 HVACFCRBLR_LvlChg "DEPRECATED VIP 25 - HVAC Front Controls Request Blower Level Rear : Level Change";
BA_ "SignalType" SG_ 1431 HVACFCRBLR_LvlActv "ENM";
BA_ "SignalLongName" SG_ 1431 HVACFCRBLR_LvlActv "DEPRECATED VIP 25 - HVAC Front Controls Request Blower Level Rear : Level Active";
BA_ "SignalLongName" SG_ 1431 HVACFCRBLR_Lvl "DEPRECATED VIP 25 - HVAC Front Controls Request Blower Level Rear : Level";
BA_ "SignalLongName" SG_ 1431 HVACFCRBLR_RwVltg1 "DEPRECATED VIP 25 - HVAC Front Controls Request Blower Level Rear : Raw Voltage 1";
BA_ "SignalLongName" SG_ 1431 HVACFCRBLR_RwVltg2 "DEPRECATED VIP 25 - HVAC Front Controls Request Blower Level Rear : Raw Voltage 2";
BA_ "SignalLongName" SG_ 1431 HVACFCRRD_RwVltg "HVAC Front Controls Request Rear Defog : Raw Voltage";
BA_ "SignalLongName" SG_ 1431 HVACFCRRP_RwVltg "DEPRECATED VIP 25 - HVAC Front Controls Request Rear Power : Raw Voltage";
BA_ "SignalType" SG_ 1431 HVACFCRRD_SetChg "ENM";
BA_ "SignalLongName" SG_ 1431 HVACFCRRD_SetChg "HVAC Front Controls Request Rear Defog : Setting Change";
BA_ "SignalType" SG_ 1431 HVACFCRRP_SetChg "ENM";
BA_ "SignalLongName" SG_ 1431 HVACFCRRP_SetChg "DEPRECATED VIP 25 - HVAC Front Controls Request Rear Power : Setting Change";
BA_ "SignalLongName" SG_ 1431 HVACFCRSA_RwVltg "HVAC Front Controls Request Sync All : Raw Voltage";
BA_ "SignalType" SG_ 1431 VntStStckSwLF "ENM";
BA_ "SignalLongName" SG_ 1431 VntStStckSwLF "Vented Seat Stuck Switch Left Front";
BA_ "SignalType" SG_ 1431 HtdVntStSwActvRF "ENM";
BA_ "SignalLongName" SG_ 1431 HtdVntStSwActvRF "Heated Vented Seat Switch Active Right Front";
BA_ "SignalType" SG_ 1431 HtdVntStSwActvLF "ENM";
BA_ "SignalLongName" SG_ 1431 HtdVntStSwActvLF "Heated Vented Seat Switch Active Left Front";
BA_ "SignalType" SG_ 1431 HtdStBckStckSwRF "ENM";
BA_ "SignalLongName" SG_ 1431 HtdStBckStckSwRF "Heated Seat Back Stuck Switch Right Front";
BA_ "SignalType" SG_ 1431 HtdStBckStckSwLF "ENM";
BA_ "SignalLongName" SG_ 1431 HtdStBckStckSwLF "Heated Seat Back Stuck Switch Left Front";
BA_ "SignalType" SG_ 1431 HVACFrtCtlReqSyncRrSetChg "ENM";
BA_ "SignalLongName" SG_ 1431 HVACFrtCtlReqSyncRrSetChg "DEPRECATED VIP 25 - HVAC Front Controls Request Sync Rear Setting Change";
BA_ "SignalType" SG_ 1431 HVACFCRSA_SetChg "ENM";
BA_ "SignalLongName" SG_ 1431 HVACFCRSA_SetChg "HVAC Front Controls Request Sync All : Setting Change";
VAL_ 1515 TAC_AudConctOutcm 0 "NO_ACTION" 1 "REQUEST_GRANTED" 2 "REQUEST_DENIED" 3 "AUDIO_FAULT" 4 "RESERVED_2" 5 "RESERVED_3" 6 "RESERVED_4" 7 "RESERVED_5" 8 "RESERVED_6" 9 "RESERVED_7" 10 "RESERVED_8" 11 "RESERVED_9" 12 "RESERVED_10" 13 "RESERVED_11" 14 "RESERVED_12" 15 "RESERVED_13" ;
VAL_ 1515 TAC_AudChConctStat 0 "NO_ACTION" 1 "MIX_PROMPT" 2 "MUTEX_PROMPT" 3 "RING_TONE" 4 "PHONE" 5 "EMERGENCY_PHONE" 6 "RESERVED_1" 7 "RESERVED_2" 8 "RESERVED_3" 9 "RESERVED_4" 10 "RESERVED_5" 11 "RESERVED_6" 12 "RESERVED_7" 13 "RESERVED_8" 14 "RESERVED_9" 15 "RESERVED_10" ;
VAL_ 1515 TDOSWCCSR_ChgSetReq 0 "NO_ACTION" 1 "OFF" 2 "ON" 3 "RESERVED_3" 4 "RESERVED_4" 5 "RESERVED_5" 6 "RESERVED_6" 7 "RESERVED_7" ;
VAL_ 1515 InfoSysStat 0 "Sleep" 1 "AnimationInit" 2 "HMI_Init" 3 "HMI_Inactive" 4 "Start" 5 "Run" 6 "Propulsion" 7 "Accessory" 8 "LocalInfotainment" 9 "LocalPhone" 10 "LocalValet" 11 "LocalEject" 12 "ValetMode" 13 "TheftLocked" 14 "NoCalibration" 15 "NoVIN" 16 "RemoteReflashProgramming" 17 "OffMode" 18 "VirtualSwitchDisplay" 19 "NoInVehicleInfotainment" ;
VAL_ 1515 AutoMemRclCstChgSetReq 0 "NO_ACTION" 1 "OFF" 2 "ON" 3 "AUTO_MEMORY_RECALL" 4 "EASY_EXIT" 5 "AUTO_MEMORY_AND_EASY_EXIT_RECALLS" 6 "RESERVED6" 7 "RESERVED7" ;
VAL_ 1515 AdpLghtRspTypCstChgSetReq 0 "NO_ACTION" 1 "OFF" 2 "CORNER_AND_CURVE_LIGHTING" 3 "INTELLIGENT_LIGHT_DISTRIBUTION" 4 "INTELLIGENT_LIGHT_DISTRIBUTION_GPS_ASSISTANCE" 5 "RESERVED_5" 6 "RESERVED_6" 7 "RESERVED_7" ;
VAL_ 1515 TDOSWCCSR_IncSwAct 0 "FALSE" 1 "TRUE" ;
VAL_ 1515 TDOSWCCSR_DecSwAct 0 "FALSE" 1 "TRUE" ;
VAL_ 1515 EsyExtCstChgSetReq 0 "NO_ACTION" 1 "OFF" 2 "ON" 3 "RESERVED_3" 4 "RESERVED_4" 5 "RESERVED_5" 6 "RESERVED_6" 7 "RESERVED_7" ;
VAL_ 1515 DrvrAlrtTypCstChgStReq 0 "SETTING_UNKNOWN" 1 "CHIME" 2 "SEAT" 3 "RESERVED_3" 4 "RESERVED_4" 5 "RESERVED_5" 6 "RESERVED_6" 7 "RESERVED_7" ;
VAL_ 1515 CrgBedVwAutoLgtCstChgSetReq 0 "No_Action" 1 "Off" 2 "On" ;
VAL_ 1515 FrwdImpMtgnOpSlctCstChgSetReq 0 "NO_ACTION" 1 "OFF" 2 "ALERT" 3 "ALERT_BRAKE" 4 "ALERT_BRAKE_STEER" 5 "RESERVED_5" 6 "RESERVED_6" 7 "RESERVED_7" ;
VAL_ 1515 FrtRdHgtGPSCstChngSetReq 0 "NO_ACTION" 1 "OFF" 2 "ON" 3 "RESERVED_3" 4 "RESERVED_4" 5 "RESERVED_5" 6 "RESERVED_6" 7 "RESERVED_7" ;
VAL_ 1515 FrntPCMRspTypCstChgSetReq 0 "NO_ACTION" 1 "OFF" 2 "ALERT" 3 "ALERT_AND_BRAKE" 4 "ALERT_AND_BRAKE_AND_STEER" 5 "RESERVED_5" 6 "RESERVED_6" 7 "RESERVED_7" ;
VAL_ 1515 GoNotfrCstChgSetReq 0 "NO_ACTION" 1 "OFF" 2 "ON" 3 "RESERVED_3" 4 "RESERVED_4" 5 "RESERVED_5" 6 "RESERVED_6" 7 "RESERVED_7" ;
VAL_ 1515 GlrFrHgBmRspTypCstChgSetReq 0 "NO_ACTION" 1 "AUTOMATIC_HIGH_BEAM" 2 "GLARE_FREE_HIGH_BEAM" 3 "RESERVED_3" 4 "RESERVED_4" 5 "RESERVED_5" 6 "RESERVED_6" 7 "RESERVED_7" ;
VAL_ 1515 PhnLtInVehCstChgSetReq 0 "NO_ACTION" 1 "OFF" 2 "ON" 3 "RESERVED_3" 4 "RESERVED_4" 5 "RESERVED_5" 6 "RESERVED_6" 7 "RESERVED_7" ;
VAL_ 1515 LtRtHnTrCstChgSetReq 0 "NO_ACTION" 1 "LEFT_HAND_DRIVE" 2 "RIGHT_HAND_DRIVE" 3 "AUTOMATIC_WITH_GPS" 4 "RESERVED_4" 5 "RESERVED_5" 6 "RESERVED_6" 7 "RESERVED_7" ;
VAL_ 1515 JckKnfDtnCstChgSetReq 0 "No_Action" 1 "Off" 2 "On" ;
VAL_ 1515 APACrssBckInSftBtnStat 0 "NOT_PRESSED" 1 "PRESSED" ;
VAL_ 1515 PrkAsstTrHtchPsntCstChgSetReq 0 "NO_ACTION" 1 "OFF_NOT_ATTACHED" 2 "ON_ATTACHED" 3 "RESERVED_3" 4 "RESERVED_4" 5 "RESERVED_5" 6 "RESERVED_6" 7 "RESERVED_7" ;
VAL_ 1515 PrkAsstOnOffCstChgSetReq 0 "No_Action" 1 "Off" 2 "Alert" 3 "Alert_Brake" ;
VAL_ 1516 RrCrsTrfcAlrtCstChngSetReq 0 "NO_ACTION" 1 "OFF" 2 "ALERT" 3 "ALERT AND BRAKE" 4 "RESERVED_4" 5 "RESERVED_5" 6 "RESERVED_6" 7 "RESERVED_7" ;
VAL_ 1516 RnngBrdManDplyCstChgSetReq 0 "NO_ACTION" 1 "OFF" 2 "EXTEND_DOOR" 3 "EXTEND_BED" 4 "RESERVED_4 RESERVED_5" 5 "RESERVED_6" 6 "RESERVED_7" ;
VAL_ 1516 RnngBrdAutoDplyCstChgSetReq 0 "NO_ACTION" 1 "OFF" 2 "DOOR" 3 "DOOR_PARK" 4 "RESERVED_4 RESERVED_5" 5 "RESERVED_6" 6 "RESERVED_7" ;
VAL_ 1516 SBZAlrtCstChngSetReq 0 "NO_ACTION" 1 "OFF" 2 "ON" 3 "RESERVED_3" 4 "RESERVED_4" 5 "RESERVED_5" 6 "RESERVED_6" 7 "RESERVED_7" ;
VAL_ 1516 RrVwPrkAstSymCstChgSetReq 0 "NO_ACTION" 1 "OFF" 2 "ON" 3 "RESERVED_3" 4 "RESERVED_4" 5 "RESERVED_5" 6 "RESERVED_6" 7 "RESERVED_7" ;
VAL_ 1516 RrPCMRspTypCstChgSetReq 0 "NO_ACTION" 1 "OFF" 2 "ALERT" 3 "ALERT_AND_BRAKE" 4 "ALERT_AND_BRAKE_AND_STEER" 5 "RESERVED_5" 6 "RESERVED_6" 7 "RESERVED_7" ;
VAL_ 1516 SrrndVwLghtCstChgSetReq 0 "SETTING_UNKNOWN" 1 "ON" 2 "OFF" 3 "RESERVED_3" 4 "RESERVED_4" 5 "RESERVED_5" 6 "RESERVED_6" 7 "RESERVED_7" ;
VAL_ 1516 SelUlkCstChgSetReq 0 "NO_ACTION" 1 "DRIVER_DOOR_ONLY" 2 "ALL_DOORS" 3 "RESERVED_3" 4 "RESERVED_4" 5 "RESERVED_5" 6 "RESERVED_6" 7 "RESERVED_7" ;
VAL_ 1516 TnDrvSpdLmtCstChgStReq 0 "NO_ACTION" 1 "OFF" 2 "ON" 3 "RESERVED_3" 4 "RESERVED_4" 5 "RESERVED_5" 6 "RESERVED_6" 7 "RESERVED_7" ;
VAL_ 1516 StBltTghtngCstChgSetReq 0 "NO_ACTION" 1 "OFF" 2 "ON" 3 "RESERVED_3" 4 "RESERVED_4" 5 "RESERVED_5" 6 "RESERVED_6" 7 "RESERVED_7" ;
VAL_ 1516 StBltShfIntlkCstChgSetReq 0 "NO ACTION" 1 "OFF" 2 "ON" 3 "RESERVED 3" 4 "RESERVED 4" 5 "RESERVED 5" 6 "RESERVED 6" 7 "RESERVED 7" ;
VAL_ 1516 TrlrMirVidEnblCstChgSetReq 0 "No_Action" 1 "Off" 2 "On" ;
VAL_ 1516 TrffcLgtAsstCstChgSetReq 0 "NO_ACTION" 1 "OFF" 2 "ALERT" 3 "RESERVED_3" 4 "RESERVED_4" 5 "RESERVED_5" 6 "RESERVED_6" 7 "RESERVED_7" ;
VAL_ 1516 TnDrvStBltShfIntlkCstChgSetReq 0 "NO_ACTION" 1 "OFF" 2 "ON" 3 "RESERVED_3" 4 "RESERVED_4" 5 "RESERVED_5" 6 "RESERVED_6" 7 "RESERVED_7" ;
VAL_ 1516 VehLctrLtsCstChgSetReq 0 "NO_ACTION" 1 "OFF" 2 "ON" 3 "On Without Animation" 4 "RESERVED_4" 5 "RESERVED_5" 6 "RESERVED_6" 7 "RESERVED_7" ;
VAL_ 1516 TrlrMirVidGdlnsCstChgSetReq 0 "No_Action" 1 "Off" 2 "On" ;
VAL_ 1516 APALftSftBtnStat 0 "NOT_PRESSED" 1 "PRESSED" ;
VAL_ 1516 APAFcStatCSM 0 "NO_FOCUS" 1 "FOCUS" ;
VAL_ 1516 APAExtPrkSftBtnStat 0 "NOT_PRESSED" 1 "PRESSED" ;
VAL_ 1516 ElvtdIdlCstChgSetReq 0 "No Action" 1 "Off" 2 "On" ;
VAL_ 1516 WlkAwyLckCstChgSetReq 0 "NO_ACTION" 1 "OFF" 2 "ON" 3 "ON_WITH_CHIRP" 4 "RESERVED_4" 5 "RESERVED_5" 6 "RESERVED_6" 7 "RESERVED_7" ;
VAL_ 1516 TimeDispFormat 0 "12 Hour Mode" 1 "24 Hour Mode" ;
VAL_ 1516 RstrCstDfltReq 0 "FALSE" 1 "TRUE" ;
VAL_ 1516 RFStStsDispActv 0 "FALSE" 1 "TRUE" ;
VAL_ 1516 LFStStsDispActv 0 "FALSE" 1 "TRUE" ;
VAL_ 1516 APASrchSftBtnStat 0 "NOT_PRESSED" 1 "PRESSED" ;
VAL_ 1516 APARghtSftBtnStat 0 "NOT_PRESSED" 1 "PRESSED" ;
VAL_ 1516 APAPrllPrkSftBtnStat 0 "NOT_PRESSED" 1 "PRESSED" ;
VAL_ 1813 ValetMdReq 0 "NoAction" 1 "SetPIN" 2 "ClearPIN" ;
VAL_ 1813 TeenDrvReq 0 "No Action" 1 "Verify Teen PIN" 2 "Update Teen PIN" 3 "Set Teen Key" 4 "Clear Teen Key" 5 "Check for Teen Key" 6 "Clear Teen Keys and PIN" 7 "Reset Report Card" 8 "Request Report Card Data" ;
VAL_ 1813 LngSelExt 0 "NA English" 1 "German" 2 "Italian" 3 "Swedish" 4 "French" 5 "Spanish" 6 "Dutch" 7 "Portuguese" 8 "Norwegian" 9 "Finnish" 10 "Danish" 11 "Greek" 12 "Japanese" 13 "Arabic" 14 "Standard Chinese" 15 "Polish" 16 "Turkish" 17 "Korean" 18 "Traditional Chinese" 19 "UK English" 20 "Hungarian" 21 "Czech" 22 "Slovak" 23 "Russian" 24 "Brazilian Portuguese" 25 "Thai" 26 "Bulgarian" 27 "Romanian" 28 "Slovenian" 29 "Croatian" 30 "Ukrainian" 31 "NA French" 32 "NA Spanish" 33 "Cantonese" 34 "Uzbek" 35 "Serbian" 36 "Lithuanian" 37 "Estonian" 38 "Latvian" 39 "Macedonian" 40 "AU English" 41 "ZA English" 42 "Hebrew" 43 "LA Spanish" ;
VAL_ 1813 PTOEngRunTmrCstSetReq 0 "No Action" 1 "Min 10" 2 "Min 30" 3 "Min 90" 4 "Min 120" 5 "Min 150" 6 "Min 180" 7 "Min 210" 8 "Min 240" 9 "Min 270" 10 "Min 200" 11 "Min 330" 12 "Min 360" 13 "Min 390" 14 "Min 420" 15 "Min 450" ;
VAL_ 1813 PTOEngSpdTypCstSetReq 0 "No Action" 1 "Preset" 2 "Variable" ;
VAL_ 1813 PTOSet1SpdCstSetReq 0 "No Action" 1 "RPM 1100" 2 "RPM 1200" 3 "RPM 1300" 4 "RPM 1400" 5 "RPM 1500" 6 "RPM 1600" 7 "RPM 1700" 8 "RPM 1800" 9 "RPM 1900" 10 "RPM 2000" 11 "RPM 2100" 12 "RPM 2200" 13 "RPM 2300" 14 "RPM 2400" 15 "RPM 2500" ;
VAL_ 1252 PTOStndbySpdCstSetReq 0 "No Action" 1 "RPM 900" 2 "RPM 1000" 3 "RPM 1100" 4 "RPM 1200" 5 "RPM 1300" 6 "RPM 1400" 7 "RPM 1500" ;
VAL_ 1252 LnChgAlrtCstChngSetReq 0 "NO_ACTION" 1 "OFF" 2 "ON" 3 "RESERVED_3" 4 "RESERVED_4" 5 "RESERVED_5" 6 "RESERVED_6" 7 "RESERVED_7" ;
VAL_ 1252 PTOSet2SpdCstSetReq 0 "No Action" 1 "RPM 1700" 2 "RPM 1800" 3 "RPM 1900" 4 "RPM 2000" 5 "RPM 2100" 6 "RPM 2200" 7 "RPM 2300" 8 "RPM 2400" 9 "RPM 2500" 10 "RPM 2600" 11 "RPM 2700" 12 "RPM 2800" 13 "RPM 2900" 14 "RPM 3000" 15 "RPM 3100" ;
VAL_ 1252 TCP_LCMFileTrans 0 "No Action" 1 "Begin Transfer" 2 "Successful Block Transfer" 3 "Cancel Transfer" 4 "Retry Last Block" ;
VAL_ 1252 PTOTpStpSpdCstSetReq 0 "No Action" 1 "RPM 5" 2 "RPM 10" 3 "RPM 25" 4 "RPM 50" 5 "RPM 100" 6 "RPM 250" 7 "RPM 500" ;
VAL_ 1252 TCP_LCMDataMsgStat 0 "No Action" 1 "Acknowledge" ;
VAL_ 1252 CamVidICS_DispAct 0 "FALSE" 1 "TRUE" ;
VAL_ 1252 TrlrLtngSeqReq 0 "No Action" 1 "Off" 2 "On" ;
VAL_ 1252 PTOModeCstSetReq 0 "No Action" 1 "Standard" 2 "Remote" ;
VAL_ 1252 VwgVwprtTopDnVwSeltn 0 "Unknown" 1 "No Request" 2 "Top Down View" ;
VAL_ 1252 VwgVwprtZoomBtnSeltd 0 "FALSE" 1 "TRUE" ;
VAL_ 1252 VwgVwprtNtfnFcsReqd 0 "FALSE" 1 "TRUE" ;
VAL_ 1252 VwgVwprtNtfnDsmsReqd 0 "FALSE" 1 "TRUE" ;
VAL_ 1252 TrfcJamAsstVirtCtlReq 0 "No Action" 1 "Off" 2 "On" ;
VAL_ 1252 DrvrSeltdSpdLmtrVirtCtlReqd 0 "FALSE" 1 "TRUE" ;
VAL_ 1252 DrvrSeltdSpdLmtrVirtCtlReq 0 "No Action" 1 "Manual" 2 "Auto" 3 "Off" ;
VAL_ 1252 DMBlkhdDrAutoClsTmCstChgSetReq 0 "No Action" 1 "Standard" 2 "Extended" 3 "Keep Open" ;
VAL_ 1239 MFC_LCMFileTrans 0 "No Action" 1 "Begin Transfer" 2 "Successful Block Transfer" 3 "Cancel Transfer" 4 "Retry Last Block" ;
VAL_ 1239 MFC_LCMDataMsgStat 0 "No Action" 1 "Acknowledge" ;
VAL_ 1239 BklghtngCnfg 0 "Off" 1 "On" 2 "Local" ;
VAL_ 706 WCM_LCMDataMsgStat 0 "No Action" 1 "Acknowledge" ;
VAL_ 706 WCM_LCMFileTrans 0 "No Action" 1 "Begin Transfer" 2 "Successful Block Transfer" 3 "Cancel Transfer" 4 "Retry Last Block" ;
VAL_ 1425 ASSLC_AutoLdnsCmpnAct 0 "FALSE" 1 "TRUE" ;
VAL_ 1425 ASSLC_VcSrcActOnMtx 0 "FALSE" 1 "TRUE" ;
VAL_ 1426 ZALC_LRMtxSnkMut 0 "FALSE" 1 "TRUE" ;
VAL_ 1426 ZALC_MltZnMixPrmtAudRR 0 "FALSE" 1 "TRUE" ;
VAL_ 1426 ZALC_MltZnMixPrmtAudPsngrFrt 0 "FALSE" 1 "TRUE" ;
VAL_ 1426 ZALC_MltZnMixPrmtAudLR 0 "FALSE" 1 "TRUE" ;
VAL_ 1426 ZALC_MltZnMixPrmtAudDrvrFrt 0 "FALSE" 1 "TRUE" ;
VAL_ 1426 ZALC_MltZnAudFtrStat 0 "Unknown" 1 "Single Zone Audio" 2 "Dual Zone Audio" 3 "Quad Zone Audio" ;
VAL_ 1426 ZALC_PsngrFrtMtxSnkMut 0 "FALSE" 1 "TRUE" ;
VAL_ 1426 ZALC_RRMtxSnkMut 0 "FALSE" 1 "TRUE" ;
VAL_ 1426 FrtCntrStckOptDskDrvDckStat 0 "DS_EMPTY" 1 "DS_LOADING" 2 "DS_READY" 3 "DS_EJECT" 4 "DS_READ_FORMAT_ERROR" 5 "DS_STAT_5" 6 "DS_STAT_6" 7 "DS_STAT_7" ;
VAL_ 1426 ZALC_VcSrcActvOnRRMtx 0 "FALSE" 1 "TRUE" ;
VAL_ 1426 ZALC_VcSrcActvOnPsngrFrtMtx 0 "FALSE" 1 "TRUE" ;
VAL_ 1426 ZALC_VcSrcActvOnLRMtx 0 "FALSE" 1 "TRUE" ;
VAL_ 1427 ASTC_AmpLwPwrSt 0 "FALSE" 1 "TRUE" ;
VAL_ 1427 ASTC_DSPMd 0 "NO_ACTION" 1 "DSP_MODE_0" 2 "DSP_MODE_1" 3 "DSP_MODE_2" 4 "DSP_MODE_3" 5 "DSP_MODE_4" 6 "DSP_MODE_5" 7 "DSP_MODE_6" 8 "DSP_MODE_7" 9 "RESERVED_1" 10 "RESERVED_2" 11 "RESERVED_3" 12 "RESERVED_4" 13 "RESERVED_5" 14 "RESERVED_6" 15 "RESERVED_7" ;
VAL_ 1427 ASTC_ChimSnkSpkrPos 0 "NO_ACTION" 1 "FULL_FRONT" 2 "FULL_REAR" 3 "FULL_LEFT" 4 "FULL_RIGHT" 5 "RIGHT_FRONT" 6 "RIGHT_REAR" 7 "LEFT_FRONT" 8 "LEFT_REAR" 9 "RESERVED_1" 10 "RESERVED_2" 11 "RESERVED_3" 12 "RESERVED_4" 13 "RESERVED_5" 14 "RESERVED_6" 15 "RESERVED_7" ;
VAL_ 1427 ASTC_GblAudSnkMut 0 "FALSE" 1 "TRUE" ;
VAL_ 1427 ASTC_MtxSnkMut 0 "FALSE" 1 "TRUE" ;
VAL_ 1427 FrtCntrStckHptcFdbkReq 0 "NO_ACTION" 1 "TAP" 2 "LONG_PRESS" 3 "PRESS_&_HOLD_SCROLL" 4 "PRESS_&_HOLD_END" 5 "RESERVED_05" 6 "RESERVED_06" 7 "RESERVED_07" 8 "RESERVED_08" 9 "RESERVED_09" 10 "RESERVED_10" 11 "RESERVED_11" 12 "RESERVED_12" 13 "RESERVED_13" 14 "RESERVED_14" 15 "RESERVED_15" ;
VAL_ 1427 ASTC_VehNoisCmpnAct 0 "FALSE" 1 "TRUE" ;
VAL_ 1519 ADASIS_NAVILINK_DgtlMpEfSpdLm 0 "UNKNOWN" 1 "<= 5 KM/H [MPH]" 2 "7 KM/H [MPH]" 3 "10 KM/H [MPH]" 4 "15 KM/H [MPH]" 5 "20 KM/H [MPH]" 6 "25 KM/H [MPH]" 7 "30 KM/H [MPH]" 8 "35 KM/H [MPH]" 9 "40 KM/H [MPH]" 10 "45 KM/H [MPH]" 11 "50 KM/H [MPH]" 12 "55 KM/H [MPH]" 13 "60 KM/H" 14 "MPH]65 KM/H [MPH]" 15 "70 KM/H [MPH]" 16 "75 KM/H [MPH]" 17 "80 KM/H [MPH]" 18 "85 KM/H [MPH]" 19 "90 KM/H [MPH]" 20 "95 KM/H [MPH]" 21 "100 KM/H [MPH]" 22 "105 KM/H [MPH]" 23 "110 KM/H [MPH]" 24 "115 KM/H [MPH]" 25 "120 KM/H[MPH]" 26 "130 KM/H [MPH]" 27 "140 KM/H [MPH]" 28 "150 KM/H [MPH]" 29 "160 KM/H [MPH]" 30 "UNLIMITED" 31 "NOT AVAILABLE" ;
VAL_ 1519 ADASIS_NAVILINK_CntryCd 0 "AD" 1 "AT" 2 "BE" 3 "CZ" 4 "DK" 5 "EE" 6 "FR" 7 "DE" 8 "GR" 9 "HU" 10 "IE" 11 "IT" 12 "BY" 13 "BG" 14 "CY" 15 "MT" 16 "HR" 17 "TR" 18 "RS" 19 "ME" 20 "LV" 21 "LT" 22 "LU" 23 "NL" 24 "NO" 25 "PL" 26 "PT" 27 "UK" 28 "SK" 29 "SI" 30 "ES" 31 "SE" 32 "CH" 33 "RO" 34 "RU" 35 "UA" 36 "BA" 37 "AL" 38 "MD" 39 "IS" 40 "MK" 41 "US" 42 "ZA" 43 "AU" 44 "NZ" 45 "KR" 46 "CN" 47 "CA" 48 "MX" 49 "FI" 50 "OTHER" 51 "UNKNOWN" ;
VAL_ 1519 VwgVwprtSeltn 0 "Unknown" 1 "Front Perspective" 2 "Front Junction" 3 "Front Overhead" 4 "Side Forward" 5 "Rear Perspective" 6 "Rear Junction" 7 "Rear Overhead" 8 "Side Rearward" 9 "Bowl" 10 "Zoomed Bowl" 11 "Japan" 12 "Rear Hitch" 13 "Bed Hitch" 14 "Trailer Aux1" 15 "Trailer Towing Mirror" 16 "L R Trailer Towing Mirror" 17 "Trailer Aux1 Combined" 18 "Trailer Aux2" 19 "Invisible Trailer" 20 "Cargo Bed" 21 "Curb Overhead" 22 "Curb" 23 "No Request" 24 "Transparent Hood" ;
VAL_ 1519 SrrndVsnRcrdrListFcs 0 "Unknown" 1 "File_1" 2 "File_2" 3 "File_3" 4 "File_4" 5 "File_5" 6 "Delete_1" 7 "Delete_2" 8 "Delete_3" 9 "Delete_4" 10 "Delete_5" 11 "No Focus" ;
VAL_ 1519 ADASIS_NAVILINK_DgtlMpPsngRst 0 "NO PASSING RESTRICTIONS" 1 "GENERAL NO OVERTAKE" 2 "FLUCTUATING (E.G. LED SIGNS)" 3 "CONDITIONAL PASSENGER CAR WITH TRAILER" 4 "CONDITIONAL TRACTORS ARE ALLOWED TO OVERTAKE" 5 "CONDITIONAL WHEN WET" 6 "CONDITIONAL WHEN SNOW" 7 "UNKNOWN CONDITION" ;
VAL_ 1519 ADASIS_NAVILINK_DgMpCnSpdLmTyp 0 "LANE DEPENDENT" 1 "ONLY BY FOG" 2 "ONLY BY NIGHT" 3 "ONLY BY DAY" 4 "BY TIME OF DAY" 5 "ONLY BY RAIN" 6 "ONLY BY SNOW" 7 "UNKNOWN" ;
VAL_ 1519 SrrndVsnRcrdrVwprtSeltn 0 "Unknown" 1 "Playback Mosaic" 2 "Playback Zoom1" 3 "Playback Zoom2" 4 "Playback Zoom3" 5 "Playback Zoom4" 6 "List Recent" 7 "List Saved" 8 "No Request" ;
VAL_ 1519 SrrndVsnRcrdrFileSeltn 0 "Unknown" 1 "File_1" 2 "File_2" 3 "File_3" 4 "File_4" 5 "File_5" 6 "No Selection" ;
VAL_ 1519 SrrndVsnRcrdrFileDeltn 0 "Unknown" 1 "File_1" 2 "File_2" 3 "File_3" 4 "File_4" 5 "File_5" 6 "No Selection" ;
VAL_ 1519 PFASndSeltnCstChgSetReq 0 "No Action" 1 "Pedestrian Alert Sound 1" 2 "Pedestrian Alert Sound 2" 3 "Pedestrian Alert Sound 3" 4 "RESERVED_4" 5 "RESERVED_5" 6 "RESERVED_6" 7 "RESERVED_7" ;
VAL_ 1519 SrrndVsnRcrdrPlybkSeltn 0 "Unknown" 1 "Play" 2 "Pause" 3 "Rewind" 4 "Fast Forward" 5 "No Selection" ;
VAL_ 1519 SrrndVsnRcrdrPlybkFcs 0 "Unknown" 1 "View_1" 2 "View_2" 3 "View_3" 4 "View_4" 5 "Zoomed" 6 "No Focus" ;
VAL_ 1519 ADASIS_NAVILINK_BldUpFlg 0 "NOT VALID" 1 "VALID" ;
VAL_ 1519 PASftBtnSeltdStatRw 0 "Not_Pressed" 1 "Pressed" 2 "Unknown" 3 "Failed" ;
VAL_ 1519 APASftBtnSeltdStatRw 0 "Not_Pressed" 1 "Pressed" 2 "Unknown" 3 "Failed" ;
VAL_ 1519 VGS_TrlrActv 0 "FALSE" 1 "TRUE" ;
VAL_ 1519 VGS_DynActv 0 "FALSE" 1 "TRUE" ;
VAL_ 1519 VGS_CurbVwActv 0 "FALSE" 1 "TRUE" ;
VAL_ 1520 TrgdVidRecSwAct 0 "FALSE" 1 "TRUE" ;
VAL_ 1520 ADASIS_NAVILINK_CntrldAccssRd 0 "ROAD IS NOT CONTROLLED ACCESS ROAD" 1 "ROAD IS CONTROLLED ACCESS ROAD" ;
VAL_ 1520 SrrndVsnRcrdrSaveFile 0 "Unknown" 1 "Save" 2 "Not Pressed" ;
VAL_ 1520 SrrndVsnRcrdrRcrdSeltn 0 "Unknown" 1 "Enabled" 2 "Disabled" ;
VAL_ 1520 SrrndVsnRcrdrListPgSeltn 0 "Unknown" 1 "Page Up" 2 "Page Down" 3 "No Selection" ;
VAL_ 1814 ONPC_DprtrDyOfWkReq 0 "Unknown" 1 "Sunday" 2 "Monday" 3 "Tuesday" 4 "Wednesday" 5 "Thursday" 6 "Friday" 7 "Saturday" ;
VAL_ 1814 ONPC_Req 0 "No Action" 1 "Charge Now" 2 "Charge Later" ;
VAL_ 1814 DAPR_CtlDir 0 "None" 1 "Left" 2 "Right" 3 "Center" 4 "Custom1" 5 "Custom 2" 6 "Custom 3" 7 "Custom 4" ;
VAL_ 1814 DAPR_CurrPrmt 0 "FALSE" 1 "TRUE" ;
VAL_ 1814 DAPR_CtlZn 0 "None" 1 "Zone 1" 2 "Zone 2" 3 "Zone 3" 4 "Zone 4" 5 "Zone 5" 6 "Zone 6" 7 "Zone 7" 8 "Zone 8" 9 "Zone 9" 10 "Zone 10" 11 "Zone 11" 12 "Zone 12" 13 "Zone 13" 14 "Custom 1" 15 "Custom 2" ;
VAL_ 1814 LVMAVC_RmtEnbl 0 "NO_ACTION" 1 "REMOTE_ENABLE_ON" 2 "REMOTE_ENABLE_ACTIVE" ;
VAL_ 1814 LVMAVC_PrmtAudResp 0 "NO_ACTION" 1 "ACTIVE" ;
VAL_ 1814 LVMAVC_ApplID 0 "NO_ACTION" 1 "LVM_NAV" 2 "LVM_DMB" 3 "LVM_PERFORMANCE_COMPUTER" 4 "LVM_COMPLEX_MODE" ;
VAL_ 1814 LVMAVC_StreoAudResp 0 "NO_ACTION" 1 "ACTIVE" ;
VAL_ 1814 LVMAVC_SpchRcgnAval 0 "NO_ACTION" 1 "LVM_SPEECH_REC_AVAILABLE" ;
VAL_ 1814 LVMAVC_RmtSpchRcgnID 0 "NO_ACTION" 1 "LVM_NAV" 2 "LVM_DMB" 3 "LVM_PDR" ;
VAL_ 1814 LVMAVC_RmtSpchRcgnActn 0 "NO_ACTION" 1 "ACTIVATE_LVM_SR" 2 "PTT_BUTTON_PRESS" 3 "END_BUTTON_PRESS" ;
VAL_ 1814 OvrrdNextPlndCbnPrcndtngReq 0 "No Action" 1 "Off" 2 "On" ;
VAL_ 1815 HMIInCarVcCommCtl 0 "ICC_Off" 1 "Front_High_Rear_High" 2 "Front_High_Rear_Normal" 3 "Front_High_Rear_Off" 4 "Front_Normal_Rear_High" 5 "Front_Normal_Rear_Normal" 6 "Front_Normal_Rear_Off" ;
VAL_ 1815 AutoTrnspHdActvnCstChgSetReq 0 "No Action" 1 "Active" 2 "Inactive" ;
VAL_ 1815 AutoLnChgCstChgSetReq 0 "No Action" 1 "Off" 2 "On" 3 "LCOD" 4 "LCOD and ALC" ;
VAL_ 1815 ChrgPwrLossAlrtCstSetReq 0 "No Action" 1 "Off" 2 "On" ;
VAL_ 1815 ChrgDatReq 0 "No Action" 1 "Wakeup Init All" 2 "Reinit All" 3 "Reinit Partial" ;
VAL_ 1815 LocBsdChrgPstnMdfnReq 0 "No Action" 1 "Store Position 1" 2 "Store Position 2" 3 "Store Position 3" 4 "Store Position 4" ;
VAL_ 1815 TrlrHtchTyp 0 "Unknown" 1 "Conventional" 2 "5th Wheel" 3 "Gooseneck" ;
VAL_ 1815 LocBsdChrgCstSetReq 0 "No Action" 1 "Off" 2 "On" ;
VAL_ 1815 FrtCntrStckVidInSel 0 "Primary Video Input" 1 "Reserved" 2 "LVM Video Input" ;
VAL_ 1815 ChrgSysAudblIndCstSetReq 0 "No Action" 1 "Off" 2 "On" ;
VAL_ 1815 Frt360CamSwAct 0 "FALSE" 1 "TRUE" ;
VAL_ 1815 DrvrSeltdTrlrPrsnt 0 "Trailer Present" 1 "No Trailer" ;
VAL_ 1815 DirAudPrmtRndrngEnbld 0 "FALSE" 1 "TRUE" ;
VAL_ 1815 TrlrTyp 0 "Unknown" 1 "Box" 2 "Not-Box" ;
VAL_ 1815 TrlrStatTowHaulModeOvrrd 0 "No Override" 1 "Override to Not Tow Haul" 2 "Unused and Reserved 1" 3 "Unused and Reserved 2" ;
VAL_ 1815 TrlrAppAux1CamPrvwReqd 0 "FALSE" 1 "TRUE" ;
VAL_ 1815 TrlRvsLghtFldEnbld 0 "FALSE" 1 "TRUE" ;
VAL_ 1815 LifetmEleclEngyEconRstReqd 0 "FALSE" 1 "TRUE" ;
VAL_ 1815 HybTripDatRstReqd 0 "FALSE" 1 "TRUE" ;
VAL_ 1815 HndsFrVcCallActv 0 "FALSE" 1 "TRUE" ;
VAL_ 1815 HiVltgBatStopChrgReq 0 "FALSE" 1 "TRUE" ;
VAL_ 1815 FrtZnAudVolSyncCtlOn 0 "FALSE" 1 "TRUE" ;
VAL_ 1815 FrtCntrStckTchCtlrRstCmd 0 "FALSE" 1 "TRUE" ;
VAL_ 1815 TrlrProfDrvrReqdSeltn 0 "No Action" 1 "Default Profile" 2 "Profile1" 3 "Profile2" 4 "Profile3" 5 "Profile4" 6 "Profile5" 7 "Profile6" 8 "Profile7" 9 "Profile8" 10 "Profile9" 11 "Profile10" 12 "Profile11" 13 "Profile12" 14 "Profile13" 15 "Profile14" 16 "Profile15" 17 "Profile16" 18 "Profile17" 19 "Profile18" 20 "Profile19" 21 "Profile20" ;
VAL_ 1815 VcRcgnSesnActv 0 "FALSE" 1 "TRUE" ;
VAL_ 1815 TrlrTirePresSnsrIDLrnReqd 0 "FALSE" 1 "TRUE" ;
VAL_ 1815 TrlrTirePresProfXferd 0 "FALSE" 1 "TRUE" ;
VAL_ 1815 TrlrThftAlrtEnbld 0 "FALSE" 1 "TRUE" ;
VAL_ 1815 TrlrLghtAlrtEnbld 0 "FALSE" 1 "TRUE" ;
VAL_ 1815 TrlrAppInvsblTrlrPrvwReqd 0 "FALSE" 1 "TRUE" ;
VAL_ 1815 TrlrAppAux2CamPrvwReqd 0 "FALSE" 1 "TRUE" ;
VAL_ 1815 DMSIntnDrvrCstChgSetReq 0 "No Action" 1 "Off" 2 "On" ;
VAL_ 1827 TrlrProfDeltn 0 "No Profile Deleted" 1 "Profile1 Deleted" 2 "Profile2 Deleted" 3 "Profile3 Deleted" 4 "Profile4 Deleted" 5 "Profile5 Deleted" 6 "Profile6 Deleted" 7 "Profile7 Deleted" 8 "Profile8 Deleted" 9 "Profile9 Deleted" 10 "Profile10 Deleted" 11 "Profile11 Deleted" 12 "Profile12 Deleted" 13 "Profile13 Deleted" 14 "Profile14 Deleted" 15 "Profile15 Deleted" 16 "Profile16 Deleted" 17 "Profile17 Deleted" 18 "Profile18 Deleted" 19 "Profile19 Deleted" 20 "Profile20 Deleted" ;
VAL_ 1827 NumofAxls 0 "Unknown" 1 "1" 2 "2" 3 "3" ;
VAL_ 1433 ReqRrClmtApp 0 "FALSE" 1 "TRUE" ;
VAL_ 1433 ReqFrtClmtApp 0 "FALSE" 1 "TRUE" ;
VAL_ 1817 HtdStrgWhlSwActv_HVAC_FP_F 0 "FALSE" 1 "TRUE" ;
VAL_ 1817 ManHtdStrgWhlReqd_HVAC_FP_F 0 "FALSE" 1 "TRUE" ;
VAL_ 1817 ManHtdStrgWhlReqd_HVAC_FP_F_Inv 0 "FALSE" 1 "TRUE" ;
VAL_ 1817 HtdStrgWhlStkSw_HVAC_FP_F 0 "FALSE" 1 "TRUE" ;
VAL_ 1817 HtdStrgWhlStkSw_HVAC_FP_F_Inv 0 "FALSE" 1 "TRUE" ;
VAL_ 1435 RHVSRR_HtdBckLvlChgUp 0 "FALSE" 1 "TRUE" ;
VAL_ 1435 RHVSRR_HtdBckLvlChgDn 0 "FALSE" 1 "TRUE" ;
VAL_ 1435 RHVSLR_VntLvlChgUp 0 "FALSE" 1 "TRUE" ;
VAL_ 1435 RHVSLR_VntLvlChgDn 0 "FALSE" 1 "TRUE" ;
VAL_ 1435 RHVSLR_HtdCushBckLvlChgUp 0 "FALSE" 1 "TRUE" ;
VAL_ 1435 RHVSLR_HtdCushBckLvlChgDn 0 "FALSE" 1 "TRUE" ;
VAL_ 1435 RHVSLR_HtdBckLvlChgUp 0 "FALSE" 1 "TRUE" ;
VAL_ 1435 RHVSLR_HtdBckLvlChgDn 0 "FALSE" 1 "TRUE" ;
VAL_ 1435 RHVSRR_VntLvlChgUp 0 "FALSE" 1 "TRUE" ;
VAL_ 1435 RHVSRR_VntLvlChgDn 0 "FALSE" 1 "TRUE" ;
VAL_ 1435 RHVSRR_HtdCushBckLvlChgUp 0 "FALSE" 1 "TRUE" ;
VAL_ 1435 RHVSRR_HtdCushBckLvlChgDn 0 "FALSE" 1 "TRUE" ;
VAL_ 1436 FCSTP12_FrtCntrStckTchFlg2 0 "FALSE" 1 "TRUE" ;
VAL_ 1436 FCSTP12_FrtCntrStckTchFlg1 0 "FALSE" 1 "TRUE" ;
VAL_ 1436 StrgeOpn 0 "FALSE" 1 "TRUE" ;
VAL_ 1437 FCSTP34_FrtCntrStckTchFlg4 0 "FALSE" 1 "TRUE" ;
VAL_ 1437 FCSTP34_FrtCntrStckTchFlg3 0 "FALSE" 1 "TRUE" ;
VAL_ 1438 FCSS1_FrtCntrStckSldr1Prxmty 0 "NOPROXIMITY_NOTOUCH" 1 "PROXIMITY_DETECTED" 2 "TOUCH_DETECTED" 3 "RESERVED" ;
VAL_ 1438 FCSS2_FrtCntrStckSldr2Prxmty 0 "NOPROXIMITY_NOTOUCH" 1 "PROXIMITY_DETECTED" 2 "TOUCH_DETECTED" 3 "RESERVED" ;
VAL_ 1438 FCSS3_FrtCntrStckSldr3Prxmty 0 "NOPROXIMITY_NOTOUCH" 1 "PROXIMITY_DETECTED" 2 "TOUCH_DETECTED" 3 "RESERVED" ;
VAL_ 1248 FrtCntrStckPriVidInLckd 0 "Not_Locked" 1 "Locked" ;
VAL_ 1248 FrtCntrStckLVMVidInLckd 0 "Not_Locked" 1 "Locked" ;
VAL_ 1818 AutoTransGrDispdVal 0 "None" 1 "P" 2 "R" 3 "N" 4 "D" 5 "D1" 6 "D2" 7 "D3" 8 "D4" 9 "D5" 10 "D6" 11 "D7" 12 "D8" 13 "D9" 14 "D10" 15 "First(1)" 16 "Second(2)" 17 "Third(3)" 18 "Fourth(4)" 19 "Fifth(5)" 20 "Sixth(6)" 21 "Seventh(7)" 22 "Eighth(8)" 23 "Ninth(9)" 24 "M" 25 "M1" 26 "M2" 27 "M3" 28 "M4" 29 "M5" 30 "M6" 31 "M7" 32 "M8" 33 "M9" 34 "M10" 35 "L" 36 "L1" 37 "L2" 38 "L3" 39 "L4" 40 "L5" 41 "L6" 42 "L7" 43 "L8" 44 "L9" 45 "L10" 46 "I" 47 "Park In Progress" 48 "Reverse In Progress" 49 "Neutral In Progress" 50 "Drive In Progress" 51 "Dbar1" 52 "Dbar2" 53 "Dbar3" 54 "Dbar4" 55 "Dbar5" 56 "Dbar6" 57 "Dbar7" 58 "Dbar8" 59 "Dbar9" 60 "Dbar10" 61 "Manual In Progress" ;
VAL_ 1818 AutoTransGrDispdVal_Inv 0 "FALSE" 1 "TRUE" ;
VAL_ 723 JmpStrtReqd 0 "FALSE" 1 "TRUE" ;
VAL_ 1441 StrWhlCtlVolDnSw 0 "Released" 1 "Pressed" ;
VAL_ 1441 StrWhlCtlPshToTlkSw 0 "Released" 1 "Pressed" ;
VAL_ 1441 StrWhlCtlFvrtUpSw 0 "Released" 1 "Pressed" ;
VAL_ 1441 StrWhlCtlFvrtDnSw 0 "Released" 1 "Pressed" ;
VAL_ 1441 StrWhlCtlEndSw 0 "Released" 1 "Pressed" ;
VAL_ 1441 ChmMngrSoH 0 "UNKNOWN" 1 "INITIALIZED" 2 "RESERVED_2" 3 "RESERVED_3" 4 "RESERVED_4" 5 "RESERVED_5" 6 "RESERVED_6" 7 "RESERVED_7" ;
VAL_ 1441 StrWhlCtlVolUpSw 0 "Released" 1 "Pressed" ;
VAL_ 1522 HUD_RclCmpt 0 "No Recall Requested" 1 "Recall In Process" 2 "Recall Complete" ;
VAL_ 1522 HUD_CustSelActvStat 0 "FALSE" 1 "TRUE" ;
VAL_ 1522 HUD_CustSelActvStat_Inv 0 "FALSE" 1 "TRUE" ;
VAL_ 1522 DispMeasSysExtnd 0 "US" 1 "IMPERIAL" 2 "Metric KM/L" 3 "Metric L/100KM" ;
VAL_ 1522 ClstrAnmStat 0 "Uninitialized" 1 "Ready" 2 "WelcomePlay" 3 "StartPlay" 4 "ShutdownPlay" ;
VAL_ 1522 PAMutDrvrReq 0 "No Action" 1 "Mute Requested" 2 "Unmute Requested" ;
VAL_ 1522 NtVsnVidCntrstUserReq 0 "No Action" 1 "Increase" 2 "Decrease" 3 "Set to default" ;
VAL_ 1522 NtVsnVidBrghtnsUserReq 0 "No Action" 1 "Increase" 2 "Decrease" 3 "Set to default" ;
VAL_ 1522 IPC_RunCrnkInpActv 0 "FALSE" 1 "TRUE" ;
VAL_ 1522 IPC_RunCrnkInpActv_Inv 0 "FALSE" 1 "TRUE" ;
VAL_ 1522 StkHUD_CustSelStat 0 "FALSE" 1 "TRUE" ;
VAL_ 1522 FuelFiltLifeRstReqd 0 "FALSE" 1 "TRUE" ;
VAL_ 1522 DispMeasSys 0 "Metric" 1 "English" ;
VAL_ 1522 ClstrHMI_Rdy 0 "FALSE" 1 "TRUE" ;
VAL_ 1522 APARghtSftBtnStatIPC 0 "NOT_PRESSED" 1 "PRESSED" ;
VAL_ 1522 APALftSftBtnStatIPC 0 "NOT_PRESSED" 1 "PRESSED" ;
VAL_ 1522 APAFcStatIPC 0 "NO_FOCUS" 1 "FOCUS" ;
VAL_ 1522 AmbtLgtGblPrxmtyEnCstChgSetReq 0 "No Action" 1 "Enable" 2 "Disable" ;
VAL_ 1522 TSMWrngPopUpSts 0 "TSM Warning Off" 1 "TSM Warning On" ;
VAL_ 1522 TSMSgnNtfnWrnDispd 0 "FALSE" 1 "TRUE" ;
VAL_ 1522 TSMPageDispActv 0 "FALSE" 1 "TRUE" ;
VAL_ 1522 TSMCustRstReq 0 "FALSE" 1 "TRUE" ;
VAL_ 1522 StrgWhlCtlInCarVcCommCtlSw 0 "Released" 1 "Pressed" ;
VAL_ 1247 Trip1Odo_Inv 0 "FALSE" 1 "TRUE" ;
VAL_ 1247 Trip2Odo_Inv 0 "FALSE" 1 "TRUE" ;
VAL_ 1247 LnchCtlWhlSlReq 0 "No Action" 1 "Five Percent" 2 "Five And A Half Percent" 3 "Six Percent" 4 "Six And A Half Percent" 5 "Seven Percent" 6 "Seven And A Half Percent" 7 "Eight Percent" 8 "Eight And A Half Percent" 9 "Nine Percent" 10 "Nine And A Half Percent" 11 "Ten Percent" 12 "Ten And A Half Percent" 13 "Eleven Percent" 14 "Eleven And a Half Percent" 15 "Twelve Percent" 16 "Twelve And A Half Percent" 17 "Thirteen Percent" 18 "Thirteen And A Half Percent" 19 "Fourteen Percent" 20 "Fourteen And A Half Percent" 21 "Fifteen Percent" ;
VAL_ 1247 LnchCtlEngRPMReq 0 "No Action" 1 "800" 2 "900" 3 "1000" 4 "1100" 5 "1200" 6 "1300" 7 "1400" 8 "1500" 9 "1600" 10 "1700" 11 "1800" 12 "1900" 13 "2000" 14 "2100" 15 "2200" 16 "2300" 17 "2400" 18 "2500" 19 "2600" 20 "2700" 21 "2800" 22 "2900" 23 "3000" 24 "3100" 25 "3200" 26 "3300" 27 "3400" 28 "3500" 29 "3600" 30 "3700" 31 "3800" 32 "3900" 33 "4000" 34 "FlexibleRPM 1" 35 "FlexibleRPM 2" 36 "FlexibleRPM 3" 37 "FlexibleRPM 4" 38 "FlexibleRPM 5" ;
VAL_ 1247 EngAirFiltMonDrvrReq 0 "No Action" 1 "Enable" 2 "Disable" 3 "Reset" ;
VAL_ 1247 BrkPadLifeSysDrvrReq 0 "No Action" 1 "Disable" 2 "Enable" 3 "Reset Front" 4 "Reset Rear" ;
VAL_ 1819 TCStmpDsblReqConf 0 "No action" 1 "NO" 2 "YES" ;
VAL_ 1819 TCSCurrStReq 0 "No action" 1 "OFF" 2 "ON" ;
VAL_ 1819 LnchCtlModeReq 0 "No Action" 1 "Automatic" 2 "Custom" 3 "Line Lock" ;
VAL_ 1819 RdHgtAtLocStorConf 0 "No Action" 1 "Store" 2 "Clear" 3 "All Clear" 4 "Undo Delete" ;
VAL_ 1819 EngOilLifeRstReq 0 "FALSE" 1 "TRUE" ;
VAL_ 1819 VehStbEnhCurrStReq 0 "No action" 1 "OFF" 2 "ON" ;
VAL_ 1819 VehStbCompMdCurrStReq 0 "No action" 1 "OFF" 2 "ON" ;
VAL_ 1819 TPMTrLdnRstReq 0 "UNKNOWN" 1 "LIGHT LOAD" 2 "BEST ECONOMY LOAD" 3 "MAX LOAD" ;
VAL_ 1819 VehFlRngLwIO 0 "FALSE" 1 "TRUE" ;
VAL_ 1819 TrnsOilLfRstRq 0 "No Request" 1 "Reset Request Active" ;
VAL_ 1819 TripBEleclEngyEconRstReqd 0 "FALSE" 1 "TRUE" ;
VAL_ 1819 TripAEleclEngyEconRstReqd 0 "FALSE" 1 "TRUE" ;
VAL_ 1819 TPSnsrProgEvReq 0 "FALSE" 1 "TRUE" ;
VAL_ 1819 LnchCtlRelLineLckReqd 0 "FALSE" 1 "TRUE" ;
VAL_ 1819 FobProgEvntRqd 0 "FALSE" 1 "TRUE" ;
VAL_ 1819 ACCAutoSetSpdCstChgSetReq 0 "No Action" 1 "Off" 2 "On" ;
VAL_ 1819 DMSDrwIntnWrnDrvrResp 0 "No Action" 1 "Dismiss" ;
VAL_ 1819 TransOilFiltLifeRstReq 0 "No Request" 1 "Reset Request Active" ;
VAL_ 1819 CustmStbCtlRdctReqConf 0 "No Action" 1 "No" 2 "Yes" ;
VAL_ 1884 FllwgDstIndTmDstSel 0 "TIME" 1 "DISTANCE" ;
VAL_ 1181 VehFlRngCalc_Inv 0 "FALSE" 1 "TRUE" ;
VAL_ 1181 VehSpdBsgDispStat 0 "Unknown" 1 "Enabled" 2 "Disabled" ;
VAL_ 1181 FuelLvlLoIndOn 0 "FALSE" 1 "TRUE" ;
VAL_ 1820 MFCInfoActvnReqd 0 "FALSE" 1 "TRUE" ;
VAL_ 1245 PDRRI_LpDiffGainLoss 0 "Loss" 1 "Gain" ;
VAL_ 1821 LVMAVR_PrmtAudReq 0 "NO_ACTION" 1 "PROMPT_REQUEST" ;
VAL_ 1821 LVMAVR_DispReq 0 "NO_ACTION" 1 "LVM_NAV" 2 "LVM_DMB" 3 "LVM_PDR" ;
VAL_ 1821 LVMAVR_ApplStat 0 "NO_ACTION" 1 "LVM_NAV" 2 "LVM_DMB" 3 "LVM_PERFORMANCE_COMPUTER" 4 "LVM_COMPLEX_MODE" ;
VAL_ 1821 IconRcrdReqActv 0 "FALSE" 1 "TRUE" ;
VAL_ 1821 LVMAVR_StreoAudReq 0 "NO_ACTION" 1 "STEREO_REQUEST" ;
VAL_ 1821 LVMAVR_SpchRcgnActv 0 "NO_ACTION" 1 "LVM_SPEECH_REC_READY" 2 "LVM_SPEECH_REC_ACTIVE" ;
VAL_ 729 TeleAlrmVisReq 0 "NO_ACTION" 1 "ACTIVE" 2 "CANCEL_FLASH" ;
VAL_ 729 TeleAlrmHrnReq 0 "NO_ACTION" 1 "ACTIVE" 2 "CANCEL_HORN" ;
VAL_ 729 RmtTrlrLtngSeqReq 0 "No Action" 1 "Off" 2 "On" ;
VAL_ 1443 ASVSC_ReqEnbld 0 "FALSE" 1 "TRUE" ;
VAL_ 1443 AudSeltdSrcReq 0 "No Action" 1 "AM" 2 "FM" 3 "XM" 4 "DAB" 5 "MediaPlayer" 6 "IPOD" 7 "Bluetooth" 8 "AUX" 9 "Audio Disk Player" 10 "LVM Stereo Audio" 11 "Internet App Audio" 12 "RSI_1" 13 "RSI_2" 14 "RadioSourceReserve14" 15 "RadioSourceReserve15" 16 "RadioSourceReserve16" 17 "RadioSourceReserve17" 18 "RadioSourceReserve18" 19 "RadioSourceReserve19" 20 "RadioSourceReserve20" 21 "RadioSourceReserve21" 22 "RadioSourceReserve22" 23 "RadioSourceReserve23" 24 "RadioSourceReserve24" 25 "RadioSourceReserve25" 26 "RadioSourceReserve26" 27 "RadioSourceReserve27" 28 "RadioSourceReserve29" 29 "RadioSourceReserve30" 30 "RadioSourceReserve31" ;
VAL_ 1443 V2VEvnt2ChmEvntStat 0 "No Action" 1 "Active" 2 "Cancel Chime" ;
VAL_ 1443 V2VEvnt1ChmEvntStat 0 "No Action" 1 "Active" 2 "Cancel Chime" ;
VAL_ 1443 TBTTrnChmEvntStat 0 "NO_ACTION" 1 "ACTIVE" 2 "CANCEL_CHIME" ;
VAL_ 1443 V2XOprtlStsInd 0 "Unknown" 1 "Off" 2 "Operational Alerts Enabled" 3 "Operational Alerts Disabled" 4 "Operation V2X Disabled" 5 "Manufacturing" 6 "Service" 7 "Failed" ;
VAL_ 1443 V2VEvnt6ChmEvntStat 0 "No Action" 1 "Active" 2 "Cancel Chime" ;
VAL_ 1443 V2VEvnt5ChmEvntStat 0 "No Action" 1 "Active" 2 "Cancel Chime" ;
VAL_ 1443 V2VEvnt4ChmEvntStat 0 "No Action" 1 "Active" 2 "Cancel Chime" ;
VAL_ 1443 V2VEvnt3ChmEvntStat 0 "No Action" 1 "Active" 2 "Cancel Chime" ;
VAL_ 1443 V2VAlrtAudAttnReqd 0 "FALSE" 1 "TRUE" ;
VAL_ 1523 TAR_AudSrcStat 0 "NO_ACTION" 1 "AUDIO_READY" 2 "AUDIO_PLAYING" 3 "AUDIO_REQUEST" 4 "AUDIO_DISCONNECT RESERVED_1" 5 "RESERVED_2" 6 "RESERVED_3" 7 "RESERVED_4" 8 "RESERVED_5" 9 "RESERVED_6" 10 "RESERVED_7" 11 "RESERVED_8" 12 "RESERVED_9" 13 "RESERVED_10" 14 "RESERVED_11" ;
VAL_ 1523 TAR_AudConctReq 0 "NO ACTION" 1 "MIX_PROMPT" 2 "MUTEX_PROMPT" 3 "RING_TONE" 4 "PHONE" 5 "EMERGENCY_PHONE" 6 "RESERVED_1" 7 "RESERVED_2" 8 "RESERVED_3" 9 "RESERVED_4" 10 "RESERVED_5" 11 "RESERVED_6" 12 "RESERVED_7" 13 "RESERVED_8" 14 "RESERVED_9" 15 "RESERVED_10" ;
VAL_ 1822 InfoActivtnReq 0 "FALSE" 1 "TRUE" ;
VAL_ 1822 TnrFreqBndReq 0 "No Action" 1 "Off" 2 "AM" 3 "FM" 4 "DAB" 5 "XM" 6 "RadioBandReserve6" 7 "RadioBandReserve7" 8 "RadioBandReserve8" 9 "RadioBandReserve9" 10 "RadioBandReserve10" 11 "RadioBandReserve11" 12 "RadioBandReserve12" 13 "RadioBandReserve13" 14 "RadioBandReserve14" 15 "RadioBandReserve15" ;
VAL_ 1243 V2VT_LgtActlPhs 0 "Unknown" 1 "Green" 2 "Yellow" 3 "Red" ;
VAL_ 1243 V2VT_EmrgVehWrnDir 0 "Not Available" 1 "Front" 2 "Right" 3 "Back" 4 "Left" ;
VAL_ 1243 V2VT_LgtPhsAtArvl 0 "Unknown" 1 "Green" 2 "Yellow" 3 "Red" ;
VAL_ 1243 V2VT_LgtVldDir 0 "Unknown" 1 "Straight" 2 "Left" 3 "Right" 4 "All Direction" ;
VAL_ 1243 V2VT_WrnIndReq 0 "No Indication" 1 "Hard Braking" 2 "Slippery Road" 3 "Stationary Vehicle" 4 "Emergency Vehicle" 5 "Intersection Collision Left" 6 "Intersection Collision Right" 7 "Construction Ahead" 8 "Green Light Optimal Speed Advisory" 9 "Intersection Stop" ;
VAL_ 1243 TnDrvrVolLimRmtCstChgSetReq 0 "No Action" 1 "Off" 2 "On" ;
VAL_ 1886 EmrgRespSysTyp 0 "Unknown" 1 "none" 2 "Onstar" 3 "eCall" 4 "ChevyStar" 5 "ERA" 6 "Generic" ;
VAL_ 1507 ByclDtnCstChgSetReq 0 "No Action" 1 "Off" 2 "Alert" ;
VAL_ 1507 LBCCDRR_PstnNumReq 0 "No Action" 1 "Position Number 1" 2 "Position Number 2" 3 "Position Number 3" 4 "Position Number 4" ;
VAL_ 1507 LBCCDRR_ClrStrdPstnReq 0 "No Action" 1 "Request to Clear Position" 2 "Confirmation to Clear Position" ;
VAL_ 1507 RDMACANFCPP_RadDevPrngNFCAllwd 0 "Unknown" 1 "NFC Pairing Disabled" 2 "NFC Pairing Enabled" ;
VAL_ 1507 NFCICRstReqd 0 "FALSE" 1 "TRUE" ;
VAL_ 1507 HillDscntCtlCurrStatReq 0 "No Action" 1 "Disable" 2 "Enable" ;
VAL_ 1507 RadioDevBTPrngSts 0 "Unknown" 1 "Failed" 2 "Successful" 3 "In progress" 4 "Already paired" ;
VAL_ 1823 RPSU_Mth 0 "Unknown" 1 "January" 2 "February" 3 "March" 4 "April" 5 "May" 6 "June" 7 "July" 8 "August" 9 "September" 10 "October" 11 "November" 12 "December" ;
VAL_ 1823 RPSU_Sts 0 "Unknown" 1 "Inactive" 2 "Scheduled" ;
VAL_ 1823 RadioDevBTDscvrblSts 0 "On" 1 "Off" ;
VAL_ 1823 InfoFrtSnshdMtnReq 0 "No Request" 1 "Open" 2 "Close" ;
VAL_ 1524 PhnLtInVehCstSetAval 0 "FALSE" 1 "TRUE" ;
VAL_ 1524 PhnLtInVehCstCurrSetVal 0 "Setting_Unknown" 1 "Off" 2 "On" 3 "Reserved_3" 4 "Reserved_4" 5 "Reserved_5" 6 "Reserved_6" 7 "Reserved_7" ;
VAL_ 1242 WrlsChrgSysChrgStat 0 "WCS Not Present" 1 "Charging Inactive" 2 "Charging Active" 3 "Charging Complete" 4 "Foreign Object Detected" 5 "WCS Overtemp Shutdown" 6 "Phone Overtemp" 7 "Establishing Communications" ;
VAL_ 1242 NFCEHS_NFCStcRstOcc 0 "FALSE" 1 "TRUE" ;
VAL_ 1242 NFCEHS_NFCHndvrSts 0 "Unknown" 1 "RF Not Detected" 2 "Handover Started" 3 "Handover Successful" 4 "Handover Failure" ;
VAL_ 1242 NFCEHS_NFCErrRFInterErrOOR 0 "FALSE" 1 "TRUE" ;
VAL_ 1242 PhnWrlsChrg1DsbldCstAvlFlg3 0 "FALSE" 1 "TRUE" ;
VAL_ 1242 PhnWrlsChrg1DsbldCstAvlFlg2 0 "FALSE" 1 "TRUE" ;
VAL_ 1242 PhnWrlsChrg1DsbldCstAvlFlg1 0 "FALSE" 1 "TRUE" ;
VAL_ 1242 PhnWrlsChrg1DsbldCstCurrSetVal 0 "Setting Unknown" 1 "Off" 2 "On" ;
VAL_ 1242 PhnLtInVehIndOn 0 "FALSE" 1 "TRUE" ;
VAL_ 1242 NFCDevDtd 0 "FALSE" 1 "TRUE" ;
VAL_ 1178 PhnLtInVehCstAvlFlg7 0 "FALSE" 1 "TRUE" ;
VAL_ 1178 PhnLtInVehCstAvlFlg6 0 "FALSE" 1 "TRUE" ;
VAL_ 1178 PhnLtInVehCstAvlFlg5 0 "FALSE" 1 "TRUE" ;
VAL_ 1178 PhnLtInVehCstAvlFlg4 0 "FALSE" 1 "TRUE" ;
VAL_ 1178 PhnLtInVehCstAvlFlg3 0 "FALSE" 1 "TRUE" ;
VAL_ 1178 PhnLtInVehCstAvlFlg2 0 "FALSE" 1 "TRUE" ;
VAL_ 1178 PhnLtInVehCstAvlFlg1 0 "FALSE" 1 "TRUE" ;
VAL_ 728 HVACTlmCtlTempLvlActvReqd 0 "FALSE" 1 "TRUE" ;
VAL_ 1478 VCCLR_CrgMirLmp 0 "No Action" 1 "On" 2 "Off" ;
VAL_ 1478 VCCLR_CrgLmpHtch 0 "No Action" 1 "On" 2 "Off" ;
VAL_ 1478 VCCLR_CrgLmp 0 "No Action" 1 "On" 2 "Off" ;
VAL_ 1478 VCCLR_CrgBedLmp 0 "No Action" 1 "On" 2 "Off" ;
VAL_ 1478 VCDLR_DomeLgt 0 "No Action" 1 "On" 2 "Off" ;
VAL_ 1478 VCDLR_DomeDft 0 "No Action" 1 "On" 2 "Off" ;
VAL_ 1478 VirtCtlDrvModeReq 0 "Normal" 1 "Powertrain Sport" 2 "Chassis Sport" 3 "Eco" 4 "Mountain" 5 "Hold" 6 "Snow Ice" 7 "Start Stop" 8 "Tow Haul" 9 "Grade Braking Disable" 10 "Speed Matching" 11 "Track" 12 "Exhaust Brake" 13 "Normal AWD" 14 "ManualRegen" 15 "Crawl" 16 "Custom" 17 "Personal" 18 "Baja" 19 "Max Power" 20 "Offroad" 21 "Reserved 2" 22 "Reserved 3" 23 "Reserved 4" 24 "Reserved 5" 25 "Reserved 6" 26 "Reserved 7" 27 "Reserved 8" 28 "Reserved 9" 29 "Reserved 10" 30 "No Mode Change Requested" 31 "Critically Disabled" ;
VAL_ 1478 VirtCtlAutoHiBmReq 0 "No Action" 1 "On" 2 "Off" ;
VAL_ 1478 TireLkDtnUsrReq 0 "No Action" 1 "Enable" 2 "Disable" 3 "Reset" ;
VAL_ 1478 VirtCtlTskLmpReq 0 "No Action" 1 "On" 2 "Left" 3 "Right" 4 "Off" ;
VAL_ 1478 VirtCtlPwrWndLckoutReq 0 "No Action" 1 "On" 2 "Off" ;
VAL_ 1478 VirtCtlFgLmpRrReq 0 "No Action" 1 "On" 2 "Off" ;
VAL_ 1478 VirtCtlFgLmpFrtReq 0 "No Action" 1 "On" 2 "Off" ;
VAL_ 1478 VirtCtlChldSftyLckReq 0 "No Action" 1 "On" 2 "Off" ;
VAL_ 1478 StVntdCoolBkLvlLFVirtCtlReq 0 "No Request" 1 "Off" 2 "Low" 3 "Medium" 4 "High" ;
VAL_ 1478 StHtdCushLvlLFVirtCtlReq 0 "No Request" 1 "Off" 2 "Low" 3 "Medium" 4 "High" ;
VAL_ 1478 StHtdBkLvlLFVirtCtlReq 0 "No Request" 1 "Off" 2 "Low" 3 "Medium" 4 "High" ;
VAL_ 1478 StVntdCoolCushLvlLFVirtCtlReq 0 "No Request" 1 "Off" 2 "Low" 3 "Medium" 4 "High" ;
VAL_ 1482 CldrMth 0 "Unknown" 1 "January" 2 "February" 3 "March" 4 "April" 5 "May" 6 "June" 7 "July" 8 "August" 9 "September" 10 "October" 11 "November" 12 "December" ;
VAL_ 1482 PLCM_LCMFileTrans 0 "No Action" 1 "Begin Transfer" 2 "Successful Block Transfer" 3 "Cancel Transfer" 4 "Retry Last Block" ;
VAL_ 1482 VirtCtlAuxAlrmSnsrReq 0 "No Action" 1 "On" 2 "Off" ;
VAL_ 1482 AutoVehHldVirtReq 0 "No Action" 1 "Disable" 2 "Enable One Key Cycle" 3 "Enable Always" ;
VAL_ 1482 PLCM_LCMDataMsgStat 0 "No Action" 1 "Acknowledge" ;
VAL_ 1517 CustMdDrvlCstChngSetReq 0 "NO ACTION" 1 "CUSTOM_MODE_1" 2 "CUSTOM_MODE_2" 3 "CUSTOM_MODE_3" 4 "CUSTOM_MODE_4" 5 "CUSTOM_MODE_5" 6 "CUSTOM_MODE_6" 7 "CUSTOM_MODE_7" ;
VAL_ 1517 CustMdBrkPdlCstChngSetReq 0 "NO_ACTION" 1 "CUSTOM_MODE_1" 2 "CUSTOM_MODE_2" 3 "CUSTOM_MODE_3" 4 "CUSTOM_MODE_4" 5 "CUSTOM_MODE_5" 6 "CUSTOM_MODE_6" 7 "CUSTOM_MODE_7" ;
VAL_ 1517 CustMdActAeroCstChngSetReq 0 "NO_ACTION" 1 "CUSTOM_MODE_1" 2 "CUSTOM_MODE_2" 3 "CUSTOM_MODE_3" 4 "CUSTOM_MODE_4" 5 "CUSTOM_MODE_5" 6 "CUSTOM_MODE_6" 7 "CUSTOM_MODE_7" ;
VAL_ 1517 CustMdSndCstChngSetReq 0 "NO_ACTION" 1 "CUSTOM_MODE_1" 2 "CUSTOM_MODE_2" 3 "CUSTOM_MODE_3" 4 "CUSTOM_MODE_4" 5 "CUSTOM_MODE_5" 6 "CUSTOM_MODE_6" 7 "CUSTOM_MODE_7" ;
VAL_ 1517 CustMdRideHghtCstChngSetReq 0 "NO_ACTION" 1 "CUSTOM_MODE_1" 2 "CUSTOM_MODE_2" 3 "CUSTOM_MODE_3" 4 "CUSTOM_MODE_4" 5 "CUSTOM_MODE_5" 6 "CUSTOM_MODE_6" 7 "CUSTOM_MODE_7" ;
VAL_ 1517 CustMdPTCstChngSetReq 0 "NO ACTION" 1 "CUSTOM_MODE_1" 2 "CUSTOM_MODE_2" 3 "CUSTOM_MODE_3" 4 "CUSTOM_MODE_4" 5 "CUSTOM_MODE_5" 6 "CUSTOM_MODE_6" 7 "CUSTOM_MODE_7" ;
VAL_ 1517 CustMdStrCstChngSetReq 0 "NO_ACTION" 1 "CUSTOM_MODE_1" 2 "CUSTOM_MODE_2" 3 "CUSTOM_MODE_3" 4 "CUSTOM_MODE_4" 5 "CUSTOM_MODE_5" 6 "CUSTOM_MODE_6" 7 "CUSTOM_MODE_7" ;
VAL_ 1517 CustMdSpnCstChngSetReq 0 "NO_ACTION" 1 "CUSTOM_MODE_1" 2 "CUSTOM_MODE_2" 3 "CUSTOM_MODE_3" 4 "CUSTOM_MODE_4" 5 "CUSTOM_MODE_5" 6 "CUSTOM_MODE_6" 7 "CUSTOM_MODE_7" ;
VAL_ 1517 LvlgSysAlgnMdCstChgSetReq 0 "No Action" 1 "Off" 2 "On" ;
VAL_ 1517 ExtdHillStrtAsstCstChgSetReq 0 "NO_ACTION" 1 "EXTENDED_HOLD" 2 "STANDARD_HOLD" 3 "RESERVED_3" 4 "RESERVED_4" 5 "RESERVED_5" 6 "RESERVED_6" 7 "RESERVED_7" ;
VAL_ 1517 CustMdTrcStbCstChngSetReq 0 "NO_ACTION" 1 "CUSTOM_MODE_1" 2 "CUSTOM_MODE_2" 3 "CUSTOM_MODE_3" 4 "CUSTOM_MODE_4" 5 "CUSTOM_MODE_5" 6 "CUSTOM_MODE_6" 7 "CUSTOM_MODE_7" ;
VAL_ 1517 PrsnlMdActAeroCstChngSetReq 0 "NO_ACTION" 1 "PERSONAL_MODE_1" 2 "PERSONAL_MODE_2" 3 "PERSONAL_MODE_3" 4 "PERSONAL_MODE_4" 5 "PERSONAL_MODE_5" 6 "PERSONAL_MODE_6" 7 "PERSONAL_MODE_7" ;
VAL_ 1517 LvlgSysServMdCstChgSetReq 0 "No Action" 1 "Off" 2 "On" ;
VAL_ 1517 LvlgSysEntEgrsMdCstChgSetReq 0 "No Action" 1 "Off" 2 "On" ;
VAL_ 1517 PrsnlMdDrvlCstChngSetReq 0 "NO_ACTION" 1 "PERSONAL_MODE_1" 2 "PERSONAL_MODE_2" 3 "PERSONAL_MODE_3" 4 "PERSONAL_MODE_4" 5 "PERSONAL_MODE_5" 6 "PERSONAL_MODE_6" 7 "PERSONAL_MODE_7" ;
VAL_ 1517 PrsnlMdBrkPdlCstChngSetReq 0 "NO_ACTION" 1 "PERSONAL_MODE_1" 2 "PERSONAL_MODE_2" 3 "PERSONAL_MODE_3" 4 "PERSONAL_MODE_4" 5 "PERSONAL_MODE_5" 6 "PERSONAL_MODE_6" 7 "PERSONAL_MODE_7" ;
VAL_ 1517 PrsnlMdSpnCstChngSetReq 0 "NO_ACTION" 1 "PERSONAL_MODE_1" 2 "PERSONAL_MODE_2" 3 "PERSONAL_MODE_3" 4 "PERSONAL_MODE_4" 5 "PERSONAL_MODE_5" 6 "PERSONAL_MODE_6" 7 "PERSONAL_MODE_7" ;
VAL_ 1517 PrsnlMdSndCstChngSetReq 0 "NO_ACTION" 1 "PERSONAL_MODE_1" 2 "PERSONAL_MODE_2" 3 "PERSONAL_MODE_3" 4 "PERSONAL_MODE_4" 5 "PERSONAL_MODE_5" 6 "PERSONAL_MODE_6" 7 "PERSONAL_MODE_7" ;
VAL_ 1517 PrsnlMdRideHghtCstChngSetReq 0 "NO_ACTION" 1 "PERSONAL_MODE_1" 2 "PERSONAL_MODE_2" 3 "PERSONAL_MODE_3" 4 "PERSONAL_MODE_4" 5 "PERSONAL_MODE_5" 6 "PERSONAL_MODE_6" 7 "PERSONAL_MODE_7" ;
VAL_ 1517 CustmPT_CfgPgAct 0 "FALSE" 1 "TRUE" ;
VAL_ 1517 DrvrSeltdConf 0 "NO_ACTION" 1 "SETTINGS_ACCEPTED" 2 "SETTINGS_CANCELED" 3 "MENU_ERROR_EVENT" ;
VAL_ 1517 PrsnlMdStrCstChngSetReq 0 "NO_ACTION" 1 "PERSONAL_MODE_1" 2 "PERSONAL_MODE_2" 3 "PERSONAL_MODE_3" 4 "PERSONAL_MODE_4" 5 "PERSONAL_MODE_5" 6 "PERSONAL_MODE_6" 7 "PERSONAL_MODE_7" ;
VAL_ 1518 ACCCSR_Aux1Colr 0 "No Action" 1 "OFF" 2 "Color Type 1" 3 "Color Type 2" 4 "Color Type 3" 5 "Color Type 4" 6 "Color Type 5" 7 "Color Type 6" 8 "Color Type 7" 9 "Color Type 8" 10 "Color Type 9" 11 "Color Type 10" 12 "Color Type 11" 13 "Color Type 12" 14 "Color Type 13" 15 "Color Type 14" 16 "Color Type 15" 17 "Color Type 16" 18 "Color Type 17" 19 "Color Type 18" 20 "Color Type 19" 21 "Color Type 20" 22 "Color Type 21" 23 "Color Type 22" 24 "Color Type 23" 25 "Color Type 24" 26 "Color Type 25" 27 "Color Type 26" 28 "Color Type 27" 29 "Color Type 28" 30 "Color Type 29" 31 "Color Type 30" 32 "Color Type 31" 33 "Color Type 32" 34 "Color Type 33" 35 "Color Type 34" 36 "Color Type 35" 37 "Color Type 36" 38 "Color Type 37" 39 "Color Type 38" 40 "Color Type 39" 41 "Color Type 40" 42 "Color Type 41" 43 "Color Type 42" 44 "Color Type 43" 45 "Color Type 44" 46 "Color Type 45" 47 "Color Type 46" 48 "Color Type 47" 49 "Color Type 48" 50 "Color Type 49" 51 "Color Type 50" 52 "Color Type 51" 53 "Color Type 52" 54 "Color Type 53" 55 "Color Type 54" 56 "Color Type 55" 57 "Color Type 56" 58 "Color Type 57" 59 "Color Type 58" 60 "Color Type 59" 61 "Color Type 60" 62 "Color Type 61" 63 "Color Type 62" 64 "Color Type 63" 65 "Color Type 64" 66 "Color Type 65" 67 "Color Type 66" 68 "Color Type 67" 69 "Color Type 68" 70 "Color Type 69" 71 "Color Type 70" 72 "Color Type 71" 73 "Color Type 72" 74 "Color Type 73" 75 "Color Type 74" 76 "Color Type 75" 77 "Color Type 76" 78 "Color Type 77" 79 "Color Type 78" 80 "Color Type 79" 81 "Color Type 80" 82 "Color Type 81" 83 "Color Type 82" 84 "Color Type 83" 85 "Color Type 84" 86 "Color Type 85" 87 "Color Type 86" 88 "Color Type 87" 89 "Color Type 88" 90 "Color Type 89" 91 "Color Type 90" 92 "Color Type 91" 93 "Color Type 92" 94 "Color Type 93" 95 "Color Type 94" 96 "Color Type 95" 97 "Color Type 96" 98 "Color Type 97" 99 "Color Type 98" 100 "Color Type 99" 101 "Color Type 100" 102 "Color Type 101" 103 "Color Type 102" 104 "Color Type 103" 105 "Color Type 104" 106 "Color Type 105" 107 "Color Type 106" 108 "Color Type 107" 109 "Color Type 108" 110 "Color Type 109" 111 "Color Type 110" 112 "Color Type 111" 113 "Color Type 112" 114 "Color Type 113" 115 "Color Type 114" 116 "Color Type 115" 117 "Color Type 116" 118 "Color Type 117" 119 "Color Type 118" 120 "Color Type 119" 121 "Color Type 120" 122 "Color Type 121" 123 "Color Type 122" 124 "Color Type 123" 125 "Color Type 124" 126 "Color Type 125" 127 "Color Type 126" ;
VAL_ 1518 ACCCSR_Aux1Brghtns 0 "No Action" 1 "BrightnessLevel 1" 2 "BrightnessLevel 2" 3 "BrightnessLevel 3" 4 "BrightnessLevel 4" 5 "ReservedLevel 5" 6 "ReservedLevel 6" 7 "ReservedLevel 7" ;
VAL_ 1518 ACCCSR_Aux1Anm 0 "No Action" 1 "OFF" 2 "Animation Type 1" 3 "Animation Type 2" 4 "Animation Type 3" 5 "Animation Type 4" 6 "Animation Type 5" 7 "Animation Type 6" 8 "Animation Type 7" 9 "Animation Type 8" 10 "Animation Type 9" 11 "Animation Type 10" 12 "Animation Type 11" 13 "Animation Type 12" 14 "Animation Type 13" 15 "Animation Type 14" ;
VAL_ 1518 ACCCSR_IntrAnm 0 "No Action" 1 "OFF" 2 "Animation Type 1" 3 "Animation Type 2" 4 "Animation Type 3" 5 "Animation Type 4" 6 "Animation Type 5" 7 "Animation Type 6" 8 "Animation Type 7" 9 "Animation Type 8" 10 "Animation Type 9" 11 "Animation Type 10" 12 "Animation Type 11" 13 "Animation Type 12" 14 "Animation Type 13" 15 "Animation Type 14" ;
VAL_ 1518 ACCCSR_IntrColr 0 "No Action" 1 "OFF" 2 "Color Type 1" 3 "Color Type 2" 4 "Color Type 3" 5 "Color Type 4" 6 "Color Type 5" 7 "Color Type 6" 8 "Color Type 7" 9 "Color Type 8" 10 "Color Type 9" 11 "Color Type 10" 12 "Color Type 11" 13 "Color Type 12" 14 "Color Type 13" 15 "Color Type 14" 16 "Color Type 15" 17 "Color Type 16" 18 "Color Type 17" 19 "Color Type 18" 20 "Color Type 19" 21 "Color Type 20" 22 "Color Type 21" 23 "Color Type 22" 24 "Color Type 23" 25 "Color Type 24" 26 "Color Type 25" 27 "Color Type 26" 28 "Color Type 27" 29 "Color Type 28" 30 "Color Type 29" 31 "Color Type 30" 32 "Color Type 31" 33 "Color Type 32" 34 "Color Type 33" 35 "Color Type 34" 36 "Color Type 35" 37 "Color Type 36" 38 "Color Type 37" 39 "Color Type 38" 40 "Color Type 39" 41 "Color Type 40" 42 "Color Type 41" 43 "Color Type 42" 44 "Color Type 43" 45 "Color Type 44" 46 "Color Type 45" 47 "Color Type 46" 48 "Color Type 47" 49 "Color Type 48" 50 "Color Type 49" 51 "Color Type 50" 52 "Color Type 51" 53 "Color Type 52" 54 "Color Type 53" 55 "Color Type 54" 56 "Color Type 55" 57 "Color Type 56" 58 "Color Type 57" 59 "Color Type 58" 60 "Color Type 59" 61 "Color Type 60" 62 "Color Type 61" 63 "Color Type 62" 64 "Color Type 63" 65 "Color Type 64" 66 "Color Type 65" 67 "Color Type 66" 68 "Color Type 67" 69 "Color Type 68" 70 "Color Type 69" 71 "Color Type 70" 72 "Color Type 71" 73 "Color Type 72" 74 "Color Type 73" 75 "Color Type 74" 76 "Color Type 75" 77 "Color Type 76" 78 "Color Type 77" 79 "Color Type 78" 80 "Color Type 79" 81 "Color Type 80" 82 "Color Type 81" 83 "Color Type 82" 84 "Color Type 83" 85 "Color Type 84" 86 "Color Type 85" 87 "Color Type 86" 88 "Color Type 87" 89 "Color Type 88" 90 "Color Type 89" 91 "Color Type 90" 92 "Color Type 91" 93 "Color Type 92" 94 "Color Type 93" 95 "Color Type 94" 96 "Color Type 95" 97 "Color Type 96" 98 "Color Type 97" 99 "Color Type 98" 100 "Color Type 99" 101 "Color Type 100" 102 "Color Type 101" 103 "Color Type 102" 104 "Color Type 103" 105 "Color Type 104" 106 "Color Type 105" 107 "Color Type 106" 108 "Color Type 107" 109 "Color Type 108" 110 "Color Type 109" 111 "Color Type 110" 112 "Color Type 111" 113 "Color Type 112" 114 "Color Type 113" 115 "Color Type 114" 116 "Color Type 115" 117 "Color Type 116" 118 "Color Type 117" 119 "Color Type 118" 120 "Color Type 119" 121 "Color Type 120" 122 "Color Type 121" 123 "Color Type 122" 124 "Color Type 123" 125 "Color Type 124" 126 "Color Type 125" 127 "Color Type 126" ;
VAL_ 1518 ACCCSR_IntrBrghtns 0 "No Action" 1 "BrightnessLevel 1" 2 "BrightnessLevel 2" 3 "BrightnessLevel 3" 4 "BrightnessLevel 4" 5 "ReservedLevel 5" 6 "ReservedLevel 6" 7 "ReservedLevel 7" ;
VAL_ 1518 AutDrvLckCstChgSetReq 0 "NO_ACTION" 1 "OFF" 2 "ON" 3 "RESERVED_3" 4 "RESERVED_4" 5 "RESERVED_5" 6 "RESERVED_6" 7 "RESERVED_7" ;
VAL_ 1518 AirQltySensCstChgSetReq 0 "NO_ACTION" 1 "OFF" 2 "LOW_SENSITIVITY" 3 "HI_SENSITIVITY" 4 "RESERVED_4" 5 "RESERVED_5" 6 "RESERVED_6" 7 "RESERVED_7" ;
VAL_ 1518 AutoAirDstCstChgSetReq 0 "NO_ACTION" 1 "DIFFUSE_AIRFLOW" 2 "NORMAL" 3 "DIRECT_AIRFLOW" 4 "OSCILLATING_AIRFLOW" 5 "RESERVED_5" 6 "RESERVED_6" 7 "RESERVED_7" ;
VAL_ 1518 AutUnlckCstChgSetReq 0 "NO_ACTION" 1 "OFF" 2 "ALL_DOORS" 3 "DRIVER_DOOR" 4 "RESERVED_4" 5 "RESERVED_5" 6 "RESERVED_6" 7 "RESERVED_7" ;
VAL_ 1518 AutoFanCstChgSetReq 0 "NO_ACTION" 1 "LOW" 2 "NORMAL" 3 "HIGH" 4 "RESERVED_4" 5 "RESERVED_5" 6 "RESERVED_6" 7 "RESERVED_7" ;
VAL_ 1518 AutoDfgCstChgSetReq 0 "NO_ACTION" 1 "OFF" 2 "ON" 3 "RESERVED_3" 4 "RESERVED_4" 5 "RESERVED_5" 6 "RESERVED_6" 7 "RESERVED_7" ;
VAL_ 1518 AutoCoolStCstChgSetReq 0 "NO_ACTION" 1 "OFF" 2 "ON" 3 "RESERVED_3" 4 "RESERVED_4" 5 "RESERVED_5" 6 "RESERVED_6" 7 "RESERVED_7" ;
VAL_ 1518 AutoRrWpCstChgSetReq 0 "NO_ACTION" 1 "OFF" 2 "ON" 3 "RESERVED_3" 4 "RESERVED_4" 5 "RESERVED_5" 6 "RESERVED_6" 7 "RESERVED_7" ;
VAL_ 1518 AutoMrFldCstChgSetReq 0 "NO_ACTION" 1 "OFF" 2 "ON" 3 "RESERVED_3" 4 "RESERVED_4" 5 "RESERVED_5" 6 "RESERVED_6" 7 "RESERVED_7" ;
VAL_ 1518 AutoHtdStCstChgSetReq 0 "NO_ACTION" 1 "OFF" 2 "ON" 3 "RESERVED_3" 4 "RESERVED_4" 5 "RESERVED_5" 6 "RESERVED_6" 7 "RESERVED_7" ;
VAL_ 1518 ExitLghtngCstChgSetReq 0 "NO_ACTION" 1 "OFF" 2 "THIRTY_SECONDS_DEFAULT" 3 "ONE_MINUTE" 4 "TWO_MINUTES" 5 "RESERVED_5" 6 "RESERVED_6" 7 "RESERVED_7" ;
VAL_ 1518 DayTmTlLtsCstChgSetReq 0 "NO_ACTION" 1 "OFF" 2 "ON" 3 "RESERVED_3" 4 "RESERVED_4" 5 "RESERVED_5" 6 "RESERVED_6" 7 "RESERVED_7" ;
VAL_ 1424 LDCLCstChgSetReq 0 "NO_ACTION" 1 "OFF" 2 "ON" 3 "RESERVED_3" 4 "RESERVED_4" 5 "RESERVED_5" 6 "RESERVED_6" 7 "RESERVED_7" ;
VAL_ 1424 IonzrCtrlCstChgSetReq 0 "NO_ACTION" 1 "OFF" 2 "ON" 3 "RESERVED_3" 4 "RESERVED_4" 5 "RESERVED_5" 6 "RESERVED_6" 7 "RESERVED_7" ;
VAL_ 1424 HFRCCstChgSetReq 0 "NO_ACTION" 1 "OFF" 2 "OPEN_AND_CLOSE" 3 "OPEN_ONLY" 4 "RESERVED_4" 5 "RESERVED_5" 6 "RESERVED_6" 7 "RESERVED_7" ;
VAL_ 1424 PsvUnlckCstChgSetReq 0 "NO_ACTION" 1 "DRIVER_DOOR" 2 "ALL_DOORS" 3 "OFF" 4 "RESERVED_4" 5 "RESERVED_5" 6 "RESERVED_6" 7 "RESERVED_7" ;
VAL_ 1424 PlltnCtrlCstChgSetReq 0 "NO_ACTION" 1 "OFF" 2 "ON" 3 "RESERVED_3" 4 "RESERVED_4" 5 "RESERVED_5" 6 "RESERVED_6" 7 "RESERVED_7" ;
VAL_ 1424 OpDrAtLOCstChgSetReq 0 "NO_ACTION" 1 "OFF" 2 "ON" 3 "RESERVED_3" 4 "RESERVED_4" 5 "RESERVED_5" 6 "RESERVED_6" 7 "RESERVED_7" ;
VAL_ 1424 RemInVehRmCstChgSetReq 0 "NO_ACTION" 1 "OFF" 2 "ON" 3 "RESERVED_3" 4 "RESERVED_4" 5 "RESERVED_5" 6 "RESERVED_6" 7 "RESERVED_7" ;
VAL_ 1424 PwrRrClsrCstChgSetReq 0 "No_Action" 1 "Off" 2 "On" 3 "On_Custom_Height" 4 "RESERVED_4" 5 "RESERVED_5" 6 "RESERVED_6" 7 "RESERVED_7" ;
VAL_ 1424 RevTltMrCstChgSetReq 0 "NO_ACTION" 1 "OFF" 2 "DRIVER" 3 "PASSENGER" 4 "DRIVER_AND_PASSENGER" 5 "RESERVED_5" 6 "RESERVED_6" 7 "RESERVED_7" ;
VAL_ 1424 RemWndOpCstChgSetReq 0 "NO_ACTION" 1 "OFF" 2 "ON" 3 "RESERVED_3" 4 "RESERVED_4" 5 "RESERVED_5" 6 "RESERVED_6" 7 "RESERVED_7" ;
VAL_ 1424 RemLftVehRmCstChgSetReq 0 "NO_ACTION" 1 "OFF" 2 "ON" 3 "RESERVED_3" 4 "RESERVED_4" 5 "RESERVED_5" 6 "RESERVED_6" 7 "RESERVED_7" ;
VAL_ 1424 RmtStrtCoolStCstChgSetReq 0 "NO_ACTION" 1 "OFF" 2 "ON" 3 "RESERVED_3" 4 "RESERVED_4" 5 "RESERVED_5" 6 "RESERVED_6" 7 "RESERVED_7" ;
VAL_ 1424 RmtSnrfOpCstChgSetReq 0 "NO_ACTION" 1 "OFF" 2 "ON" 3 "RESERVED_3" 4 "RESERVED_4" 5 "RESERVED_5" 6 "RESERVED_6" 7 "RESERVED_7" ;
VAL_ 1424 RlkRtUlkDrCstChSetReq 0 "NO_ACTION" 1 "OFF" 2 "ON" 3 "RESERVED_3" 4 "RESERVED_4" 5 "RESERVED_5" 6 "RESERVED_6" 7 "RESERVED_7" ;
VAL_ 1424 RnSnsCstChgSetReq 0 "NO_ACTION" 1 "OFF" 2 "ON" 3 "RESERVED_3" 4 "RESERVED_4" 5 "RESERVED_5" 6 "RESERVED_6" 7 "RESERVED_7" ;
VAL_ 1424 RmtStrtHtdStCstChgSetReq 0 "NO_ACTION" 1 "OFF" 2 "ON" 3 "RESERVED_3" 4 "RESERVED_4" 5 "RESERVED_5" 6 "RESERVED_6" 7 "RESERVED_7" ;
VAL_ 1424 RrZnStUpCstChgSetReq 0 "NO_ACTION" 1 "REAR_OFF" 2 "REAR_MIMIC_FRONT" 3 "REAR_LAST_KNOWN" 4 "RESERVED_4" 5 "RESERVED_5" 6 "RESERVED_6" 7 "RESERVED_7" ;
VAL_ 1424 RrStRmndrEnblDsblCstChgSetReq 0 "No_Action" 1 "Off" 2 "On" ;
VAL_ 1424 RrDfgStUpCstChgSetReq 0 "NO_ACTION" 1 "MANUAL" 2 "AUTOMATIC" 3 "RESERVED_3" 4 "RESERVED_4" 5 "RESERVED_5" 6 "RESERVED_6" 7 "RESERVED_7" ;
VAL_ 1424 RtUlkLtFbCstChgSetReq 0 "NO_ACTION" 1 "OFF" 2 "FLASH_LIGHTS_ON" 3 "RESERVED_3" 4 "RESERVED_4" 5 "RESERVED_5" 6 "RESERVED_6" 7 "RESERVED_7" ;
VAL_ 1424 RtLkFdbkCstChgSetReq 0 "NO_ACTION" 1 "HORN_AND_LIGHTS_OFF" 2 "HORN_AND_LIGHTS_ON" 3 "FLASH_LIGHTS_ONLY" 4 "HORN_CHIRP_ONLY" 5 "RESERVED_5" 6 "RESERVED_6" 7 "RESERVED_7" ;
VAL_ 1506 TODCSR_ChrgSchedDyOfWkReq 0 "No Action" 1 "Sunday" 2 "Monday" 3 "Tuesday" 4 "Wednesday" 5 "Thursday" 6 "Friday" 7 "Saturday" 8 "All Days Same" 9 "Monday to Friday Same" 10 "Saturday and Sunday Same" ;
VAL_ 1506 TODCSR_ChrgSchedCstSetReq 0 "No Action" 1 "Off" 2 "On" ;
VAL_ 1506 TODCSR_ERSPrdDyReq 0 "No Action" 1 "Weekday 1" 2 "Weekday 2" 3 "Weekday 3" 4 "Weekday 4" 5 "Weekday 5" 6 "Weekend 1" 7 "Weekend 2" 8 "Weekend 3" 9 "Weekend 4" 10 "Weekend 5" ;
VAL_ 1506 TODCSR_ERSCstSetReq 0 "No Action" 1 "Off" 2 "On" ;
VAL_ 1506 TODCSR_ERSPrdLvlReq 0 "No Action" 1 "Low Rate" 2 "Medium Rate" 3 "High Rate" 4 "Reserved 1" 5 "Invalid Rate" ;
VAL_ 1506 PrtblChrgCordLimCstSetReq 0 "No Action" 1 "Reduced" 2 "Maximum" ;
VAL_ 1506 TODCSR_ERSPrfReq 0 "No Action" 1 "Low Rate" 2 "Medium Rate" 3 "High Rate" ;
VAL_ 1506 TODCCbnPrcndtngSetReq 0 "No Action" 1 "Off" 2 "On" ;
VAL_ 1506 TODCSR_LocNumReq 0 "No Action" 1 "Not in Stored Location" 2 "Stored Location 1" 3 "Stored Location 2" 4 "Stored Location 3" 5 "Stored Location 4" ;
VAL_ 1506 TODCSR_LocChrgPwrLvlReq 0 "Unknown" 1 "Level 1" 2 "Level 2" 3 "DC" 4 "Wireless" ;
VAL_ 1521 ADASIS_NAVILINK_SpdLmtPsdSpd_DuD 0 "FALSE" 1 "TRUE" ;
VAL_ 1521 ADASIS_NAVILINK_DigMpVerYr 0 "2000" 1 "2001" 2 "2002" 3 "2003" 4 "2004" 5 "2005" 6 "2006" 7 "2007" 8 "2008" 9 "2009" 10 "2010" 11 "2011" 12 "2012" 13 "2013" 14 "2014" 15 "2015" 16 "2016" 17 "2017" 18 "2018" 19 "2019" 20 "2020" 21 "2021" 22 "2022" 23 "2023" 24 "2024" 25 "2025" 26 "2026" 27 "2027" 28 "2028" 29 "2029" 30 "2030" 31 "2031" 32 "2032" 33 "2033" 34 "2034" 35 "2035" 36 "2036" 37 "2037" 38 "2038" 39 "2039" 40 "2040" 41 "2041" 42 "2042" 43 "2043" 44 "2044" 45 "2045" 46 "2046" 47 "2047" 48 "2048" 49 "2049" 50 "2050" 51 "2051" 52 "2052" 53 "2053" 54 "2054" 55 "2055" 56 "2056" 57 "2057" 58 "2058" 59 "2059" 60 "2060" 61 "2061" 62 "2062" 63 "NOT APPLICABLE" ;
VAL_ 1521 ADASIS_NAVILINK_DigMpCndlSpdLmt 0 "UNKNOWN" 1 "<= 5 KM/H [MPH]" 2 "7 KM/H [MPH]" 3 "10 KM/H [MPH]" 4 "15 KM/H [MPH]" 5 "20 KM/H [MPH]" 6 "25 KM/H [MPH]" 7 "30 KM/H [MPH]" 8 "35 KM/H [MPH]" 9 "40 KM/H [MPH]" 10 "45 KM/H [MPH]" 11 "50 KM/H [MPH]" 12 "55 KM/H [MPH]" 13 "60 KM/H" 14 "MPH]65 KM/H [MPH]" 15 "70 KM/H [MPH]" 16 "75 KM/H [MPH]" 17 "80 KM/H [MPH]" 18 "85 KM/H [MPH]" 19 "90 KM/H [MPH]" 20 "95 KM/H [MPH]" 21 "100 KM/H [MPH]" 22 "105 KM/H [MPH]" 23 "110 KM/H [MPH]" 24 "115 KM/H [MPH]" 25 "120 KM/H[MPH]" 26 "130 KM/H [MPH]" 27 "140 KM/H [MPH]" 28 "150 KM/H [MPH]" 29 "160 KM/H [MPH]" 30 "UNLIMITED" 31 "NOT AVAILABLE" ;
VAL_ 1521 ADASIS_NAVILINK_DgtlMpSpdCtgry 0 "> 130 KPH OR > 80 MPH" 1 "101-130 KPH OR 65\???80 MPH" 2 "91-100 KPH OR 55\???64 MPH" 3 "71-90 KPH OR 41\???54 MPH" 4 "51-70 KPH OR 31\???40 MPH" 5 "31-50 KPH OR 21\???30 MPH" 6 "11-30 KPH OR 6 \???20 MPH" 7 "<11 KPH OR < 6 MPH" 8 "UNKNOWN" ;
VAL_ 1521 ADASIS_NAVILINK_DigMpVerQtr 0 "QUARTER 1" 1 "QUARTER 2" 2 "QUARTER 3" 3 "QUARTER 4" ;
VAL_ 1521 ADASIS_NAVILINK_FncRdClss 0 "LOCAL" 1 "SFREEWAY" 2 "FREEWAY" 3 "PED-MALL" 4 "HIGHWAY" 5 "ARTERIAL" 6 "ALLEY" 7 "COLLECTOR" ;
VAL_ 1521 ADASIS_NAVILINK_DigMpEfSpdLmTyp 0 "IMPLICIT" 1 "ON TRAFFIC SIGN" 2 "ONLY BY NIGHT" 3 "ONLY BY DAY" 4 "TIME OF DAY" 5 "ONLY BY RAIN" 6 "ONLY BY SNOW OR FOG" 7 "UNKOWN" ;
VAL_ 1521 ADASIS_NAVILINK_SprtdLnRd 0 "ROAD IS NOT CONTROLLED ACCESS ROAD" 1 "ROAD IS CONTROLLED ACCESS ROAD" ;
VAL_ 1521 ADASIS_NAVILINK_SpdLmtUnt 0 "MILES/H" 1 "KM/H" ;
VAL_ 1521 ADASIS_NAVILINK_MpDtAv 0 "NOT VALID" 1 "VALID" ;
VAL_ 1521 ADASIS_NAVILINK_DigMpPstSpdLmAs 0 "NOT ASSURED" 1 "ASSURED" ;
VAL_ 1521 ADASIS_NAVILINK_DigMpDrvngSd 0 "DRIVING SIDE LEFT" 1 "DRIVING SIDE RIGHT" ;
VAL_ 1521 ADASIS_NAVILINK_LnCtgry 0 "NO INFO AVAILABLE" 1 "ONE LANE" 2 "TWO OR THREE LANES" 3 "FOUR OR MORE LANES" ;
VAL_ 1434 ReqAirDstRRRr 0 "NoAction" 1 "Auto" 2 "Floor" 3 "FloorAndVent" 4 "Vent" 5 "VentAndRoof" 6 "Roof" 7 "RoofAndFloor" 8 "FloorAndVentAndRoof" ;
VAL_ 1434 ReqAirDstRLRr 0 "NoAction" 1 "Auto" 2 "Floor" 3 "FloorAndVent" 4 "Vent" 5 "VentAndRoof" 6 "Roof" 7 "RoofAndFloor" 8 "FloorAndVentAndRoof" ;
VAL_ 1434 HtdStBckCushStckSwLR 0 "FALSE" 1 "TRUE" ;
VAL_ 1434 RrAirHandlingDrActrPwrFdbk 0 "No Action" 1 "Power Off" 2 "Power On" ;
VAL_ 1434 ReqBlwLvlRrAtvRr 0 "FALSE" 1 "TRUE" ;
VAL_ 1434 ReqAirDstChgNxtRRRr 0 "FALSE" 1 "TRUE" ;
VAL_ 1434 ReqAirDstChgNxtRLRr 0 "FALSE" 1 "TRUE" ;
VAL_ 1434 HtdVntStSwActvRR 0 "FALSE" 1 "TRUE" ;
VAL_ 1434 HtdVntStSwActvLR 0 "FALSE" 1 "TRUE" ;
VAL_ 1434 HtdStBckStckSwRR 0 "FALSE" 1 "TRUE" ;
VAL_ 1434 HtdStBckStckSwLR 0 "FALSE" 1 "TRUE" ;
VAL_ 1434 HtdStBckCushStckSwRR 0 "FALSE" 1 "TRUE" ;
VAL_ 1434 VntStStckSwRR 0 "FALSE" 1 "TRUE" ;
VAL_ 1434 VntStStckSwLR 0 "FALSE" 1 "TRUE" ;
VAL_ 1434 RrHVACCtrlInitFin 0 "FALSE" 1 "TRUE" ;
VAL_ 1434 ReqTmpLvlRRAtvRr 0 "FALSE" 1 "TRUE" ;
VAL_ 1434 ReqTmpLvlRLAtvRr 0 "FALSE" 1 "TRUE" ;
VAL_ 1434 ReqSYNC_RrChgRr 0 "FALSE" 1 "TRUE" ;
VAL_ 1434 ReqRrHVAC_PwrChgRr 0 "FALSE" 1 "TRUE" ;
VAL_ 1434 ReqRrAutoRr 0 "FALSE" 1 "TRUE" ;
VAL_ 1430 HVACFCRADR_RtSet 0 "NoAction" 1 "Auto" 2 "Floor" 3 "FloorAndVent" 4 "Vent" 5 "VentAndRoof" 6 "Roof" 7 "RoofAndFloor" 8 "FloorAndVentAndRoof" ;
VAL_ 1430 HVACFCRADR_RtChgNext 0 "FALSE" 1 "TRUE" ;
VAL_ 1430 HVACFCRADR_LtSet 0 "NoAction" 1 "Auto" 2 "Floor" 3 "FloorAndVent" 4 "Vent" 5 "VentAndRoof" 6 "Roof" 7 "RoofAndFloor" 8 "FloorAndVentAndRoof" ;
VAL_ 1430 HVACFCRADR_LtChgNext 0 "FALSE" 1 "TRUE" ;
VAL_ 1430 HVACFCRACH_CompSetChg 0 "FALSE" 1 "TRUE" ;
VAL_ 1430 HVACFCRACH_HtrSetChg 0 "FALSE" 1 "TRUE" ;
VAL_ 1430 HtdStBckCushStckSwRF 0 "FALSE" 1 "TRUE" ;
VAL_ 1430 HtdStBckCushStckSwLF 0 "FALSE" 1 "TRUE" ;
VAL_ 1430 HVACFCRRA_SetChg 0 "FALSE" 1 "TRUE" ;
VAL_ 1431 HVACFCRBLR_LvlActv 0 "FALSE" 1 "TRUE" ;
VAL_ 1431 HVACFCRRD_SetChg 0 "FALSE" 1 "TRUE" ;
VAL_ 1431 HVACFCRRP_SetChg 0 "FALSE" 1 "TRUE" ;
VAL_ 1431 VntStStckSwLF 0 "FALSE" 1 "TRUE" ;
VAL_ 1431 HtdVntStSwActvRF 0 "FALSE" 1 "TRUE" ;
VAL_ 1431 HtdVntStSwActvLF 0 "FALSE" 1 "TRUE" ;
VAL_ 1431 HtdStBckStckSwRF 0 "FALSE" 1 "TRUE" ;
VAL_ 1431 HtdStBckStckSwLF 0 "FALSE" 1 "TRUE" ;
VAL_ 1431 HVACFrtCtlReqSyncRrSetChg 0 "FALSE" 1 "TRUE" ;
VAL_ 1431 HVACFCRSA_SetChg 0 "FALSE" 1 "TRUE" ;
